VERSION ""

NS_ :

BS_:

BU_: BMS HVB BMU

BO_ 2282618902 BMU22_Vol_57: 8 BMU
 SG_ BMU22_Vol_57 : 7|16@0+ (0.001,0) [1|1] "V"  BMS
 SG_ BMU22_Vol_58 : 23|16@0+ (0.001,0) [1|1] "V"  BMS
 SG_ BMU22_Vol_59 : 39|16@0+ (0.001,0) [1|1] "V"  BMS
 SG_ BMU22_Vol_60 : 55|16@0+ (0.001,0) [1|1] "V"  BMS

BO_ 2282684438 BMU22_Vol_61: 8 BMU
 SG_ BMU22_Vol_61 : 7|16@0+ (0.001,0) [1|1] "V"  BMS
 SG_ BMU22_Vol_62 : 23|16@0+ (0.001,0) [1|1] "V"  BMS
 SG_ BMU22_Vol_63 : 39|16@0+ (0.001,0) [1|1] "V"  BMS
 SG_ BMU22_Vol_64 : 55|16@0+ (0.001,0) [1|1] "V"  BMS

BO_ 2282749974 BMU22_Vol_65: 8 BMU
 SG_ BMU22_Vol_65 : 7|16@0+ (0.001,0) [1|1] "V"  BMS
 SG_ BMU22_Vol_66 : 23|16@0+ (0.001,0) [1|1] "V"  BMS
 SG_ BMU22_Vol_67 : 39|16@0+ (0.001,0) [1|1] "V"  BMS
 SG_ BMU22_Vol_68 : 55|16@0+ (0.001,0) [1|1] "V"  BMS

BO_ 2282815510 BMU22_Vol_69: 8 BMU
 SG_ BMU22_Vol_69 : 7|16@0+ (0.001,0) [1|1] "V"  BMS
 SG_ BMU22_Vol_70 : 23|16@0+ (0.001,0) [1|1] "V"  BMS
 SG_ BMU22_Vol_71 : 39|16@0+ (0.001,0) [1|1] "V"  BMS
 SG_ BMU22_Vol_72 : 55|16@0+ (0.001,0) [1|1] "V"  BMS

BO_ 2282881046 BMU22_Vol_73: 8 BMU
 SG_ BMU22_Vol_73 : 7|16@0+ (0.001,0) [1|1] "V"  BMS
 SG_ BMU22_Vol_74 : 23|16@0+ (0.001,0) [1|1] "V"  BMS
 SG_ BMU22_Vol_75 : 39|16@0+ (0.001,0) [1|1] "V"  BMS
 SG_ BMU22_Vol_76 : 55|16@0+ (0.001,0) [1|1] "V"  BMS

BO_ 2282946582 BMU22_Vol_77: 8 BMU
 SG_ BMU22_Vol_77 : 7|16@0+ (0.001,0) [1|1] "V"  BMS
 SG_ BMU22_Vol_78 : 23|16@0+ (0.001,0) [1|1] "V"  BMS
 SG_ BMU22_Vol_79 : 39|16@0+ (0.001,0) [1|1] "V"  BMS
 SG_ BMU22_Vol_80 : 55|16@0+ (0.001,0) [1|1] "V"  BMS

BO_ 2283012118 BMU22_Vol_81: 8 BMU
 SG_ BMU22_Vol_81 : 7|16@0+ (0.001,0) [1|1] "V"  BMS
 SG_ BMU22_Vol_82 : 23|16@0+ (0.001,0) [1|1] "V"  BMS
 SG_ BMU22_Vol_83 : 39|16@0+ (0.001,0) [1|1] "V"  BMS
 SG_ BMU22_Vol_84 : 55|16@0+ (0.001,0) [1|1] "V"  BMS

BO_ 2283077654 BMU22_Vol_85: 8 BMU
 SG_ BMU22_Vol_85 : 7|16@0+ (0.001,0) [1|1] "V"  BMS
 SG_ BMU22_Vol_86 : 23|16@0+ (0.001,0) [1|1] "V"  BMS
 SG_ BMU22_Vol_87 : 39|16@0+ (0.001,0) [1|1] "V"  BMS
 SG_ BMU22_Vol_88 : 55|16@0+ (0.001,0) [1|1] "V"  BMS

BO_ 2283143190 BMU22_Vol_89: 8 BMU
 SG_ BMU22_Vol_89 : 7|16@0+ (0.001,0) [1|1] "V"  BMS
 SG_ BMU22_Vol_90 : 23|16@0+ (0.001,0) [1|1] "V"  BMS
 SG_ BMU22_Vol_91 : 39|16@0+ (0.001,0) [1|1] "V"  BMS
 SG_ BMU22_Vol_92 : 55|16@0+ (0.001,0) [1|1] "V"  BMS

BO_ 2283208726 BMU22_Vol_93: 8 BMU
 SG_ BMU22_Vol_93 : 7|16@0+ (0.001,0) [1|1] "V"  BMS
 SG_ BMU22_Vol_94 : 23|16@0+ (0.001,0) [1|1] "V"  BMS
 SG_ BMU22_Vol_95 : 39|16@0+ (0.001,0) [1|1] "V"  BMS
 SG_ BMU22_Vol_96 : 55|16@0+ (0.001,0) [1|1] "V"  BMS

BO_ 2281701399 BMU23_Vol_1: 8 BMU
 SG_ BMU23_Vol_1 : 7|16@0+ (0.001,0) [1|1] "V"  BMS
 SG_ BMU23_Vol_2 : 23|16@0+ (0.001,0) [1|1] "V"  BMS
 SG_ BMU23_Vol_3 : 39|16@0+ (0.001,0) [1|1] "V"  BMS
 SG_ BMU23_Vol_4 : 55|16@0+ (0.001,0) [1|1] "V"  BMS

BO_ 2281766935 BMU23_Vol_5: 8 BMU
 SG_ BMU23_Vol_5 : 7|16@0+ (0.001,0) [1|1] "V"  BMS
 SG_ BMU23_Vol_6 : 23|16@0+ (0.001,0) [1|1] "V"  BMS
 SG_ BMU23_Vol_7 : 39|16@0+ (0.001,0) [1|1] "V"  BMS
 SG_ BMU23_Vol_8 : 55|16@0+ (0.001,0) [1|1] "V"  BMS

BO_ 2281832471 BMU23_Vol_9: 8 BMU
 SG_ BMU23_Vol_9 : 7|16@0+ (0.001,0) [1|1] "V"  BMS
 SG_ BMU23_Vol_10 : 23|16@0+ (0.001,0) [1|1] "V"  BMS
 SG_ BMU23_Vol_11 : 39|16@0+ (0.001,0) [1|1] "V"  BMS
 SG_ BMU23_Vol_12 : 55|16@0+ (0.001,0) [1|1] "V"  BMS

BO_ 2281898007 BMU23_Vol_13: 8 BMU
 SG_ BMU23_Vol_13 : 7|16@0+ (0.001,0) [1|1] "V"  BMS
 SG_ BMU23_Vol_14 : 23|16@0+ (0.001,0) [1|1] "V"  BMS
 SG_ BMU23_Vol_15 : 39|16@0+ (0.001,0) [1|1] "V"  BMS
 SG_ BMU23_Vol_16 : 55|16@0+ (0.001,0) [1|1] "V"  BMS

BO_ 2281963543 BMU23_Vol_17: 8 BMU
 SG_ BMU23_Vol_17 : 7|16@0+ (0.001,0) [1|1] "V"  BMS
 SG_ BMU23_Vol_18 : 23|16@0+ (0.001,0) [1|1] "V"  BMS
 SG_ BMU23_Vol_19 : 39|16@0+ (0.001,0) [1|1] "V"  BMS
 SG_ BMU23_Vol_20 : 55|16@0+ (0.001,0) [1|1] "V"  BMS

BO_ 2282029079 BMU23_Vol_21: 8 BMU
 SG_ BMU23_Vol_21 : 7|16@0+ (0.001,0) [1|1] "V"  BMS
 SG_ BMU23_Vol_22 : 23|16@0+ (0.001,0) [1|1] "V"  BMS
 SG_ BMU23_Vol_23 : 39|16@0+ (0.001,0) [1|1] "V"  BMS
 SG_ BMU23_Vol_24 : 55|16@0+ (0.001,0) [1|1] "V"  BMS

BO_ 2282094615 BMU23_Vol_25: 8 BMU
 SG_ BMU23_Vol_25 : 7|16@0+ (0.001,0) [1|1] "V"  BMS
 SG_ BMU23_Vol_26 : 23|16@0+ (0.001,0) [1|1] "V"  BMS
 SG_ BMU23_Vol_27 : 39|16@0+ (0.001,0) [1|1] "V"  BMS
 SG_ BMU23_Vol_28 : 55|16@0+ (0.001,0) [1|1] "V"  BMS

BO_ 2282160151 BMU23_Vol_29: 8 BMU
 SG_ BMU23_Vol_29 : 7|16@0+ (0.001,0) [1|1] "V"  BMS
 SG_ BMU23_Vol_30 : 23|16@0+ (0.001,0) [1|1] "V"  BMS
 SG_ BMU23_Vol_31 : 39|16@0+ (0.001,0) [1|1] "V"  BMS
 SG_ BMU23_Vol_32 : 55|16@0+ (0.001,0) [1|1] "V"  BMS

BO_ 2282225687 BMU23_Vol_33: 8 BMU
 SG_ BMU23_Vol_33 : 7|16@0+ (0.001,0) [1|1] "V"  BMS
 SG_ BMU23_Vol_34 : 23|16@0+ (0.001,0) [1|1] "V"  BMS
 SG_ BMU23_Vol_35 : 39|16@0+ (0.001,0) [1|1] "V"  BMS
 SG_ BMU23_Vol_36 : 55|16@0+ (0.001,0) [1|1] "V"  BMS

BO_ 2282291223 BMU23_Vol_37: 8 BMU
 SG_ BMU23_Vol_37 : 7|16@0+ (0.001,0) [1|1] "V"  BMS
 SG_ BMU23_Vol_38 : 23|16@0+ (0.001,0) [1|1] "V"  BMS
 SG_ BMU23_Vol_39 : 39|16@0+ (0.001,0) [1|1] "V"  BMS
 SG_ BMU23_Vol_40 : 55|16@0+ (0.001,0) [1|1] "V"  BMS

BO_ 2282356759 BMU23_Vol_41: 8 BMU
 SG_ BMU23_Vol_41 : 7|16@0+ (0.001,0) [1|1] "V"  BMS
 SG_ BMU23_Vol_42 : 23|16@0+ (0.001,0) [1|1] "V"  BMS
 SG_ BMU23_Vol_43 : 39|16@0+ (0.001,0) [1|1] "V"  BMS
 SG_ BMU23_Vol_44 : 55|16@0+ (0.001,0) [1|1] "V"  BMS

BO_ 2282422295 BMU23_Vol_45: 8 BMU
 SG_ BMU23_Vol_45 : 7|16@0+ (0.001,0) [1|1] "V"  BMS
 SG_ BMU23_Vol_46 : 23|16@0+ (0.001,0) [1|1] "V"  BMS
 SG_ BMU23_Vol_47 : 39|16@0+ (0.001,0) [1|1] "V"  BMS
 SG_ BMU23_Vol_48 : 55|16@0+ (0.001,0) [1|1] "V"  BMS

BO_ 2282487831 BMU23_Vol_49: 8 BMU
 SG_ BMU23_Vol_49 : 7|16@0+ (0.001,0) [1|1] "V"  BMS
 SG_ BMU23_Vol_50 : 23|16@0+ (0.001,0) [1|1] "V"  BMS
 SG_ BMU23_Vol_51 : 39|16@0+ (0.001,0) [1|1] "V"  BMS
 SG_ BMU23_Vol_52 : 55|16@0+ (0.001,0) [1|1] "V"  BMS

BO_ 2282553367 BMU23_Vol_53: 8 BMU
 SG_ BMU23_Vol_53 : 7|16@0+ (0.001,0) [1|1] "V"  BMS
 SG_ BMU23_Vol_54 : 23|16@0+ (0.001,0) [1|1] "V"  BMS
 SG_ BMU23_Vol_55 : 39|16@0+ (0.001,0) [1|1] "V"  BMS
 SG_ BMU23_Vol_56 : 55|16@0+ (0.001,0) [1|1] "V"  BMS

BO_ 2282618903 BMU23_Vol_57: 8 BMU
 SG_ BMU23_Vol_57 : 7|16@0+ (0.001,0) [1|1] "V"  BMS
 SG_ BMU23_Vol_58 : 23|16@0+ (0.001,0) [1|1] "V"  BMS
 SG_ BMU23_Vol_59 : 39|16@0+ (0.001,0) [1|1] "V"  BMS
 SG_ BMU23_Vol_60 : 55|16@0+ (0.001,0) [1|1] "V"  BMS

BO_ 2282684439 BMU23_Vol_61: 8 BMU
 SG_ BMU23_Vol_61 : 7|16@0+ (0.001,0) [1|1] "V"  BMS
 SG_ BMU23_Vol_62 : 23|16@0+ (0.001,0) [1|1] "V"  BMS
 SG_ BMU23_Vol_63 : 39|16@0+ (0.001,0) [1|1] "V"  BMS
 SG_ BMU23_Vol_64 : 55|16@0+ (0.001,0) [1|1] "V"  BMS

BO_ 2282749975 BMU23_Vol_65: 8 BMU
 SG_ BMU23_Vol_65 : 7|16@0+ (0.001,0) [1|1] "V"  BMS
 SG_ BMU23_Vol_66 : 23|16@0+ (0.001,0) [1|1] "V"  BMS
 SG_ BMU23_Vol_67 : 39|16@0+ (0.001,0) [1|1] "V"  BMS
 SG_ BMU23_Vol_68 : 55|16@0+ (0.001,0) [1|1] "V"  BMS

BO_ 2282815511 BMU23_Vol_69: 8 BMU
 SG_ BMU23_Vol_69 : 7|16@0+ (0.001,0) [1|1] "V"  BMS
 SG_ BMU23_Vol_70 : 23|16@0+ (0.001,0) [1|1] "V"  BMS
 SG_ BMU23_Vol_71 : 39|16@0+ (0.001,0) [1|1] "V"  BMS
 SG_ BMU23_Vol_72 : 55|16@0+ (0.001,0) [1|1] "V"  BMS

BO_ 2282881047 BMU23_Vol_73: 8 BMU
 SG_ BMU23_Vol_73 : 7|16@0+ (0.001,0) [1|1] "V"  BMS
 SG_ BMU23_Vol_74 : 23|16@0+ (0.001,0) [1|1] "V"  BMS
 SG_ BMU23_Vol_75 : 39|16@0+ (0.001,0) [1|1] "V"  BMS
 SG_ BMU23_Vol_76 : 55|16@0+ (0.001,0) [1|1] "V"  BMS

BO_ 2282946583 BMU23_Vol_77: 8 BMU
 SG_ BMU23_Vol_77 : 7|16@0+ (0.001,0) [1|1] "V"  BMS
 SG_ BMU23_Vol_78 : 23|16@0+ (0.001,0) [1|1] "V"  BMS
 SG_ BMU23_Vol_79 : 39|16@0+ (0.001,0) [1|1] "V"  BMS
 SG_ BMU23_Vol_80 : 55|16@0+ (0.001,0) [1|1] "V"  BMS

BO_ 2283012119 BMU23_Vol_81: 8 BMU
 SG_ BMU23_Vol_81 : 7|16@0+ (0.001,0) [1|1] "V"  BMS
 SG_ BMU23_Vol_82 : 23|16@0+ (0.001,0) [1|1] "V"  BMS
 SG_ BMU23_Vol_83 : 39|16@0+ (0.001,0) [1|1] "V"  BMS
 SG_ BMU23_Vol_84 : 55|16@0+ (0.001,0) [1|1] "V"  BMS

BO_ 2283077655 BMU23_Vol_85: 8 BMU
 SG_ BMU23_Vol_85 : 7|16@0+ (0.001,0) [1|1] "V"  BMS
 SG_ BMU23_Vol_86 : 23|16@0+ (0.001,0) [1|1] "V"  BMS
 SG_ BMU23_Vol_87 : 39|16@0+ (0.001,0) [1|1] "V"  BMS
 SG_ BMU23_Vol_88 : 55|16@0+ (0.001,0) [1|1] "V"  BMS

BO_ 2283143191 BMU23_Vol_89: 8 BMU
 SG_ BMU23_Vol_89 : 7|16@0+ (0.001,0) [1|1] "V"  BMS
 SG_ BMU23_Vol_90 : 23|16@0+ (0.001,0) [1|1] "V"  BMS
 SG_ BMU23_Vol_91 : 39|16@0+ (0.001,0) [1|1] "V"  BMS
 SG_ BMU23_Vol_92 : 55|16@0+ (0.001,0) [1|1] "V"  BMS

BO_ 2283208727 BMU23_Vol_93: 8 BMU
 SG_ BMU23_Vol_93 : 7|16@0+ (0.001,0) [1|1] "V"  BMS
 SG_ BMU23_Vol_94 : 23|16@0+ (0.001,0) [1|1] "V"  BMS
 SG_ BMU23_Vol_95 : 39|16@0+ (0.001,0) [1|1] "V"  BMS
 SG_ BMU23_Vol_96 : 55|16@0+ (0.001,0) [1|1] "V"  BMS

BO_ 2281701400 BMU24_Vol_1: 8 BMU
 SG_ BMU24_Vol_1 : 7|16@0+ (0.001,0) [1|1] "V"  BMS
 SG_ BMU24_Vol_2 : 23|16@0+ (0.001,0) [1|1] "V"  BMS
 SG_ BMU24_Vol_3 : 39|16@0+ (0.001,0) [1|1] "V"  BMS
 SG_ BMU24_Vol_4 : 55|16@0+ (0.001,0) [1|1] "V"  BMS

BO_ 2281766936 BMU24_Vol_5: 8 BMU
 SG_ BMU24_Vol_5 : 7|16@0+ (0.001,0) [1|1] "V"  BMS
 SG_ BMU24_Vol_6 : 23|16@0+ (0.001,0) [1|1] "V"  BMS
 SG_ BMU24_Vol_7 : 39|16@0+ (0.001,0) [1|1] "V"  BMS
 SG_ BMU24_Vol_8 : 55|16@0+ (0.001,0) [1|1] "V"  BMS

BO_ 2281832472 BMU24_Vol_9: 8 BMU
 SG_ BMU24_Vol_9 : 7|16@0+ (0.001,0) [1|1] "V"  BMS
 SG_ BMU24_Vol_10 : 23|16@0+ (0.001,0) [1|1] "V"  BMS
 SG_ BMU24_Vol_11 : 39|16@0+ (0.001,0) [1|1] "V"  BMS
 SG_ BMU24_Vol_12 : 55|16@0+ (0.001,0) [1|1] "V"  BMS

BO_ 2281898008 BMU24_Vol_13: 8 BMU
 SG_ BMU24_Vol_13 : 7|16@0+ (0.001,0) [1|1] "V"  BMS
 SG_ BMU24_Vol_14 : 23|16@0+ (0.001,0) [1|1] "V"  BMS
 SG_ BMU24_Vol_15 : 39|16@0+ (0.001,0) [1|1] "V"  BMS
 SG_ BMU24_Vol_16 : 55|16@0+ (0.001,0) [1|1] "V"  BMS

BO_ 2281963544 BMU24_Vol_17: 8 BMU
 SG_ BMU24_Vol_17 : 7|16@0+ (0.001,0) [1|1] "V"  BMS
 SG_ BMU24_Vol_18 : 23|16@0+ (0.001,0) [1|1] "V"  BMS
 SG_ BMU24_Vol_19 : 39|16@0+ (0.001,0) [1|1] "V"  BMS
 SG_ BMU24_Vol_20 : 55|16@0+ (0.001,0) [1|1] "V"  BMS

BO_ 2282029080 BMU24_Vol_21: 8 BMU
 SG_ BMU24_Vol_21 : 7|16@0+ (0.001,0) [1|1] "V"  BMS
 SG_ BMU24_Vol_22 : 23|16@0+ (0.001,0) [1|1] "V"  BMS
 SG_ BMU24_Vol_23 : 39|16@0+ (0.001,0) [1|1] "V"  BMS
 SG_ BMU24_Vol_24 : 55|16@0+ (0.001,0) [1|1] "V"  BMS

BO_ 2282094616 BMU24_Vol_25: 8 BMU
 SG_ BMU24_Vol_25 : 7|16@0+ (0.001,0) [1|1] "V"  BMS
 SG_ BMU24_Vol_26 : 23|16@0+ (0.001,0) [1|1] "V"  BMS
 SG_ BMU24_Vol_27 : 39|16@0+ (0.001,0) [1|1] "V"  BMS
 SG_ BMU24_Vol_28 : 55|16@0+ (0.001,0) [1|1] "V"  BMS

BO_ 2282160152 BMU24_Vol_29: 8 BMU
 SG_ BMU24_Vol_29 : 7|16@0+ (0.001,0) [1|1] "V"  BMS
 SG_ BMU24_Vol_30 : 23|16@0+ (0.001,0) [1|1] "V"  BMS
 SG_ BMU24_Vol_31 : 39|16@0+ (0.001,0) [1|1] "V"  BMS
 SG_ BMU24_Vol_32 : 55|16@0+ (0.001,0) [1|1] "V"  BMS

BO_ 2282225688 BMU24_Vol_33: 8 BMU
 SG_ BMU24_Vol_33 : 7|16@0+ (0.001,0) [1|1] "V"  BMS
 SG_ BMU24_Vol_34 : 23|16@0+ (0.001,0) [1|1] "V"  BMS
 SG_ BMU24_Vol_35 : 39|16@0+ (0.001,0) [1|1] "V"  BMS
 SG_ BMU24_Vol_36 : 55|16@0+ (0.001,0) [1|1] "V"  BMS

BO_ 2282291224 BMU24_Vol_37: 8 BMU
 SG_ BMU24_Vol_37 : 7|16@0+ (0.001,0) [1|1] "V"  BMS
 SG_ BMU24_Vol_38 : 23|16@0+ (0.001,0) [1|1] "V"  BMS
 SG_ BMU24_Vol_39 : 39|16@0+ (0.001,0) [1|1] "V"  BMS
 SG_ BMU24_Vol_40 : 55|16@0+ (0.001,0) [1|1] "V"  BMS

BO_ 2282356760 BMU24_Vol_41: 8 BMU
 SG_ BMU24_Vol_41 : 7|16@0+ (0.001,0) [1|1] "V"  BMS
 SG_ BMU24_Vol_42 : 23|16@0+ (0.001,0) [1|1] "V"  BMS
 SG_ BMU24_Vol_43 : 39|16@0+ (0.001,0) [1|1] "V"  BMS
 SG_ BMU24_Vol_44 : 55|16@0+ (0.001,0) [1|1] "V"  BMS

BO_ 2282422296 BMU24_Vol_45: 8 BMU
 SG_ BMU24_Vol_45 : 7|16@0+ (0.001,0) [1|1] "V"  BMS
 SG_ BMU24_Vol_46 : 23|16@0+ (0.001,0) [1|1] "V"  BMS
 SG_ BMU24_Vol_47 : 39|16@0+ (0.001,0) [1|1] "V"  BMS
 SG_ BMU24_Vol_48 : 55|16@0+ (0.001,0) [1|1] "V"  BMS

BO_ 2282487832 BMU24_Vol_49: 8 BMU
 SG_ BMU24_Vol_49 : 7|16@0+ (0.001,0) [1|1] "V"  BMS
 SG_ BMU24_Vol_50 : 23|16@0+ (0.001,0) [1|1] "V"  BMS
 SG_ BMU24_Vol_51 : 39|16@0+ (0.001,0) [1|1] "V"  BMS
 SG_ BMU24_Vol_52 : 55|16@0+ (0.001,0) [1|1] "V"  BMS

BO_ 2282553368 BMU24_Vol_53: 8 BMU
 SG_ BMU24_Vol_53 : 7|16@0+ (0.001,0) [1|1] "V"  BMS
 SG_ BMU24_Vol_54 : 23|16@0+ (0.001,0) [1|1] "V"  BMS
 SG_ BMU24_Vol_55 : 39|16@0+ (0.001,0) [1|1] "V"  BMS
 SG_ BMU24_Vol_56 : 55|16@0+ (0.001,0) [1|1] "V"  BMS

BO_ 2282618904 BMU24_Vol_57: 8 BMU
 SG_ BMU24_Vol_57 : 7|16@0+ (0.001,0) [1|1] "V"  BMS
 SG_ BMU24_Vol_58 : 23|16@0+ (0.001,0) [1|1] "V"  BMS
 SG_ BMU24_Vol_59 : 39|16@0+ (0.001,0) [1|1] "V"  BMS
 SG_ BMU24_Vol_60 : 55|16@0+ (0.001,0) [1|1] "V"  BMS

BO_ 2282684440 BMU24_Vol_61: 8 BMU
 SG_ BMU24_Vol_61 : 7|16@0+ (0.001,0) [1|1] "V"  BMS
 SG_ BMU24_Vol_62 : 23|16@0+ (0.001,0) [1|1] "V"  BMS
 SG_ BMU24_Vol_63 : 39|16@0+ (0.001,0) [1|1] "V"  BMS
 SG_ BMU24_Vol_64 : 55|16@0+ (0.001,0) [1|1] "V"  BMS

BO_ 2282749976 BMU24_Vol_65: 8 BMU
 SG_ BMU24_Vol_65 : 7|16@0+ (0.001,0) [1|1] "V"  BMS
 SG_ BMU24_Vol_66 : 23|16@0+ (0.001,0) [1|1] "V"  BMS
 SG_ BMU24_Vol_67 : 39|16@0+ (0.001,0) [1|1] "V"  BMS
 SG_ BMU24_Vol_68 : 55|16@0+ (0.001,0) [1|1] "V"  BMS

BO_ 2282815512 BMU24_Vol_69: 8 BMU
 SG_ BMU24_Vol_69 : 7|16@0+ (0.001,0) [1|1] "V"  BMS
 SG_ BMU24_Vol_70 : 23|16@0+ (0.001,0) [1|1] "V"  BMS
 SG_ BMU24_Vol_71 : 39|16@0+ (0.001,0) [1|1] "V"  BMS
 SG_ BMU24_Vol_72 : 55|16@0+ (0.001,0) [1|1] "V"  BMS

BO_ 2282881048 BMU24_Vol_73: 8 BMU
 SG_ BMU24_Vol_73 : 7|16@0+ (0.001,0) [1|1] "V"  BMS
 SG_ BMU24_Vol_74 : 23|16@0+ (0.001,0) [1|1] "V"  BMS
 SG_ BMU24_Vol_75 : 39|16@0+ (0.001,0) [1|1] "V"  BMS
 SG_ BMU24_Vol_76 : 55|16@0+ (0.001,0) [1|1] "V"  BMS

BO_ 2282946584 BMU24_Vol_77: 8 BMU
 SG_ BMU24_Vol_77 : 7|16@0+ (0.001,0) [1|1] "V"  BMS
 SG_ BMU24_Vol_78 : 23|16@0+ (0.001,0) [1|1] "V"  BMS
 SG_ BMU24_Vol_79 : 39|16@0+ (0.001,0) [1|1] "V"  BMS
 SG_ BMU24_Vol_80 : 55|16@0+ (0.001,0) [1|1] "V"  BMS

BO_ 2283012120 BMU24_Vol_81: 8 BMU
 SG_ BMU24_Vol_81 : 7|16@0+ (0.001,0) [1|1] "V"  BMS
 SG_ BMU24_Vol_82 : 23|16@0+ (0.001,0) [1|1] "V"  BMS
 SG_ BMU24_Vol_83 : 39|16@0+ (0.001,0) [1|1] "V"  BMS
 SG_ BMU24_Vol_84 : 55|16@0+ (0.001,0) [1|1] "V"  BMS

BO_ 2283077656 BMU24_Vol_85: 8 BMU
 SG_ BMU24_Vol_85 : 7|16@0+ (0.001,0) [1|1] "V"  BMS
 SG_ BMU24_Vol_86 : 23|16@0+ (0.001,0) [1|1] "V"  BMS
 SG_ BMU24_Vol_87 : 39|16@0+ (0.001,0) [1|1] "V"  BMS
 SG_ BMU24_Vol_88 : 55|16@0+ (0.001,0) [1|1] "V"  BMS

BO_ 2283143192 BMU24_Vol_89: 8 BMU
 SG_ BMU24_Vol_89 : 7|16@0+ (0.001,0) [1|1] "V"  BMS
 SG_ BMU24_Vol_90 : 23|16@0+ (0.001,0) [1|1] "V"  BMS
 SG_ BMU24_Vol_91 : 39|16@0+ (0.001,0) [1|1] "V"  BMS
 SG_ BMU24_Vol_92 : 55|16@0+ (0.001,0) [1|1] "V"  BMS

BO_ 2283208728 BMU24_Vol_93: 8 BMU
 SG_ BMU24_Vol_93 : 7|16@0+ (0.001,0) [1|1] "V"  BMS
 SG_ BMU24_Vol_94 : 23|16@0+ (0.001,0) [1|1] "V"  BMS
 SG_ BMU24_Vol_95 : 39|16@0+ (0.001,0) [1|1] "V"  BMS
 SG_ BMU24_Vol_96 : 55|16@0+ (0.001,0) [1|1] "V"  BMS

BO_ 2281701401 BMU25_Vol_1: 8 BMU
 SG_ BMU25_Vol_1 : 7|16@0+ (0.001,0) [1|1] "V"  BMS
 SG_ BMU25_Vol_2 : 23|16@0+ (0.001,0) [1|1] "V"  BMS
 SG_ BMU25_Vol_3 : 39|16@0+ (0.001,0) [1|1] "V"  BMS
 SG_ BMU25_Vol_4 : 55|16@0+ (0.001,0) [1|1] "V"  BMS

BO_ 2281766937 BMU25_Vol_5: 8 BMU
 SG_ BMU25_Vol_5 : 7|16@0+ (0.001,0) [1|1] "V"  BMS
 SG_ BMU25_Vol_6 : 23|16@0+ (0.001,0) [1|1] "V"  BMS
 SG_ BMU25_Vol_7 : 39|16@0+ (0.001,0) [1|1] "V"  BMS
 SG_ BMU25_Vol_8 : 55|16@0+ (0.001,0) [1|1] "V"  BMS

BO_ 2281832473 BMU25_Vol_9: 8 BMU
 SG_ BMU25_Vol_9 : 7|16@0+ (0.001,0) [1|1] "V"  BMS
 SG_ BMU25_Vol_10 : 23|16@0+ (0.001,0) [1|1] "V"  BMS
 SG_ BMU25_Vol_11 : 39|16@0+ (0.001,0) [1|1] "V"  BMS
 SG_ BMU25_Vol_12 : 55|16@0+ (0.001,0) [1|1] "V"  BMS

BO_ 2281898009 BMU25_Vol_13: 8 BMU
 SG_ BMU25_Vol_13 : 7|16@0+ (0.001,0) [1|1] "V"  BMS
 SG_ BMU25_Vol_14 : 23|16@0+ (0.001,0) [1|1] "V"  BMS
 SG_ BMU25_Vol_15 : 39|16@0+ (0.001,0) [1|1] "V"  BMS
 SG_ BMU25_Vol_16 : 55|16@0+ (0.001,0) [1|1] "V"  BMS

BO_ 2281963545 BMU25_Vol_17: 8 BMU
 SG_ BMU25_Vol_17 : 7|16@0+ (0.001,0) [1|1] "V"  BMS
 SG_ BMU25_Vol_18 : 23|16@0+ (0.001,0) [1|1] "V"  BMS
 SG_ BMU25_Vol_19 : 39|16@0+ (0.001,0) [1|1] "V"  BMS
 SG_ BMU25_Vol_20 : 55|16@0+ (0.001,0) [1|1] "V"  BMS

BO_ 2282029081 BMU25_Vol_21: 8 BMU
 SG_ BMU25_Vol_21 : 7|16@0+ (0.001,0) [1|1] "V"  BMS
 SG_ BMU25_Vol_22 : 23|16@0+ (0.001,0) [1|1] "V"  BMS
 SG_ BMU25_Vol_23 : 39|16@0+ (0.001,0) [1|1] "V"  BMS
 SG_ BMU25_Vol_24 : 55|16@0+ (0.001,0) [1|1] "V"  BMS

BO_ 2282094617 BMU25_Vol_25: 8 BMU
 SG_ BMU25_Vol_25 : 7|16@0+ (0.001,0) [1|1] "V"  BMS
 SG_ BMU25_Vol_26 : 23|16@0+ (0.001,0) [1|1] "V"  BMS
 SG_ BMU25_Vol_27 : 39|16@0+ (0.001,0) [1|1] "V"  BMS
 SG_ BMU25_Vol_28 : 55|16@0+ (0.001,0) [1|1] "V"  BMS

BO_ 2282160153 BMU25_Vol_29: 8 BMU
 SG_ BMU25_Vol_29 : 7|16@0+ (0.001,0) [1|1] "V"  BMS
 SG_ BMU25_Vol_30 : 23|16@0+ (0.001,0) [1|1] "V"  BMS
 SG_ BMU25_Vol_31 : 39|16@0+ (0.001,0) [1|1] "V"  BMS
 SG_ BMU25_Vol_32 : 55|16@0+ (0.001,0) [1|1] "V"  BMS

BO_ 2282225689 BMU25_Vol_33: 8 BMU
 SG_ BMU25_Vol_33 : 7|16@0+ (0.001,0) [1|1] "V"  BMS
 SG_ BMU25_Vol_34 : 23|16@0+ (0.001,0) [1|1] "V"  BMS
 SG_ BMU25_Vol_35 : 39|16@0+ (0.001,0) [1|1] "V"  BMS
 SG_ BMU25_Vol_36 : 55|16@0+ (0.001,0) [1|1] "V"  BMS

BO_ 2282291225 BMU25_Vol_37: 8 BMU
 SG_ BMU25_Vol_37 : 7|16@0+ (0.001,0) [1|1] "V"  BMS
 SG_ BMU25_Vol_38 : 23|16@0+ (0.001,0) [1|1] "V"  BMS
 SG_ BMU25_Vol_39 : 39|16@0+ (0.001,0) [1|1] "V"  BMS
 SG_ BMU25_Vol_40 : 55|16@0+ (0.001,0) [1|1] "V"  BMS

BO_ 2282356761 BMU25_Vol_41: 8 BMU
 SG_ BMU25_Vol_41 : 7|16@0+ (0.001,0) [1|1] "V"  BMS
 SG_ BMU25_Vol_42 : 23|16@0+ (0.001,0) [1|1] "V"  BMS
 SG_ BMU25_Vol_43 : 39|16@0+ (0.001,0) [1|1] "V"  BMS
 SG_ BMU25_Vol_44 : 55|16@0+ (0.001,0) [1|1] "V"  BMS

BO_ 2282422297 BMU25_Vol_45: 8 BMU
 SG_ BMU25_Vol_45 : 7|16@0+ (0.001,0) [1|1] "V"  BMS
 SG_ BMU25_Vol_46 : 23|16@0+ (0.001,0) [1|1] "V"  BMS
 SG_ BMU25_Vol_47 : 39|16@0+ (0.001,0) [1|1] "V"  BMS
 SG_ BMU25_Vol_48 : 55|16@0+ (0.001,0) [1|1] "V"  BMS

BO_ 2282487833 BMU25_Vol_49: 8 BMU
 SG_ BMU25_Vol_49 : 7|16@0+ (0.001,0) [1|1] "V"  BMS
 SG_ BMU25_Vol_50 : 23|16@0+ (0.001,0) [1|1] "V"  BMS
 SG_ BMU25_Vol_51 : 39|16@0+ (0.001,0) [1|1] "V"  BMS
 SG_ BMU25_Vol_52 : 55|16@0+ (0.001,0) [1|1] "V"  BMS

BO_ 2282553369 BMU25_Vol_53: 8 BMU
 SG_ BMU25_Vol_53 : 7|16@0+ (0.001,0) [1|1] "V"  BMS
 SG_ BMU25_Vol_54 : 23|16@0+ (0.001,0) [1|1] "V"  BMS
 SG_ BMU25_Vol_55 : 39|16@0+ (0.001,0) [1|1] "V"  BMS
 SG_ BMU25_Vol_56 : 55|16@0+ (0.001,0) [1|1] "V"  BMS

BO_ 2282618905 BMU25_Vol_57: 8 BMU
 SG_ BMU25_Vol_57 : 7|16@0+ (0.001,0) [1|1] "V"  BMS
 SG_ BMU25_Vol_58 : 23|16@0+ (0.001,0) [1|1] "V"  BMS
 SG_ BMU25_Vol_59 : 39|16@0+ (0.001,0) [1|1] "V"  BMS
 SG_ BMU25_Vol_60 : 55|16@0+ (0.001,0) [1|1] "V"  BMS

BO_ 2282684441 BMU25_Vol_61: 8 BMU
 SG_ BMU25_Vol_61 : 7|16@0+ (0.001,0) [1|1] "V"  BMS
 SG_ BMU25_Vol_62 : 23|16@0+ (0.001,0) [1|1] "V"  BMS
 SG_ BMU25_Vol_63 : 39|16@0+ (0.001,0) [1|1] "V"  BMS
 SG_ BMU25_Vol_64 : 55|16@0+ (0.001,0) [1|1] "V"  BMS

BO_ 2282749977 BMU25_Vol_65: 8 BMU
 SG_ BMU25_Vol_65 : 7|16@0+ (0.001,0) [1|1] "V"  BMS
 SG_ BMU25_Vol_66 : 23|16@0+ (0.001,0) [1|1] "V"  BMS
 SG_ BMU25_Vol_67 : 39|16@0+ (0.001,0) [1|1] "V"  BMS
 SG_ BMU25_Vol_68 : 55|16@0+ (0.001,0) [1|1] "V"  BMS

BO_ 2282815513 BMU25_Vol_69: 8 BMU
 SG_ BMU25_Vol_69 : 7|16@0+ (0.001,0) [1|1] "V"  BMS
 SG_ BMU25_Vol_70 : 23|16@0+ (0.001,0) [1|1] "V"  BMS
 SG_ BMU25_Vol_71 : 39|16@0+ (0.001,0) [1|1] "V"  BMS
 SG_ BMU25_Vol_72 : 55|16@0+ (0.001,0) [1|1] "V"  BMS

BO_ 2282881049 BMU25_Vol_73: 8 BMU
 SG_ BMU25_Vol_73 : 7|16@0+ (0.001,0) [1|1] "V"  BMS
 SG_ BMU25_Vol_74 : 23|16@0+ (0.001,0) [1|1] "V"  BMS
 SG_ BMU25_Vol_75 : 39|16@0+ (0.001,0) [1|1] "V"  BMS
 SG_ BMU25_Vol_76 : 55|16@0+ (0.001,0) [1|1] "V"  BMS

BO_ 2282946585 BMU25_Vol_77: 8 BMU
 SG_ BMU25_Vol_77 : 7|16@0+ (0.001,0) [1|1] "V"  BMS
 SG_ BMU25_Vol_78 : 23|16@0+ (0.001,0) [1|1] "V"  BMS
 SG_ BMU25_Vol_79 : 39|16@0+ (0.001,0) [1|1] "V"  BMS
 SG_ BMU25_Vol_80 : 55|16@0+ (0.001,0) [1|1] "V"  BMS

BO_ 2283012121 BMU25_Vol_81: 8 BMU
 SG_ BMU25_Vol_81 : 7|16@0+ (0.001,0) [1|1] "V"  BMS
 SG_ BMU25_Vol_82 : 23|16@0+ (0.001,0) [1|1] "V"  BMS
 SG_ BMU25_Vol_83 : 39|16@0+ (0.001,0) [1|1] "V"  BMS
 SG_ BMU25_Vol_84 : 55|16@0+ (0.001,0) [1|1] "V"  BMS

BO_ 2283077657 BMU25_Vol_85: 8 BMU
 SG_ BMU25_Vol_85 : 7|16@0+ (0.001,0) [1|1] "V"  BMS
 SG_ BMU25_Vol_86 : 23|16@0+ (0.001,0) [1|1] "V"  BMS
 SG_ BMU25_Vol_87 : 39|16@0+ (0.001,0) [1|1] "V"  BMS
 SG_ BMU25_Vol_88 : 55|16@0+ (0.001,0) [1|1] "V"  BMS

BO_ 2283143193 BMU25_Vol_89: 8 BMU
 SG_ BMU25_Vol_89 : 7|16@0+ (0.001,0) [1|1] "V"  BMS
 SG_ BMU25_Vol_90 : 23|16@0+ (0.001,0) [1|1] "V"  BMS
 SG_ BMU25_Vol_91 : 39|16@0+ (0.001,0) [1|1] "V"  BMS
 SG_ BMU25_Vol_92 : 55|16@0+ (0.001,0) [1|1] "V"  BMS

BO_ 2283208729 BMU25_Vol_93: 8 BMU
 SG_ BMU25_Vol_93 : 7|16@0+ (0.001,0) [1|1] "V"  BMS
 SG_ BMU25_Vol_94 : 23|16@0+ (0.001,0) [1|1] "V"  BMS
 SG_ BMU25_Vol_95 : 39|16@0+ (0.001,0) [1|1] "V"  BMS
 SG_ BMU25_Vol_96 : 55|16@0+ (0.001,0) [1|1] "V"  BMS

BO_ 2281701402 BMU26_Vol_1: 8 BMU
 SG_ BMU26_Vol_1 : 7|16@0+ (0.001,0) [1|1] "V"  BMS
 SG_ BMU26_Vol_2 : 23|16@0+ (0.001,0) [1|1] "V"  BMS
 SG_ BMU26_Vol_3 : 39|16@0+ (0.001,0) [1|1] "V"  BMS
 SG_ BMU26_Vol_4 : 55|16@0+ (0.001,0) [1|1] "V"  BMS

BO_ 2281766938 BMU26_Vol_5: 8 BMU
 SG_ BMU26_Vol_5 : 7|16@0+ (0.001,0) [1|1] "V"  BMS
 SG_ BMU26_Vol_6 : 23|16@0+ (0.001,0) [1|1] "V"  BMS
 SG_ BMU26_Vol_7 : 39|16@0+ (0.001,0) [1|1] "V"  BMS
 SG_ BMU26_Vol_8 : 55|16@0+ (0.001,0) [1|1] "V"  BMS

BO_ 2281832474 BMU26_Vol_9: 8 BMU
 SG_ BMU26_Vol_9 : 7|16@0+ (0.001,0) [1|1] "V"  BMS
 SG_ BMU26_Vol_10 : 23|16@0+ (0.001,0) [1|1] "V"  BMS
 SG_ BMU26_Vol_11 : 39|16@0+ (0.001,0) [1|1] "V"  BMS
 SG_ BMU26_Vol_12 : 55|16@0+ (0.001,0) [1|1] "V"  BMS

BO_ 2281898010 BMU26_Vol_13: 8 BMU
 SG_ BMU26_Vol_13 : 7|16@0+ (0.001,0) [1|1] "V"  BMS
 SG_ BMU26_Vol_14 : 23|16@0+ (0.001,0) [1|1] "V"  BMS
 SG_ BMU26_Vol_15 : 39|16@0+ (0.001,0) [1|1] "V"  BMS
 SG_ BMU26_Vol_16 : 55|16@0+ (0.001,0) [1|1] "V"  BMS

BO_ 2281963546 BMU26_Vol_17: 8 BMU
 SG_ BMU26_Vol_17 : 7|16@0+ (0.001,0) [1|1] "V"  BMS
 SG_ BMU26_Vol_18 : 23|16@0+ (0.001,0) [1|1] "V"  BMS
 SG_ BMU26_Vol_19 : 39|16@0+ (0.001,0) [1|1] "V"  BMS
 SG_ BMU26_Vol_20 : 55|16@0+ (0.001,0) [1|1] "V"  BMS

BO_ 2282029082 BMU26_Vol_21: 8 BMU
 SG_ BMU26_Vol_21 : 7|16@0+ (0.001,0) [1|1] "V"  BMS
 SG_ BMU26_Vol_22 : 23|16@0+ (0.001,0) [1|1] "V"  BMS
 SG_ BMU26_Vol_23 : 39|16@0+ (0.001,0) [1|1] "V"  BMS
 SG_ BMU26_Vol_24 : 55|16@0+ (0.001,0) [1|1] "V"  BMS

BO_ 2282094618 BMU26_Vol_25: 8 BMU
 SG_ BMU26_Vol_25 : 7|16@0+ (0.001,0) [1|1] "V"  BMS
 SG_ BMU26_Vol_26 : 23|16@0+ (0.001,0) [1|1] "V"  BMS
 SG_ BMU26_Vol_27 : 39|16@0+ (0.001,0) [1|1] "V"  BMS
 SG_ BMU26_Vol_28 : 55|16@0+ (0.001,0) [1|1] "V"  BMS

BO_ 2282160154 BMU26_Vol_29: 8 BMU
 SG_ BMU26_Vol_29 : 7|16@0+ (0.001,0) [1|1] "V"  BMS
 SG_ BMU26_Vol_30 : 23|16@0+ (0.001,0) [1|1] "V"  BMS
 SG_ BMU26_Vol_31 : 39|16@0+ (0.001,0) [1|1] "V"  BMS
 SG_ BMU26_Vol_32 : 55|16@0+ (0.001,0) [1|1] "V"  BMS

BO_ 2282225690 BMU26_Vol_33: 8 BMU
 SG_ BMU26_Vol_33 : 7|16@0+ (0.001,0) [1|1] "V"  BMS
 SG_ BMU26_Vol_34 : 23|16@0+ (0.001,0) [1|1] "V"  BMS
 SG_ BMU26_Vol_35 : 39|16@0+ (0.001,0) [1|1] "V"  BMS
 SG_ BMU26_Vol_36 : 55|16@0+ (0.001,0) [1|1] "V"  BMS

BO_ 2282291226 BMU26_Vol_37: 8 BMU
 SG_ BMU26_Vol_37 : 7|16@0+ (0.001,0) [1|1] "V"  BMS
 SG_ BMU26_Vol_38 : 23|16@0+ (0.001,0) [1|1] "V"  BMS
 SG_ BMU26_Vol_39 : 39|16@0+ (0.001,0) [1|1] "V"  BMS
 SG_ BMU26_Vol_40 : 55|16@0+ (0.001,0) [1|1] "V"  BMS

BO_ 2282356762 BMU26_Vol_41: 8 BMU
 SG_ BMU26_Vol_41 : 7|16@0+ (0.001,0) [1|1] "V"  BMS
 SG_ BMU26_Vol_42 : 23|16@0+ (0.001,0) [1|1] "V"  BMS
 SG_ BMU26_Vol_43 : 39|16@0+ (0.001,0) [1|1] "V"  BMS
 SG_ BMU26_Vol_44 : 55|16@0+ (0.001,0) [1|1] "V"  BMS

BO_ 2282422298 BMU26_Vol_45: 8 BMU
 SG_ BMU26_Vol_45 : 7|16@0+ (0.001,0) [1|1] "V"  BMS
 SG_ BMU26_Vol_46 : 23|16@0+ (0.001,0) [1|1] "V"  BMS
 SG_ BMU26_Vol_47 : 39|16@0+ (0.001,0) [1|1] "V"  BMS
 SG_ BMU26_Vol_48 : 55|16@0+ (0.001,0) [1|1] "V"  BMS

BO_ 2282487834 BMU26_Vol_49: 8 BMU
 SG_ BMU26_Vol_49 : 7|16@0+ (0.001,0) [1|1] "V"  BMS
 SG_ BMU26_Vol_50 : 23|16@0+ (0.001,0) [1|1] "V"  BMS
 SG_ BMU26_Vol_51 : 39|16@0+ (0.001,0) [1|1] "V"  BMS
 SG_ BMU26_Vol_52 : 55|16@0+ (0.001,0) [1|1] "V"  BMS

BO_ 2282553370 BMU26_Vol_53: 8 BMU
 SG_ BMU26_Vol_53 : 7|16@0+ (0.001,0) [1|1] "V"  BMS
 SG_ BMU26_Vol_54 : 23|16@0+ (0.001,0) [1|1] "V"  BMS
 SG_ BMU26_Vol_55 : 39|16@0+ (0.001,0) [1|1] "V"  BMS
 SG_ BMU26_Vol_56 : 55|16@0+ (0.001,0) [1|1] "V"  BMS

BO_ 2282618906 BMU26_Vol_57: 8 BMU
 SG_ BMU26_Vol_57 : 7|16@0+ (0.001,0) [1|1] "V"  BMS
 SG_ BMU26_Vol_58 : 23|16@0+ (0.001,0) [1|1] "V"  BMS
 SG_ BMU26_Vol_59 : 39|16@0+ (0.001,0) [1|1] "V"  BMS
 SG_ BMU26_Vol_60 : 55|16@0+ (0.001,0) [1|1] "V"  BMS

BO_ 2282684442 BMU26_Vol_61: 8 BMU
 SG_ BMU26_Vol_61 : 7|16@0+ (0.001,0) [1|1] "V"  BMS
 SG_ BMU26_Vol_62 : 23|16@0+ (0.001,0) [1|1] "V"  BMS
 SG_ BMU26_Vol_63 : 39|16@0+ (0.001,0) [1|1] "V"  BMS
 SG_ BMU26_Vol_64 : 55|16@0+ (0.001,0) [1|1] "V"  BMS

BO_ 2282749978 BMU26_Vol_65: 8 BMU
 SG_ BMU26_Vol_65 : 7|16@0+ (0.001,0) [1|1] "V"  BMS
 SG_ BMU26_Vol_66 : 23|16@0+ (0.001,0) [1|1] "V"  BMS
 SG_ BMU26_Vol_67 : 39|16@0+ (0.001,0) [1|1] "V"  BMS
 SG_ BMU26_Vol_68 : 55|16@0+ (0.001,0) [1|1] "V"  BMS

BO_ 2282815514 BMU26_Vol_69: 8 BMU
 SG_ BMU26_Vol_69 : 7|16@0+ (0.001,0) [1|1] "V"  BMS
 SG_ BMU26_Vol_70 : 23|16@0+ (0.001,0) [1|1] "V"  BMS
 SG_ BMU26_Vol_71 : 39|16@0+ (0.001,0) [1|1] "V"  BMS
 SG_ BMU26_Vol_72 : 55|16@0+ (0.001,0) [1|1] "V"  BMS

BO_ 2282881050 BMU26_Vol_73: 8 BMU
 SG_ BMU26_Vol_73 : 7|16@0+ (0.001,0) [1|1] "V"  BMS
 SG_ BMU26_Vol_74 : 23|16@0+ (0.001,0) [1|1] "V"  BMS
 SG_ BMU26_Vol_75 : 39|16@0+ (0.001,0) [1|1] "V"  BMS
 SG_ BMU26_Vol_76 : 55|16@0+ (0.001,0) [1|1] "V"  BMS

BO_ 2282946586 BMU26_Vol_77: 8 BMU
 SG_ BMU26_Vol_77 : 7|16@0+ (0.001,0) [1|1] "V"  BMS
 SG_ BMU26_Vol_78 : 23|16@0+ (0.001,0) [1|1] "V"  BMS
 SG_ BMU26_Vol_79 : 39|16@0+ (0.001,0) [1|1] "V"  BMS
 SG_ BMU26_Vol_80 : 55|16@0+ (0.001,0) [1|1] "V"  BMS

BO_ 2283012122 BMU26_Vol_81: 8 BMU
 SG_ BMU26_Vol_81 : 7|16@0+ (0.001,0) [1|1] "V"  BMS
 SG_ BMU26_Vol_82 : 23|16@0+ (0.001,0) [1|1] "V"  BMS
 SG_ BMU26_Vol_83 : 39|16@0+ (0.001,0) [1|1] "V"  BMS
 SG_ BMU26_Vol_84 : 55|16@0+ (0.001,0) [1|1] "V"  BMS

BO_ 2283077658 BMU26_Vol_85: 8 BMU
 SG_ BMU26_Vol_85 : 7|16@0+ (0.001,0) [1|1] "V"  BMS
 SG_ BMU26_Vol_86 : 23|16@0+ (0.001,0) [1|1] "V"  BMS
 SG_ BMU26_Vol_87 : 39|16@0+ (0.001,0) [1|1] "V"  BMS
 SG_ BMU26_Vol_88 : 55|16@0+ (0.001,0) [1|1] "V"  BMS

BO_ 2283143194 BMU26_Vol_89: 8 BMU
 SG_ BMU26_Vol_89 : 7|16@0+ (0.001,0) [1|1] "V"  BMS
 SG_ BMU26_Vol_90 : 23|16@0+ (0.001,0) [1|1] "V"  BMS
 SG_ BMU26_Vol_91 : 39|16@0+ (0.001,0) [1|1] "V"  BMS
 SG_ BMU26_Vol_92 : 55|16@0+ (0.001,0) [1|1] "V"  BMS

BO_ 2283208730 BMU26_Vol_93: 8 BMU
 SG_ BMU26_Vol_93 : 7|16@0+ (0.001,0) [1|1] "V"  BMS
 SG_ BMU26_Vol_94 : 23|16@0+ (0.001,0) [1|1] "V"  BMS
 SG_ BMU26_Vol_95 : 39|16@0+ (0.001,0) [1|1] "V"  BMS
 SG_ BMU26_Vol_96 : 55|16@0+ (0.001,0) [1|1] "V"  BMS

BO_ 2281701403 BMU27_Vol_1: 8 BMU
 SG_ BMU27_Vol_1 : 7|16@0+ (0.001,0) [1|1] "V"  BMS
 SG_ BMU27_Vol_2 : 23|16@0+ (0.001,0) [1|1] "V"  BMS
 SG_ BMU27_Vol_3 : 39|16@0+ (0.001,0) [1|1] "V"  BMS
 SG_ BMU27_Vol_4 : 55|16@0+ (0.001,0) [1|1] "V"  BMS

BO_ 2281766939 BMU27_Vol_5: 8 BMU
 SG_ BMU27_Vol_5 : 7|16@0+ (0.001,0) [1|1] "V"  BMS
 SG_ BMU27_Vol_6 : 23|16@0+ (0.001,0) [1|1] "V"  BMS
 SG_ BMU27_Vol_7 : 39|16@0+ (0.001,0) [1|1] "V"  BMS
 SG_ BMU27_Vol_8 : 55|16@0+ (0.001,0) [1|1] "V"  BMS

BO_ 2281832475 BMU27_Vol_9: 8 BMU
 SG_ BMU27_Vol_9 : 7|16@0+ (0.001,0) [1|1] "V"  BMS
 SG_ BMU27_Vol_10 : 23|16@0+ (0.001,0) [1|1] "V"  BMS
 SG_ BMU27_Vol_11 : 39|16@0+ (0.001,0) [1|1] "V"  BMS
 SG_ BMU27_Vol_12 : 55|16@0+ (0.001,0) [1|1] "V"  BMS

BO_ 2281898011 BMU27_Vol_13: 8 BMU
 SG_ BMU27_Vol_13 : 7|16@0+ (0.001,0) [1|1] "V"  BMS
 SG_ BMU27_Vol_14 : 23|16@0+ (0.001,0) [1|1] "V"  BMS
 SG_ BMU27_Vol_15 : 39|16@0+ (0.001,0) [1|1] "V"  BMS
 SG_ BMU27_Vol_16 : 55|16@0+ (0.001,0) [1|1] "V"  BMS

BO_ 2281963547 BMU27_Vol_17: 8 BMU
 SG_ BMU27_Vol_17 : 7|16@0+ (0.001,0) [1|1] "V"  BMS
 SG_ BMU27_Vol_18 : 23|16@0+ (0.001,0) [1|1] "V"  BMS
 SG_ BMU27_Vol_19 : 39|16@0+ (0.001,0) [1|1] "V"  BMS
 SG_ BMU27_Vol_20 : 55|16@0+ (0.001,0) [1|1] "V"  BMS

BO_ 2282029083 BMU27_Vol_21: 8 BMU
 SG_ BMU27_Vol_21 : 7|16@0+ (0.001,0) [1|1] "V"  BMS
 SG_ BMU27_Vol_22 : 23|16@0+ (0.001,0) [1|1] "V"  BMS
 SG_ BMU27_Vol_23 : 39|16@0+ (0.001,0) [1|1] "V"  BMS
 SG_ BMU27_Vol_24 : 55|16@0+ (0.001,0) [1|1] "V"  BMS

BO_ 2282094619 BMU27_Vol_25: 8 BMU
 SG_ BMU27_Vol_25 : 7|16@0+ (0.001,0) [1|1] "V"  BMS
 SG_ BMU27_Vol_26 : 23|16@0+ (0.001,0) [1|1] "V"  BMS
 SG_ BMU27_Vol_27 : 39|16@0+ (0.001,0) [1|1] "V"  BMS
 SG_ BMU27_Vol_28 : 55|16@0+ (0.001,0) [1|1] "V"  BMS

BO_ 2282160155 BMU27_Vol_29: 8 BMU
 SG_ BMU27_Vol_29 : 7|16@0+ (0.001,0) [1|1] "V"  BMS
 SG_ BMU27_Vol_30 : 23|16@0+ (0.001,0) [1|1] "V"  BMS
 SG_ BMU27_Vol_31 : 39|16@0+ (0.001,0) [1|1] "V"  BMS
 SG_ BMU27_Vol_32 : 55|16@0+ (0.001,0) [1|1] "V"  BMS

BO_ 2282225691 BMU27_Vol_33: 8 BMU
 SG_ BMU27_Vol_33 : 7|16@0+ (0.001,0) [1|1] "V"  BMS
 SG_ BMU27_Vol_34 : 23|16@0+ (0.001,0) [1|1] "V"  BMS
 SG_ BMU27_Vol_35 : 39|16@0+ (0.001,0) [1|1] "V"  BMS
 SG_ BMU27_Vol_36 : 55|16@0+ (0.001,0) [1|1] "V"  BMS

BO_ 2282291227 BMU27_Vol_37: 8 BMU
 SG_ BMU27_Vol_37 : 7|16@0+ (0.001,0) [1|1] "V"  BMS
 SG_ BMU27_Vol_38 : 23|16@0+ (0.001,0) [1|1] "V"  BMS
 SG_ BMU27_Vol_39 : 39|16@0+ (0.001,0) [1|1] "V"  BMS
 SG_ BMU27_Vol_40 : 55|16@0+ (0.001,0) [1|1] "V"  BMS

BO_ 2282356763 BMU27_Vol_41: 8 BMU
 SG_ BMU27_Vol_41 : 7|16@0+ (0.001,0) [1|1] "V"  BMS
 SG_ BMU27_Vol_42 : 23|16@0+ (0.001,0) [1|1] "V"  BMS
 SG_ BMU27_Vol_43 : 39|16@0+ (0.001,0) [1|1] "V"  BMS
 SG_ BMU27_Vol_44 : 55|16@0+ (0.001,0) [1|1] "V"  BMS

BO_ 2282422299 BMU27_Vol_45: 8 BMU
 SG_ BMU27_Vol_45 : 7|16@0+ (0.001,0) [1|1] "V"  BMS
 SG_ BMU27_Vol_46 : 23|16@0+ (0.001,0) [1|1] "V"  BMS
 SG_ BMU27_Vol_47 : 39|16@0+ (0.001,0) [1|1] "V"  BMS
 SG_ BMU27_Vol_48 : 55|16@0+ (0.001,0) [1|1] "V"  BMS

BO_ 2282487835 BMU27_Vol_49: 8 BMU
 SG_ BMU27_Vol_49 : 7|16@0+ (0.001,0) [1|1] "V"  BMS
 SG_ BMU27_Vol_50 : 23|16@0+ (0.001,0) [1|1] "V"  BMS
 SG_ BMU27_Vol_51 : 39|16@0+ (0.001,0) [1|1] "V"  BMS
 SG_ BMU27_Vol_52 : 55|16@0+ (0.001,0) [1|1] "V"  BMS

BO_ 2282553371 BMU27_Vol_53: 8 BMU
 SG_ BMU27_Vol_53 : 7|16@0+ (0.001,0) [1|1] "V"  BMS
 SG_ BMU27_Vol_54 : 23|16@0+ (0.001,0) [1|1] "V"  BMS
 SG_ BMU27_Vol_55 : 39|16@0+ (0.001,0) [1|1] "V"  BMS
 SG_ BMU27_Vol_56 : 55|16@0+ (0.001,0) [1|1] "V"  BMS

BO_ 2282618907 BMU27_Vol_57: 8 BMU
 SG_ BMU27_Vol_57 : 7|16@0+ (0.001,0) [1|1] "V"  BMS
 SG_ BMU27_Vol_58 : 23|16@0+ (0.001,0) [1|1] "V"  BMS
 SG_ BMU27_Vol_59 : 39|16@0+ (0.001,0) [1|1] "V"  BMS
 SG_ BMU27_Vol_60 : 55|16@0+ (0.001,0) [1|1] "V"  BMS

BO_ 2282684443 BMU27_Vol_61: 8 BMU
 SG_ BMU27_Vol_61 : 7|16@0+ (0.001,0) [1|1] "V"  BMS
 SG_ BMU27_Vol_62 : 23|16@0+ (0.001,0) [1|1] "V"  BMS
 SG_ BMU27_Vol_63 : 39|16@0+ (0.001,0) [1|1] "V"  BMS
 SG_ BMU27_Vol_64 : 55|16@0+ (0.001,0) [1|1] "V"  BMS

BO_ 2282749979 BMU27_Vol_65: 8 BMU
 SG_ BMU27_Vol_65 : 7|16@0+ (0.001,0) [1|1] "V"  BMS
 SG_ BMU27_Vol_66 : 23|16@0+ (0.001,0) [1|1] "V"  BMS
 SG_ BMU27_Vol_67 : 39|16@0+ (0.001,0) [1|1] "V"  BMS
 SG_ BMU27_Vol_68 : 55|16@0+ (0.001,0) [1|1] "V"  BMS

BO_ 2282815515 BMU27_Vol_69: 8 BMU
 SG_ BMU27_Vol_69 : 7|16@0+ (0.001,0) [1|1] "V"  BMS
 SG_ BMU27_Vol_70 : 23|16@0+ (0.001,0) [1|1] "V"  BMS
 SG_ BMU27_Vol_71 : 39|16@0+ (0.001,0) [1|1] "V"  BMS
 SG_ BMU27_Vol_72 : 55|16@0+ (0.001,0) [1|1] "V"  BMS

BO_ 2282881051 BMU27_Vol_73: 8 BMU
 SG_ BMU27_Vol_73 : 7|16@0+ (0.001,0) [1|1] "V"  BMS
 SG_ BMU27_Vol_74 : 23|16@0+ (0.001,0) [1|1] "V"  BMS
 SG_ BMU27_Vol_75 : 39|16@0+ (0.001,0) [1|1] "V"  BMS
 SG_ BMU27_Vol_76 : 55|16@0+ (0.001,0) [1|1] "V"  BMS

BO_ 2282946587 BMU27_Vol_77: 8 BMU
 SG_ BMU27_Vol_77 : 7|16@0+ (0.001,0) [1|1] "V"  BMS
 SG_ BMU27_Vol_78 : 23|16@0+ (0.001,0) [1|1] "V"  BMS
 SG_ BMU27_Vol_79 : 39|16@0+ (0.001,0) [1|1] "V"  BMS
 SG_ BMU27_Vol_80 : 55|16@0+ (0.001,0) [1|1] "V"  BMS

BO_ 2283012123 BMU27_Vol_81: 8 BMU
 SG_ BMU27_Vol_81 : 7|16@0+ (0.001,0) [1|1] "V"  BMS
 SG_ BMU27_Vol_82 : 23|16@0+ (0.001,0) [1|1] "V"  BMS
 SG_ BMU27_Vol_83 : 39|16@0+ (0.001,0) [1|1] "V"  BMS
 SG_ BMU27_Vol_84 : 55|16@0+ (0.001,0) [1|1] "V"  BMS

BO_ 2283077659 BMU27_Vol_85: 8 BMU
 SG_ BMU27_Vol_85 : 7|16@0+ (0.001,0) [1|1] "V"  BMS
 SG_ BMU27_Vol_86 : 23|16@0+ (0.001,0) [1|1] "V"  BMS
 SG_ BMU27_Vol_87 : 39|16@0+ (0.001,0) [1|1] "V"  BMS
 SG_ BMU27_Vol_88 : 55|16@0+ (0.001,0) [1|1] "V"  BMS

BO_ 2283143195 BMU27_Vol_89: 8 BMU
 SG_ BMU27_Vol_89 : 7|16@0+ (0.001,0) [1|1] "V"  BMS
 SG_ BMU27_Vol_90 : 23|16@0+ (0.001,0) [1|1] "V"  BMS
 SG_ BMU27_Vol_91 : 39|16@0+ (0.001,0) [1|1] "V"  BMS
 SG_ BMU27_Vol_92 : 55|16@0+ (0.001,0) [1|1] "V"  BMS

BO_ 2283208731 BMU27_Vol_93: 8 BMU
 SG_ BMU27_Vol_93 : 7|16@0+ (0.001,0) [1|1] "V"  BMS
 SG_ BMU27_Vol_94 : 23|16@0+ (0.001,0) [1|1] "V"  BMS
 SG_ BMU27_Vol_95 : 39|16@0+ (0.001,0) [1|1] "V"  BMS
 SG_ BMU27_Vol_96 : 55|16@0+ (0.001,0) [1|1] "V"  BMS

BO_ 2281701404 BMU28_Vol_1: 8 BMU
 SG_ BMU28_Vol_1 : 7|16@0+ (0.001,0) [1|1] "V"  BMS
 SG_ BMU28_Vol_2 : 23|16@0+ (0.001,0) [1|1] "V"  BMS
 SG_ BMU28_Vol_3 : 39|16@0+ (0.001,0) [1|1] "V"  BMS
 SG_ BMU28_Vol_4 : 55|16@0+ (0.001,0) [1|1] "V"  BMS

BO_ 2281766940 BMU28_Vol_5: 8 BMU
 SG_ BMU28_Vol_5 : 7|16@0+ (0.001,0) [1|1] "V"  BMS
 SG_ BMU28_Vol_6 : 23|16@0+ (0.001,0) [1|1] "V"  BMS
 SG_ BMU28_Vol_7 : 39|16@0+ (0.001,0) [1|1] "V"  BMS
 SG_ BMU28_Vol_8 : 55|16@0+ (0.001,0) [1|1] "V"  BMS

BO_ 2281832476 BMU28_Vol_9: 8 BMU
 SG_ BMU28_Vol_9 : 7|16@0+ (0.001,0) [1|1] "V"  BMS
 SG_ BMU28_Vol_10 : 23|16@0+ (0.001,0) [1|1] "V"  BMS
 SG_ BMU28_Vol_11 : 39|16@0+ (0.001,0) [1|1] "V"  BMS
 SG_ BMU28_Vol_12 : 55|16@0+ (0.001,0) [1|1] "V"  BMS

BO_ 2281898012 BMU28_Vol_13: 8 BMU
 SG_ BMU28_Vol_13 : 7|16@0+ (0.001,0) [1|1] "V"  BMS
 SG_ BMU28_Vol_14 : 23|16@0+ (0.001,0) [1|1] "V"  BMS
 SG_ BMU28_Vol_15 : 39|16@0+ (0.001,0) [1|1] "V"  BMS
 SG_ BMU28_Vol_16 : 55|16@0+ (0.001,0) [1|1] "V"  BMS

BO_ 2281963548 BMU28_Vol_17: 8 BMU
 SG_ BMU28_Vol_17 : 7|16@0+ (0.001,0) [1|1] "V"  BMS
 SG_ BMU28_Vol_18 : 23|16@0+ (0.001,0) [1|1] "V"  BMS
 SG_ BMU28_Vol_19 : 39|16@0+ (0.001,0) [1|1] "V"  BMS
 SG_ BMU28_Vol_20 : 55|16@0+ (0.001,0) [1|1] "V"  BMS

BO_ 2282029084 BMU28_Vol_21: 8 BMU
 SG_ BMU28_Vol_21 : 7|16@0+ (0.001,0) [1|1] "V"  BMS
 SG_ BMU28_Vol_22 : 23|16@0+ (0.001,0) [1|1] "V"  BMS
 SG_ BMU28_Vol_23 : 39|16@0+ (0.001,0) [1|1] "V"  BMS
 SG_ BMU28_Vol_24 : 55|16@0+ (0.001,0) [1|1] "V"  BMS

BO_ 2282094620 BMU28_Vol_25: 8 BMU
 SG_ BMU28_Vol_25 : 7|16@0+ (0.001,0) [1|1] "V"  BMS
 SG_ BMU28_Vol_26 : 23|16@0+ (0.001,0) [1|1] "V"  BMS
 SG_ BMU28_Vol_27 : 39|16@0+ (0.001,0) [1|1] "V"  BMS
 SG_ BMU28_Vol_28 : 55|16@0+ (0.001,0) [1|1] "V"  BMS

BO_ 2282160156 BMU28_Vol_29: 8 BMU
 SG_ BMU28_Vol_29 : 7|16@0+ (0.001,0) [1|1] "V"  BMS
 SG_ BMU28_Vol_30 : 23|16@0+ (0.001,0) [1|1] "V"  BMS
 SG_ BMU28_Vol_31 : 39|16@0+ (0.001,0) [1|1] "V"  BMS
 SG_ BMU28_Vol_32 : 55|16@0+ (0.001,0) [1|1] "V"  BMS

BO_ 2282225692 BMU28_Vol_33: 8 BMU
 SG_ BMU28_Vol_33 : 7|16@0+ (0.001,0) [1|1] "V"  BMS
 SG_ BMU28_Vol_34 : 23|16@0+ (0.001,0) [1|1] "V"  BMS
 SG_ BMU28_Vol_35 : 39|16@0+ (0.001,0) [1|1] "V"  BMS
 SG_ BMU28_Vol_36 : 55|16@0+ (0.001,0) [1|1] "V"  BMS

BO_ 2282291228 BMU28_Vol_37: 8 BMU
 SG_ BMU28_Vol_37 : 7|16@0+ (0.001,0) [1|1] "V"  BMS
 SG_ BMU28_Vol_38 : 23|16@0+ (0.001,0) [1|1] "V"  BMS
 SG_ BMU28_Vol_39 : 39|16@0+ (0.001,0) [1|1] "V"  BMS
 SG_ BMU28_Vol_40 : 55|16@0+ (0.001,0) [1|1] "V"  BMS

BO_ 2282356764 BMU28_Vol_41: 8 BMU
 SG_ BMU28_Vol_41 : 7|16@0+ (0.001,0) [1|1] "V"  BMS
 SG_ BMU28_Vol_42 : 23|16@0+ (0.001,0) [1|1] "V"  BMS
 SG_ BMU28_Vol_43 : 39|16@0+ (0.001,0) [1|1] "V"  BMS
 SG_ BMU28_Vol_44 : 55|16@0+ (0.001,0) [1|1] "V"  BMS

BO_ 2282422300 BMU28_Vol_45: 8 BMU
 SG_ BMU28_Vol_45 : 7|16@0+ (0.001,0) [1|1] "V"  BMS
 SG_ BMU28_Vol_46 : 23|16@0+ (0.001,0) [1|1] "V"  BMS
 SG_ BMU28_Vol_47 : 39|16@0+ (0.001,0) [1|1] "V"  BMS
 SG_ BMU28_Vol_48 : 55|16@0+ (0.001,0) [1|1] "V"  BMS

BO_ 2282487836 BMU28_Vol_49: 8 BMU
 SG_ BMU28_Vol_49 : 7|16@0+ (0.001,0) [1|1] "V"  BMS
 SG_ BMU28_Vol_50 : 23|16@0+ (0.001,0) [1|1] "V"  BMS
 SG_ BMU28_Vol_51 : 39|16@0+ (0.001,0) [1|1] "V"  BMS
 SG_ BMU28_Vol_52 : 55|16@0+ (0.001,0) [1|1] "V"  BMS

BO_ 2282553372 BMU28_Vol_53: 8 BMU
 SG_ BMU28_Vol_53 : 7|16@0+ (0.001,0) [1|1] "V"  BMS
 SG_ BMU28_Vol_54 : 23|16@0+ (0.001,0) [1|1] "V"  BMS
 SG_ BMU28_Vol_55 : 39|16@0+ (0.001,0) [1|1] "V"  BMS
 SG_ BMU28_Vol_56 : 55|16@0+ (0.001,0) [1|1] "V"  BMS

BO_ 2282618908 BMU28_Vol_57: 8 BMU
 SG_ BMU28_Vol_57 : 7|16@0+ (0.001,0) [1|1] "V"  BMS
 SG_ BMU28_Vol_58 : 23|16@0+ (0.001,0) [1|1] "V"  BMS
 SG_ BMU28_Vol_59 : 39|16@0+ (0.001,0) [1|1] "V"  BMS
 SG_ BMU28_Vol_60 : 55|16@0+ (0.001,0) [1|1] "V"  BMS

BO_ 2282684444 BMU28_Vol_61: 8 BMU
 SG_ BMU28_Vol_61 : 7|16@0+ (0.001,0) [1|1] "V"  BMS
 SG_ BMU28_Vol_62 : 23|16@0+ (0.001,0) [1|1] "V"  BMS
 SG_ BMU28_Vol_63 : 39|16@0+ (0.001,0) [1|1] "V"  BMS
 SG_ BMU28_Vol_64 : 55|16@0+ (0.001,0) [1|1] "V"  BMS

BO_ 2282749980 BMU28_Vol_65: 8 BMU
 SG_ BMU28_Vol_65 : 7|16@0+ (0.001,0) [1|1] "V"  BMS
 SG_ BMU28_Vol_66 : 23|16@0+ (0.001,0) [1|1] "V"  BMS
 SG_ BMU28_Vol_67 : 39|16@0+ (0.001,0) [1|1] "V"  BMS
 SG_ BMU28_Vol_68 : 55|16@0+ (0.001,0) [1|1] "V"  BMS

BO_ 2282815516 BMU28_Vol_69: 8 BMU
 SG_ BMU28_Vol_69 : 7|16@0+ (0.001,0) [1|1] "V"  BMS
 SG_ BMU28_Vol_70 : 23|16@0+ (0.001,0) [1|1] "V"  BMS
 SG_ BMU28_Vol_71 : 39|16@0+ (0.001,0) [1|1] "V"  BMS
 SG_ BMU28_Vol_72 : 55|16@0+ (0.001,0) [1|1] "V"  BMS

BO_ 2282881052 BMU28_Vol_73: 8 BMU
 SG_ BMU28_Vol_73 : 7|16@0+ (0.001,0) [1|1] "V"  BMS
 SG_ BMU28_Vol_74 : 23|16@0+ (0.001,0) [1|1] "V"  BMS
 SG_ BMU28_Vol_75 : 39|16@0+ (0.001,0) [1|1] "V"  BMS
 SG_ BMU28_Vol_76 : 55|16@0+ (0.001,0) [1|1] "V"  BMS

BO_ 2282946588 BMU28_Vol_77: 8 BMU
 SG_ BMU28_Vol_77 : 7|16@0+ (0.001,0) [1|1] "V"  BMS
 SG_ BMU28_Vol_78 : 23|16@0+ (0.001,0) [1|1] "V"  BMS
 SG_ BMU28_Vol_79 : 39|16@0+ (0.001,0) [1|1] "V"  BMS
 SG_ BMU28_Vol_80 : 55|16@0+ (0.001,0) [1|1] "V"  BMS

BO_ 2283012124 BMU28_Vol_81: 8 BMU
 SG_ BMU28_Vol_81 : 7|16@0+ (0.001,0) [1|1] "V"  BMS
 SG_ BMU28_Vol_82 : 23|16@0+ (0.001,0) [1|1] "V"  BMS
 SG_ BMU28_Vol_83 : 39|16@0+ (0.001,0) [1|1] "V"  BMS
 SG_ BMU28_Vol_84 : 55|16@0+ (0.001,0) [1|1] "V"  BMS

BO_ 2283077660 BMU28_Vol_85: 8 BMU
 SG_ BMU28_Vol_85 : 7|16@0+ (0.001,0) [1|1] "V"  BMS
 SG_ BMU28_Vol_86 : 23|16@0+ (0.001,0) [1|1] "V"  BMS
 SG_ BMU28_Vol_87 : 39|16@0+ (0.001,0) [1|1] "V"  BMS
 SG_ BMU28_Vol_88 : 55|16@0+ (0.001,0) [1|1] "V"  BMS

BO_ 2283143196 BMU28_Vol_89: 8 BMU
 SG_ BMU28_Vol_89 : 7|16@0+ (0.001,0) [1|1] "V"  BMS
 SG_ BMU28_Vol_90 : 23|16@0+ (0.001,0) [1|1] "V"  BMS
 SG_ BMU28_Vol_91 : 39|16@0+ (0.001,0) [1|1] "V"  BMS
 SG_ BMU28_Vol_92 : 55|16@0+ (0.001,0) [1|1] "V"  BMS

BO_ 2283208732 BMU28_Vol_93: 8 BMU
 SG_ BMU28_Vol_93 : 7|16@0+ (0.001,0) [1|1] "V"  BMS
 SG_ BMU28_Vol_94 : 23|16@0+ (0.001,0) [1|1] "V"  BMS
 SG_ BMU28_Vol_95 : 39|16@0+ (0.001,0) [1|1] "V"  BMS
 SG_ BMU28_Vol_96 : 55|16@0+ (0.001,0) [1|1] "V"  BMS

BO_ 2281701405 BMU29_Vol_1: 8 BMU
 SG_ BMU29_Vol_1 : 7|16@0+ (0.001,0) [1|1] "V"  BMS
 SG_ BMU29_Vol_2 : 23|16@0+ (0.001,0) [1|1] "V"  BMS
 SG_ BMU29_Vol_3 : 39|16@0+ (0.001,0) [1|1] "V"  BMS
 SG_ BMU29_Vol_4 : 55|16@0+ (0.001,0) [1|1] "V"  BMS

BO_ 2281766941 BMU29_Vol_5: 8 BMU
 SG_ BMU29_Vol_5 : 7|16@0+ (0.001,0) [1|1] "V"  BMS
 SG_ BMU29_Vol_6 : 23|16@0+ (0.001,0) [1|1] "V"  BMS
 SG_ BMU29_Vol_7 : 39|16@0+ (0.001,0) [1|1] "V"  BMS
 SG_ BMU29_Vol_8 : 55|16@0+ (0.001,0) [1|1] "V"  BMS

BO_ 2281832477 BMU29_Vol_9: 8 BMU
 SG_ BMU29_Vol_9 : 7|16@0+ (0.001,0) [1|1] "V"  BMS
 SG_ BMU29_Vol_10 : 23|16@0+ (0.001,0) [1|1] "V"  BMS
 SG_ BMU29_Vol_11 : 39|16@0+ (0.001,0) [1|1] "V"  BMS
 SG_ BMU29_Vol_12 : 55|16@0+ (0.001,0) [1|1] "V"  BMS

BO_ 2281898013 BMU29_Vol_13: 8 BMU
 SG_ BMU29_Vol_13 : 7|16@0+ (0.001,0) [1|1] "V"  BMS
 SG_ BMU29_Vol_14 : 23|16@0+ (0.001,0) [1|1] "V"  BMS
 SG_ BMU29_Vol_15 : 39|16@0+ (0.001,0) [1|1] "V"  BMS
 SG_ BMU29_Vol_16 : 55|16@0+ (0.001,0) [1|1] "V"  BMS

BO_ 2281963549 BMU29_Vol_17: 8 BMU
 SG_ BMU29_Vol_17 : 7|16@0+ (0.001,0) [1|1] "V"  BMS
 SG_ BMU29_Vol_18 : 23|16@0+ (0.001,0) [1|1] "V"  BMS
 SG_ BMU29_Vol_19 : 39|16@0+ (0.001,0) [1|1] "V"  BMS
 SG_ BMU29_Vol_20 : 55|16@0+ (0.001,0) [1|1] "V"  BMS

BO_ 2282029085 BMU29_Vol_21: 8 BMU
 SG_ BMU29_Vol_21 : 7|16@0+ (0.001,0) [1|1] "V"  BMS
 SG_ BMU29_Vol_22 : 23|16@0+ (0.001,0) [1|1] "V"  BMS
 SG_ BMU29_Vol_23 : 39|16@0+ (0.001,0) [1|1] "V"  BMS
 SG_ BMU29_Vol_24 : 55|16@0+ (0.001,0) [1|1] "V"  BMS

BO_ 2282094621 BMU29_Vol_25: 8 BMU
 SG_ BMU29_Vol_25 : 7|16@0+ (0.001,0) [1|1] "V"  BMS
 SG_ BMU29_Vol_26 : 23|16@0+ (0.001,0) [1|1] "V"  BMS
 SG_ BMU29_Vol_27 : 39|16@0+ (0.001,0) [1|1] "V"  BMS
 SG_ BMU29_Vol_28 : 55|16@0+ (0.001,0) [1|1] "V"  BMS

BO_ 2282160157 BMU29_Vol_29: 8 BMU
 SG_ BMU29_Vol_29 : 7|16@0+ (0.001,0) [1|1] "V"  BMS
 SG_ BMU29_Vol_30 : 23|16@0+ (0.001,0) [1|1] "V"  BMS
 SG_ BMU29_Vol_31 : 39|16@0+ (0.001,0) [1|1] "V"  BMS
 SG_ BMU29_Vol_32 : 55|16@0+ (0.001,0) [1|1] "V"  BMS

BO_ 2282225693 BMU29_Vol_33: 8 BMU
 SG_ BMU29_Vol_33 : 7|16@0+ (0.001,0) [1|1] "V"  BMS
 SG_ BMU29_Vol_34 : 23|16@0+ (0.001,0) [1|1] "V"  BMS
 SG_ BMU29_Vol_35 : 39|16@0+ (0.001,0) [1|1] "V"  BMS
 SG_ BMU29_Vol_36 : 55|16@0+ (0.001,0) [1|1] "V"  BMS

BO_ 2282291229 BMU29_Vol_37: 8 BMU
 SG_ BMU29_Vol_37 : 7|16@0+ (0.001,0) [1|1] "V"  BMS
 SG_ BMU29_Vol_38 : 23|16@0+ (0.001,0) [1|1] "V"  BMS
 SG_ BMU29_Vol_39 : 39|16@0+ (0.001,0) [1|1] "V"  BMS
 SG_ BMU29_Vol_40 : 55|16@0+ (0.001,0) [1|1] "V"  BMS

BO_ 2282356765 BMU29_Vol_41: 8 BMU
 SG_ BMU29_Vol_41 : 7|16@0+ (0.001,0) [1|1] "V"  BMS
 SG_ BMU29_Vol_42 : 23|16@0+ (0.001,0) [1|1] "V"  BMS
 SG_ BMU29_Vol_43 : 39|16@0+ (0.001,0) [1|1] "V"  BMS
 SG_ BMU29_Vol_44 : 55|16@0+ (0.001,0) [1|1] "V"  BMS

BO_ 2282422301 BMU29_Vol_45: 8 BMU
 SG_ BMU29_Vol_45 : 7|16@0+ (0.001,0) [1|1] "V"  BMS
 SG_ BMU29_Vol_46 : 23|16@0+ (0.001,0) [1|1] "V"  BMS
 SG_ BMU29_Vol_47 : 39|16@0+ (0.001,0) [1|1] "V"  BMS
 SG_ BMU29_Vol_48 : 55|16@0+ (0.001,0) [1|1] "V"  BMS

BO_ 2282487837 BMU29_Vol_49: 8 BMU
 SG_ BMU29_Vol_49 : 7|16@0+ (0.001,0) [1|1] "V"  BMS
 SG_ BMU29_Vol_50 : 23|16@0+ (0.001,0) [1|1] "V"  BMS
 SG_ BMU29_Vol_51 : 39|16@0+ (0.001,0) [1|1] "V"  BMS
 SG_ BMU29_Vol_52 : 55|16@0+ (0.001,0) [1|1] "V"  BMS

BO_ 2282553373 BMU29_Vol_53: 8 BMU
 SG_ BMU29_Vol_53 : 7|16@0+ (0.001,0) [1|1] "V"  BMS
 SG_ BMU29_Vol_54 : 23|16@0+ (0.001,0) [1|1] "V"  BMS
 SG_ BMU29_Vol_55 : 39|16@0+ (0.001,0) [1|1] "V"  BMS
 SG_ BMU29_Vol_56 : 55|16@0+ (0.001,0) [1|1] "V"  BMS

BO_ 2282618909 BMU29_Vol_57: 8 BMU
 SG_ BMU29_Vol_57 : 7|16@0+ (0.001,0) [1|1] "V"  BMS
 SG_ BMU29_Vol_58 : 23|16@0+ (0.001,0) [1|1] "V"  BMS
 SG_ BMU29_Vol_59 : 39|16@0+ (0.001,0) [1|1] "V"  BMS
 SG_ BMU29_Vol_60 : 55|16@0+ (0.001,0) [1|1] "V"  BMS

BO_ 2282684445 BMU29_Vol_61: 8 BMU
 SG_ BMU29_Vol_61 : 7|16@0+ (0.001,0) [1|1] "V"  BMS
 SG_ BMU29_Vol_62 : 23|16@0+ (0.001,0) [1|1] "V"  BMS
 SG_ BMU29_Vol_63 : 39|16@0+ (0.001,0) [1|1] "V"  BMS
 SG_ BMU29_Vol_64 : 55|16@0+ (0.001,0) [1|1] "V"  BMS

BO_ 2282749981 BMU29_Vol_65: 8 BMU
 SG_ BMU29_Vol_65 : 7|16@0+ (0.001,0) [1|1] "V"  BMS
 SG_ BMU29_Vol_66 : 23|16@0+ (0.001,0) [1|1] "V"  BMS
 SG_ BMU29_Vol_67 : 39|16@0+ (0.001,0) [1|1] "V"  BMS
 SG_ BMU29_Vol_68 : 55|16@0+ (0.001,0) [1|1] "V"  BMS

BO_ 2282815517 BMU29_Vol_69: 8 BMU
 SG_ BMU29_Vol_69 : 7|16@0+ (0.001,0) [1|1] "V"  BMS
 SG_ BMU29_Vol_70 : 23|16@0+ (0.001,0) [1|1] "V"  BMS
 SG_ BMU29_Vol_71 : 39|16@0+ (0.001,0) [1|1] "V"  BMS
 SG_ BMU29_Vol_72 : 55|16@0+ (0.001,0) [1|1] "V"  BMS

BO_ 2282881053 BMU29_Vol_73: 8 BMU
 SG_ BMU29_Vol_73 : 7|16@0+ (0.001,0) [1|1] "V"  BMS
 SG_ BMU29_Vol_74 : 23|16@0+ (0.001,0) [1|1] "V"  BMS
 SG_ BMU29_Vol_75 : 39|16@0+ (0.001,0) [1|1] "V"  BMS
 SG_ BMU29_Vol_76 : 55|16@0+ (0.001,0) [1|1] "V"  BMS

BO_ 2282946589 BMU29_Vol_77: 8 BMU
 SG_ BMU29_Vol_77 : 7|16@0+ (0.001,0) [1|1] "V"  BMS
 SG_ BMU29_Vol_78 : 23|16@0+ (0.001,0) [1|1] "V"  BMS
 SG_ BMU29_Vol_79 : 39|16@0+ (0.001,0) [1|1] "V"  BMS
 SG_ BMU29_Vol_80 : 55|16@0+ (0.001,0) [1|1] "V"  BMS

BO_ 2283012125 BMU29_Vol_81: 8 BMU
 SG_ BMU29_Vol_81 : 7|16@0+ (0.001,0) [1|1] "V"  BMS
 SG_ BMU29_Vol_82 : 23|16@0+ (0.001,0) [1|1] "V"  BMS
 SG_ BMU29_Vol_83 : 39|16@0+ (0.001,0) [1|1] "V"  BMS
 SG_ BMU29_Vol_84 : 55|16@0+ (0.001,0) [1|1] "V"  BMS

BO_ 2283077661 BMU29_Vol_85: 8 BMU
 SG_ BMU29_Vol_85 : 7|16@0+ (0.001,0) [1|1] "V"  BMS
 SG_ BMU29_Vol_86 : 23|16@0+ (0.001,0) [1|1] "V"  BMS
 SG_ BMU29_Vol_87 : 39|16@0+ (0.001,0) [1|1] "V"  BMS
 SG_ BMU29_Vol_88 : 55|16@0+ (0.001,0) [1|1] "V"  BMS

BO_ 2283143197 BMU29_Vol_89: 8 BMU
 SG_ BMU29_Vol_89 : 7|16@0+ (0.001,0) [1|1] "V"  BMS
 SG_ BMU29_Vol_90 : 23|16@0+ (0.001,0) [1|1] "V"  BMS
 SG_ BMU29_Vol_91 : 39|16@0+ (0.001,0) [1|1] "V"  BMS
 SG_ BMU29_Vol_92 : 55|16@0+ (0.001,0) [1|1] "V"  BMS

BO_ 2283208733 BMU29_Vol_93: 8 BMU
 SG_ BMU29_Vol_93 : 7|16@0+ (0.001,0) [1|1] "V"  BMS
 SG_ BMU29_Vol_94 : 23|16@0+ (0.001,0) [1|1] "V"  BMS
 SG_ BMU29_Vol_95 : 39|16@0+ (0.001,0) [1|1] "V"  BMS
 SG_ BMU29_Vol_96 : 55|16@0+ (0.001,0) [1|1] "V"  BMS

BO_ 2281701406 BMU30_Vol_1: 8 BMU
 SG_ BMU30_Vol_1 : 7|16@0+ (0.001,0) [1|1] "V"  BMS
 SG_ BMU30_Vol_2 : 23|16@0+ (0.001,0) [1|1] "V"  BMS
 SG_ BMU30_Vol_3 : 39|16@0+ (0.001,0) [1|1] "V"  BMS
 SG_ BMU30_Vol_4 : 55|16@0+ (0.001,0) [1|1] "V"  BMS

BO_ 2281766942 BMU30_Vol_5: 8 BMU
 SG_ BMU30_Vol_5 : 7|16@0+ (0.001,0) [1|1] "V"  BMS
 SG_ BMU30_Vol_6 : 23|16@0+ (0.001,0) [1|1] "V"  BMS
 SG_ BMU30_Vol_7 : 39|16@0+ (0.001,0) [1|1] "V"  BMS
 SG_ BMU30_Vol_8 : 55|16@0+ (0.001,0) [1|1] "V"  BMS

BO_ 2281832478 BMU30_Vol_9: 8 BMU
 SG_ BMU30_Vol_9 : 7|16@0+ (0.001,0) [1|1] "V"  BMS
 SG_ BMU30_Vol_10 : 23|16@0+ (0.001,0) [1|1] "V"  BMS
 SG_ BMU30_Vol_11 : 39|16@0+ (0.001,0) [1|1] "V"  BMS
 SG_ BMU30_Vol_12 : 55|16@0+ (0.001,0) [1|1] "V"  BMS

BO_ 2281898014 BMU30_Vol_13: 8 BMU
 SG_ BMU30_Vol_13 : 7|16@0+ (0.001,0) [1|1] "V"  BMS
 SG_ BMU30_Vol_14 : 23|16@0+ (0.001,0) [1|1] "V"  BMS
 SG_ BMU30_Vol_15 : 39|16@0+ (0.001,0) [1|1] "V"  BMS
 SG_ BMU30_Vol_16 : 55|16@0+ (0.001,0) [1|1] "V"  BMS

BO_ 2281963550 BMU30_Vol_17: 8 BMU
 SG_ BMU30_Vol_17 : 7|16@0+ (0.001,0) [1|1] "V"  BMS
 SG_ BMU30_Vol_18 : 23|16@0+ (0.001,0) [1|1] "V"  BMS
 SG_ BMU30_Vol_19 : 39|16@0+ (0.001,0) [1|1] "V"  BMS
 SG_ BMU30_Vol_20 : 55|16@0+ (0.001,0) [1|1] "V"  BMS

BO_ 2282029086 BMU30_Vol_21: 8 BMU
 SG_ BMU30_Vol_21 : 7|16@0+ (0.001,0) [1|1] "V"  BMS
 SG_ BMU30_Vol_22 : 23|16@0+ (0.001,0) [1|1] "V"  BMS
 SG_ BMU30_Vol_23 : 39|16@0+ (0.001,0) [1|1] "V"  BMS
 SG_ BMU30_Vol_24 : 55|16@0+ (0.001,0) [1|1] "V"  BMS

BO_ 2282094622 BMU30_Vol_25: 8 BMU
 SG_ BMU30_Vol_25 : 7|16@0+ (0.001,0) [1|1] "V"  BMS
 SG_ BMU30_Vol_26 : 23|16@0+ (0.001,0) [1|1] "V"  BMS
 SG_ BMU30_Vol_27 : 39|16@0+ (0.001,0) [1|1] "V"  BMS
 SG_ BMU30_Vol_28 : 55|16@0+ (0.001,0) [1|1] "V"  BMS

BO_ 2282160158 BMU30_Vol_29: 8 BMU
 SG_ BMU30_Vol_29 : 7|16@0+ (0.001,0) [1|1] "V"  BMS
 SG_ BMU30_Vol_30 : 23|16@0+ (0.001,0) [1|1] "V"  BMS
 SG_ BMU30_Vol_31 : 39|16@0+ (0.001,0) [1|1] "V"  BMS
 SG_ BMU30_Vol_32 : 55|16@0+ (0.001,0) [1|1] "V"  BMS

BO_ 2282225694 BMU30_Vol_33: 8 BMU
 SG_ BMU30_Vol_33 : 7|16@0+ (0.001,0) [1|1] "V"  BMS
 SG_ BMU30_Vol_34 : 23|16@0+ (0.001,0) [1|1] "V"  BMS
 SG_ BMU30_Vol_35 : 39|16@0+ (0.001,0) [1|1] "V"  BMS
 SG_ BMU30_Vol_36 : 55|16@0+ (0.001,0) [1|1] "V"  BMS

BO_ 2282291230 BMU30_Vol_37: 8 BMU
 SG_ BMU30_Vol_37 : 7|16@0+ (0.001,0) [1|1] "V"  BMS
 SG_ BMU30_Vol_38 : 23|16@0+ (0.001,0) [1|1] "V"  BMS
 SG_ BMU30_Vol_39 : 39|16@0+ (0.001,0) [1|1] "V"  BMS
 SG_ BMU30_Vol_40 : 55|16@0+ (0.001,0) [1|1] "V"  BMS

BO_ 2282356766 BMU30_Vol_41: 8 BMU
 SG_ BMU30_Vol_41 : 7|16@0+ (0.001,0) [1|1] "V"  BMS
 SG_ BMU30_Vol_42 : 23|16@0+ (0.001,0) [1|1] "V"  BMS
 SG_ BMU30_Vol_43 : 39|16@0+ (0.001,0) [1|1] "V"  BMS
 SG_ BMU30_Vol_44 : 55|16@0+ (0.001,0) [1|1] "V"  BMS

BO_ 2282422302 BMU30_Vol_45: 8 BMU
 SG_ BMU30_Vol_45 : 7|16@0+ (0.001,0) [1|1] "V"  BMS
 SG_ BMU30_Vol_46 : 23|16@0+ (0.001,0) [1|1] "V"  BMS
 SG_ BMU30_Vol_47 : 39|16@0+ (0.001,0) [1|1] "V"  BMS
 SG_ BMU30_Vol_48 : 55|16@0+ (0.001,0) [1|1] "V"  BMS

BO_ 2282487838 BMU30_Vol_49: 8 BMU
 SG_ BMU30_Vol_49 : 7|16@0+ (0.001,0) [1|1] "V"  BMS
 SG_ BMU30_Vol_50 : 23|16@0+ (0.001,0) [1|1] "V"  BMS
 SG_ BMU30_Vol_51 : 39|16@0+ (0.001,0) [1|1] "V"  BMS
 SG_ BMU30_Vol_52 : 55|16@0+ (0.001,0) [1|1] "V"  BMS

BO_ 2282553374 BMU30_Vol_53: 8 BMU
 SG_ BMU30_Vol_53 : 7|16@0+ (0.001,0) [1|1] "V"  BMS
 SG_ BMU30_Vol_54 : 23|16@0+ (0.001,0) [1|1] "V"  BMS
 SG_ BMU30_Vol_55 : 39|16@0+ (0.001,0) [1|1] "V"  BMS
 SG_ BMU30_Vol_56 : 55|16@0+ (0.001,0) [1|1] "V"  BMS

BO_ 2282618910 BMU30_Vol_57: 8 BMU
 SG_ BMU30_Vol_57 : 7|16@0+ (0.001,0) [1|1] "V"  BMS
 SG_ BMU30_Vol_58 : 23|16@0+ (0.001,0) [1|1] "V"  BMS
 SG_ BMU30_Vol_59 : 39|16@0+ (0.001,0) [1|1] "V"  BMS
 SG_ BMU30_Vol_60 : 55|16@0+ (0.001,0) [1|1] "V"  BMS

BO_ 2282684446 BMU30_Vol_61: 8 BMU
 SG_ BMU30_Vol_61 : 7|16@0+ (0.001,0) [1|1] "V"  BMS
 SG_ BMU30_Vol_62 : 23|16@0+ (0.001,0) [1|1] "V"  BMS
 SG_ BMU30_Vol_63 : 39|16@0+ (0.001,0) [1|1] "V"  BMS
 SG_ BMU30_Vol_64 : 55|16@0+ (0.001,0) [1|1] "V"  BMS

BO_ 2282749982 BMU30_Vol_65: 8 BMU
 SG_ BMU30_Vol_65 : 7|16@0+ (0.001,0) [1|1] "V"  BMS
 SG_ BMU30_Vol_66 : 23|16@0+ (0.001,0) [1|1] "V"  BMS
 SG_ BMU30_Vol_67 : 39|16@0+ (0.001,0) [1|1] "V"  BMS
 SG_ BMU30_Vol_68 : 55|16@0+ (0.001,0) [1|1] "V"  BMS

BO_ 2282815518 BMU30_Vol_69: 8 BMU
 SG_ BMU30_Vol_69 : 7|16@0+ (0.001,0) [1|1] "V"  BMS
 SG_ BMU30_Vol_70 : 23|16@0+ (0.001,0) [1|1] "V"  BMS
 SG_ BMU30_Vol_71 : 39|16@0+ (0.001,0) [1|1] "V"  BMS
 SG_ BMU30_Vol_72 : 55|16@0+ (0.001,0) [1|1] "V"  BMS

BO_ 2282881054 BMU30_Vol_73: 8 BMU
 SG_ BMU30_Vol_73 : 7|16@0+ (0.001,0) [1|1] "V"  BMS
 SG_ BMU30_Vol_74 : 23|16@0+ (0.001,0) [1|1] "V"  BMS
 SG_ BMU30_Vol_75 : 39|16@0+ (0.001,0) [1|1] "V"  BMS
 SG_ BMU30_Vol_76 : 55|16@0+ (0.001,0) [1|1] "V"  BMS

BO_ 2282946590 BMU30_Vol_77: 8 BMU
 SG_ BMU30_Vol_77 : 7|16@0+ (0.001,0) [1|1] "V"  BMS
 SG_ BMU30_Vol_78 : 23|16@0+ (0.001,0) [1|1] "V"  BMS
 SG_ BMU30_Vol_79 : 39|16@0+ (0.001,0) [1|1] "V"  BMS
 SG_ BMU30_Vol_80 : 55|16@0+ (0.001,0) [1|1] "V"  BMS

BO_ 2283012126 BMU30_Vol_81: 8 BMU
 SG_ BMU30_Vol_81 : 7|16@0+ (0.001,0) [1|1] "V"  BMS
 SG_ BMU30_Vol_82 : 23|16@0+ (0.001,0) [1|1] "V"  BMS
 SG_ BMU30_Vol_83 : 39|16@0+ (0.001,0) [1|1] "V"  BMS
 SG_ BMU30_Vol_84 : 55|16@0+ (0.001,0) [1|1] "V"  BMS

BO_ 2283077662 BMU30_Vol_85: 8 BMU
 SG_ BMU30_Vol_85 : 7|16@0+ (0.001,0) [1|1] "V"  BMS
 SG_ BMU30_Vol_86 : 23|16@0+ (0.001,0) [1|1] "V"  BMS
 SG_ BMU30_Vol_87 : 39|16@0+ (0.001,0) [1|1] "V"  BMS
 SG_ BMU30_Vol_88 : 55|16@0+ (0.001,0) [1|1] "V"  BMS

BO_ 2283143198 BMU30_Vol_89: 8 BMU
 SG_ BMU30_Vol_89 : 7|16@0+ (0.001,0) [1|1] "V"  BMS
 SG_ BMU30_Vol_90 : 23|16@0+ (0.001,0) [1|1] "V"  BMS
 SG_ BMU30_Vol_91 : 39|16@0+ (0.001,0) [1|1] "V"  BMS
 SG_ BMU30_Vol_92 : 55|16@0+ (0.001,0) [1|1] "V"  BMS

BO_ 2283208734 BMU30_Vol_93: 8 BMU
 SG_ BMU30_Vol_93 : 7|16@0+ (0.001,0) [1|1] "V"  BMS
 SG_ BMU30_Vol_94 : 23|16@0+ (0.001,0) [1|1] "V"  BMS
 SG_ BMU30_Vol_95 : 39|16@0+ (0.001,0) [1|1] "V"  BMS
 SG_ BMU30_Vol_96 : 55|16@0+ (0.001,0) [1|1] "V"  BMS

BO_ 2298544129 BMU1_IR_1: 8 BMU
 SG_ BMU1_IR_1 : 7|16@0+ (0.1,0) [1|1] "次"  BMS
 SG_ BMU1_IR_2 : 23|16@0+ (0.1,0) [1|1] "次"  BMS
 SG_ BMU1_IR_3 : 39|16@0+ (0.1,0) [1|1] "次"  BMS
 SG_ BMU1_IR_4 : 55|16@0+ (0.1,0) [1|1] "次"  BMS

BO_ 2298609665 BMU1_IR_5: 8 BMU
 SG_ BMU1_IR_5 : 7|16@0+ (0.1,0) [1|1] "次"  BMS
 SG_ BMU1_IR_6 : 23|16@0+ (0.1,0) [1|1] "次"  BMS
 SG_ BMU1_IR_7 : 39|16@0+ (0.1,0) [1|1] "次"  BMS
 SG_ BMU1_IR_8 : 55|16@0+ (0.1,0) [1|1] "次"  BMS

BO_ 2298675201 BMU1_IR_9: 8 BMU
 SG_ BMU1_IR_9 : 7|16@0+ (0.1,0) [1|1] "次"  BMS
 SG_ BMU1_IR_10 : 23|16@0+ (0.1,0) [1|1] "次"  BMS
 SG_ BMU1_IR_11 : 39|16@0+ (0.1,0) [1|1] "次"  BMS
 SG_ BMU1_IR_12 : 55|16@0+ (0.1,0) [1|1] "次"  BMS

BO_ 2298740737 BMU1_IR_13: 8 BMU
 SG_ BMU1_IR_13 : 7|16@0+ (0.1,0) [1|1] "次"  BMS
 SG_ BMU1_IR_14 : 23|16@0+ (0.1,0) [1|1] "次"  BMS
 SG_ BMU1_IR_15 : 39|16@0+ (0.1,0) [1|1] "次"  BMS
 SG_ BMU1_IR_16 : 55|16@0+ (0.1,0) [1|1] "次"  BMS

BO_ 2298806273 BMU1_IR_17: 8 BMU
 SG_ BMU1_IR_17 : 7|16@0+ (0.1,0) [1|1] "次"  BMS
 SG_ BMU1_IR_18 : 23|16@0+ (0.1,0) [1|1] "次"  BMS
 SG_ BMU1_IR_19 : 39|16@0+ (0.1,0) [1|1] "次"  BMS
 SG_ BMU1_IR_20 : 55|16@0+ (0.1,0) [1|1] "次"  BMS

BO_ 2298871809 BMU1_IR_21: 8 BMU
 SG_ BMU1_IR_21 : 7|16@0+ (0.1,0) [1|1] "次"  BMS
 SG_ BMU1_IR_22 : 23|16@0+ (0.1,0) [1|1] "次"  BMS
 SG_ BMU1_IR_23 : 39|16@0+ (0.1,0) [1|1] "次"  BMS
 SG_ BMU1_IR_24 : 55|16@0+ (0.1,0) [1|1] "次"  BMS

BO_ 2298544130 BMU2_IR_1: 8 BMU
 SG_ BMU2_IR_1 : 7|16@0+ (0.1,0) [1|1] "次"  BMS
 SG_ BMU2_IR_2 : 23|16@0+ (0.1,0) [1|1] "次"  BMS
 SG_ BMU2_IR_3 : 39|16@0+ (0.1,0) [1|1] "次"  BMS
 SG_ BMU2_IR_4 : 55|16@0+ (0.1,0) [1|1] "次"  BMS

BO_ 2298609666 BMU2_IR_5: 8 BMU
 SG_ BMU2_IR_5 : 7|16@0+ (0.1,0) [1|1] "次"  BMS
 SG_ BMU2_IR_6 : 23|16@0+ (0.1,0) [1|1] "次"  BMS
 SG_ BMU2_IR_7 : 39|16@0+ (0.1,0) [1|1] "次"  BMS
 SG_ BMU2_IR_8 : 55|16@0+ (0.1,0) [1|1] "次"  BMS

BO_ 2298675202 BMU2_IR_9: 8 BMU
 SG_ BMU2_IR_9 : 7|16@0+ (0.1,0) [1|1] "次"  BMS
 SG_ BMU2_IR_10 : 23|16@0+ (0.1,0) [1|1] "次"  BMS
 SG_ BMU2_IR_11 : 39|16@0+ (0.1,0) [1|1] "次"  BMS
 SG_ BMU2_IR_12 : 55|16@0+ (0.1,0) [1|1] "次"  BMS

BO_ 2298740738 BMU2_IR_13: 8 BMU
 SG_ BMU2_IR_13 : 7|16@0+ (0.1,0) [1|1] "次"  BMS
 SG_ BMU2_IR_14 : 23|16@0+ (0.1,0) [1|1] "次"  BMS
 SG_ BMU2_IR_15 : 39|16@0+ (0.1,0) [1|1] "次"  BMS
 SG_ BMU2_IR_16 : 55|16@0+ (0.1,0) [1|1] "次"  BMS

BO_ 2298806274 BMU2_IR_17: 8 BMU
 SG_ BMU2_IR_17 : 7|16@0+ (0.1,0) [1|1] "次"  BMS
 SG_ BMU2_IR_18 : 23|16@0+ (0.1,0) [1|1] "次"  BMS
 SG_ BMU2_IR_19 : 39|16@0+ (0.1,0) [1|1] "次"  BMS
 SG_ BMU2_IR_20 : 55|16@0+ (0.1,0) [1|1] "次"  BMS

BO_ 2298871810 BMU2_IR_21: 8 BMU
 SG_ BMU2_IR_21 : 7|16@0+ (0.1,0) [1|1] "次"  BMS
 SG_ BMU2_IR_22 : 23|16@0+ (0.1,0) [1|1] "次"  BMS
 SG_ BMU2_IR_23 : 39|16@0+ (0.1,0) [1|1] "次"  BMS
 SG_ BMU2_IR_24 : 55|16@0+ (0.1,0) [1|1] "次"  BMS

BO_ 2298544131 BMU3_IR_1: 8 BMU
 SG_ BMU3_IR_1 : 7|16@0+ (0.1,0) [1|1] "次"  BMS
 SG_ BMU3_IR_2 : 23|16@0+ (0.1,0) [1|1] "次"  BMS
 SG_ BMU3_IR_3 : 39|16@0+ (0.1,0) [1|1] "次"  BMS
 SG_ BMU3_IR_4 : 55|16@0+ (0.1,0) [1|1] "次"  BMS

BO_ 2298609667 BMU3_IR_5: 8 BMU
 SG_ BMU3_IR_5 : 7|16@0+ (0.1,0) [1|1] "次"  BMS
 SG_ BMU3_IR_6 : 23|16@0+ (0.1,0) [1|1] "次"  BMS
 SG_ BMU3_IR_7 : 39|16@0+ (0.1,0) [1|1] "次"  BMS
 SG_ BMU3_IR_8 : 55|16@0+ (0.1,0) [1|1] "次"  BMS

BO_ 2298675203 BMU3_IR_9: 8 BMU
 SG_ BMU3_IR_9 : 7|16@0+ (0.1,0) [1|1] "次"  BMS
 SG_ BMU3_IR_10 : 23|16@0+ (0.1,0) [1|1] "次"  BMS
 SG_ BMU3_IR_11 : 39|16@0+ (0.1,0) [1|1] "次"  BMS
 SG_ BMU3_IR_12 : 55|16@0+ (0.1,0) [1|1] "次"  BMS

BO_ 2298740739 BMU3_IR_13: 8 BMU
 SG_ BMU3_IR_13 : 7|16@0+ (0.1,0) [1|1] "次"  BMS
 SG_ BMU3_IR_14 : 23|16@0+ (0.1,0) [1|1] "次"  BMS
 SG_ BMU3_IR_15 : 39|16@0+ (0.1,0) [1|1] "次"  BMS
 SG_ BMU3_IR_16 : 55|16@0+ (0.1,0) [1|1] "次"  BMS

BO_ 2298806275 BMU3_IR_17: 8 BMU
 SG_ BMU3_IR_17 : 7|16@0+ (0.1,0) [1|1] "次"  BMS
 SG_ BMU3_IR_18 : 23|16@0+ (0.1,0) [1|1] "次"  BMS
 SG_ BMU3_IR_19 : 39|16@0+ (0.1,0) [1|1] "次"  BMS
 SG_ BMU3_IR_20 : 55|16@0+ (0.1,0) [1|1] "次"  BMS

BO_ 2298871811 BMU3_IR_21: 8 BMU
 SG_ BMU3_IR_21 : 7|16@0+ (0.1,0) [1|1] "次"  BMS
 SG_ BMU3_IR_22 : 23|16@0+ (0.1,0) [1|1] "次"  BMS
 SG_ BMU3_IR_23 : 39|16@0+ (0.1,0) [1|1] "次"  BMS
 SG_ BMU3_IR_24 : 55|16@0+ (0.1,0) [1|1] "次"  BMS

BO_ 2298544132 BMU4_IR_1: 8 BMU
 SG_ BMU4_IR_1 : 7|16@0+ (0.1,0) [1|1] "次"  BMS
 SG_ BMU4_IR_2 : 23|16@0+ (0.1,0) [1|1] "次"  BMS
 SG_ BMU4_IR_3 : 39|16@0+ (0.1,0) [1|1] "次"  BMS
 SG_ BMU4_IR_4 : 55|16@0+ (0.1,0) [1|1] "次"  BMS

BO_ 2298609668 BMU4_IR_5: 8 BMU
 SG_ BMU4_IR_5 : 7|16@0+ (0.1,0) [1|1] "次"  BMS
 SG_ BMU4_IR_6 : 23|16@0+ (0.1,0) [1|1] "次"  BMS
 SG_ BMU4_IR_7 : 39|16@0+ (0.1,0) [1|1] "次"  BMS
 SG_ BMU4_IR_8 : 55|16@0+ (0.1,0) [1|1] "次"  BMS

BO_ 2298675204 BMU4_IR_9: 8 BMU
 SG_ BMU4_IR_9 : 7|16@0+ (0.1,0) [1|1] "次"  BMS
 SG_ BMU4_IR_10 : 23|16@0+ (0.1,0) [1|1] "次"  BMS
 SG_ BMU4_IR_11 : 39|16@0+ (0.1,0) [1|1] "次"  BMS
 SG_ BMU4_IR_12 : 55|16@0+ (0.1,0) [1|1] "次"  BMS

BO_ 2298740740 BMU4_IR_13: 8 BMU
 SG_ BMU4_IR_13 : 7|16@0+ (0.1,0) [1|1] "次"  BMS
 SG_ BMU4_IR_14 : 23|16@0+ (0.1,0) [1|1] "次"  BMS
 SG_ BMU4_IR_15 : 39|16@0+ (0.1,0) [1|1] "次"  BMS
 SG_ BMU4_IR_16 : 55|16@0+ (0.1,0) [1|1] "次"  BMS

BO_ 2298806276 BMU4_IR_17: 8 BMU
 SG_ BMU4_IR_17 : 7|16@0+ (0.1,0) [1|1] "次"  BMS
 SG_ BMU4_IR_18 : 23|16@0+ (0.1,0) [1|1] "次"  BMS
 SG_ BMU4_IR_19 : 39|16@0+ (0.1,0) [1|1] "次"  BMS
 SG_ BMU4_IR_20 : 55|16@0+ (0.1,0) [1|1] "次"  BMS

BO_ 2298871812 BMU4_IR_21: 8 BMU
 SG_ BMU4_IR_21 : 7|16@0+ (0.1,0) [1|1] "次"  BMS
 SG_ BMU4_IR_22 : 23|16@0+ (0.1,0) [1|1] "次"  BMS
 SG_ BMU4_IR_23 : 39|16@0+ (0.1,0) [1|1] "次"  BMS
 SG_ BMU4_IR_24 : 55|16@0+ (0.1,0) [1|1] "次"  BMS

BO_ 2298544133 BMU5_IR_1: 8 BMU
 SG_ BMU5_IR_1 : 7|16@0+ (0.1,0) [1|1] "次"  BMS
 SG_ BMU5_IR_2 : 23|16@0+ (0.1,0) [1|1] "次"  BMS
 SG_ BMU5_IR_3 : 39|16@0+ (0.1,0) [1|1] "次"  BMS
 SG_ BMU5_IR_4 : 55|16@0+ (0.1,0) [1|1] "次"  BMS

BO_ 2298609669 BMU5_IR_5: 8 BMU
 SG_ BMU5_IR_5 : 7|16@0+ (0.1,0) [1|1] "次"  BMS
 SG_ BMU5_IR_6 : 23|16@0+ (0.1,0) [1|1] "次"  BMS
 SG_ BMU5_IR_7 : 39|16@0+ (0.1,0) [1|1] "次"  BMS
 SG_ BMU5_IR_8 : 55|16@0+ (0.1,0) [1|1] "次"  BMS

BO_ 2298675205 BMU5_IR_9: 8 BMU
 SG_ BMU5_IR_9 : 7|16@0+ (0.1,0) [1|1] "次"  BMS
 SG_ BMU5_IR_10 : 23|16@0+ (0.1,0) [1|1] "次"  BMS
 SG_ BMU5_IR_11 : 39|16@0+ (0.1,0) [1|1] "次"  BMS
 SG_ BMU5_IR_12 : 55|16@0+ (0.1,0) [1|1] "次"  BMS

BO_ 2298740741 BMU5_IR_13: 8 BMU
 SG_ BMU5_IR_13 : 7|16@0+ (0.1,0) [1|1] "次"  BMS
 SG_ BMU5_IR_14 : 23|16@0+ (0.1,0) [1|1] "次"  BMS
 SG_ BMU5_IR_15 : 39|16@0+ (0.1,0) [1|1] "次"  BMS
 SG_ BMU5_IR_16 : 55|16@0+ (0.1,0) [1|1] "次"  BMS

BO_ 2298806277 BMU5_IR_17: 8 BMU
 SG_ BMU5_IR_17 : 7|16@0+ (0.1,0) [1|1] "次"  BMS
 SG_ BMU5_IR_18 : 23|16@0+ (0.1,0) [1|1] "次"  BMS
 SG_ BMU5_IR_19 : 39|16@0+ (0.1,0) [1|1] "次"  BMS
 SG_ BMU5_IR_20 : 55|16@0+ (0.1,0) [1|1] "次"  BMS

BO_ 2298871813 BMU5_IR_21: 8 BMU
 SG_ BMU5_IR_21 : 7|16@0+ (0.1,0) [1|1] "次"  BMS
 SG_ BMU5_IR_22 : 23|16@0+ (0.1,0) [1|1] "次"  BMS
 SG_ BMU5_IR_23 : 39|16@0+ (0.1,0) [1|1] "次"  BMS
 SG_ BMU5_IR_24 : 55|16@0+ (0.1,0) [1|1] "次"  BMS

BO_ 2298544134 BMU6_IR_1: 8 BMU
 SG_ BMU6_IR_1 : 7|16@0+ (0.1,0) [1|1] "次"  BMS
 SG_ BMU6_IR_2 : 23|16@0+ (0.1,0) [1|1] "次"  BMS
 SG_ BMU6_IR_3 : 39|16@0+ (0.1,0) [1|1] "次"  BMS
 SG_ BMU6_IR_4 : 55|16@0+ (0.1,0) [1|1] "次"  BMS

BO_ 2298609670 BMU6_IR_5: 8 BMU
 SG_ BMU6_IR_5 : 7|16@0+ (0.1,0) [1|1] "次"  BMS
 SG_ BMU6_IR_6 : 23|16@0+ (0.1,0) [1|1] "次"  BMS
 SG_ BMU6_IR_7 : 39|16@0+ (0.1,0) [1|1] "次"  BMS
 SG_ BMU6_IR_8 : 55|16@0+ (0.1,0) [1|1] "次"  BMS

BO_ 2298675206 BMU6_IR_9: 8 BMU
 SG_ BMU6_IR_9 : 7|16@0+ (0.1,0) [1|1] "次"  BMS
 SG_ BMU6_IR_10 : 23|16@0+ (0.1,0) [1|1] "次"  BMS
 SG_ BMU6_IR_11 : 39|16@0+ (0.1,0) [1|1] "次"  BMS
 SG_ BMU6_IR_12 : 55|16@0+ (0.1,0) [1|1] "次"  BMS

BO_ 2298740742 BMU6_IR_13: 8 BMU
 SG_ BMU6_IR_13 : 7|16@0+ (0.1,0) [1|1] "次"  BMS
 SG_ BMU6_IR_14 : 23|16@0+ (0.1,0) [1|1] "次"  BMS
 SG_ BMU6_IR_15 : 39|16@0+ (0.1,0) [1|1] "次"  BMS
 SG_ BMU6_IR_16 : 55|16@0+ (0.1,0) [1|1] "次"  BMS

BO_ 2298806278 BMU6_IR_17: 8 BMU
 SG_ BMU6_IR_17 : 7|16@0+ (0.1,0) [1|1] "次"  BMS
 SG_ BMU6_IR_18 : 23|16@0+ (0.1,0) [1|1] "次"  BMS
 SG_ BMU6_IR_19 : 39|16@0+ (0.1,0) [1|1] "次"  BMS
 SG_ BMU6_IR_20 : 55|16@0+ (0.1,0) [1|1] "次"  BMS

BO_ 2298871814 BMU6_IR_21: 8 BMU
 SG_ BMU6_IR_21 : 7|16@0+ (0.1,0) [1|1] "次"  BMS
 SG_ BMU6_IR_22 : 23|16@0+ (0.1,0) [1|1] "次"  BMS
 SG_ BMU6_IR_23 : 39|16@0+ (0.1,0) [1|1] "次"  BMS
 SG_ BMU6_IR_24 : 55|16@0+ (0.1,0) [1|1] "次"  BMS

BO_ 2298544135 BMU7_IR_1: 8 BMU
 SG_ BMU7_IR_1 : 7|16@0+ (0.1,0) [1|1] "次"  BMS
 SG_ BMU7_IR_2 : 23|16@0+ (0.1,0) [1|1] "次"  BMS
 SG_ BMU7_IR_3 : 39|16@0+ (0.1,0) [1|1] "次"  BMS
 SG_ BMU7_IR_4 : 55|16@0+ (0.1,0) [1|1] "次"  BMS

BO_ 2298609671 BMU7_IR_5: 8 BMU
 SG_ BMU7_IR_5 : 7|16@0+ (0.1,0) [1|1] "次"  BMS
 SG_ BMU7_IR_6 : 23|16@0+ (0.1,0) [1|1] "次"  BMS
 SG_ BMU7_IR_7 : 39|16@0+ (0.1,0) [1|1] "次"  BMS
 SG_ BMU7_IR_8 : 55|16@0+ (0.1,0) [1|1] "次"  BMS

BO_ 2298675207 BMU7_IR_9: 8 BMU
 SG_ BMU7_IR_9 : 7|16@0+ (0.1,0) [1|1] "次"  BMS
 SG_ BMU7_IR_10 : 23|16@0+ (0.1,0) [1|1] "次"  BMS
 SG_ BMU7_IR_11 : 39|16@0+ (0.1,0) [1|1] "次"  BMS
 SG_ BMU7_IR_12 : 55|16@0+ (0.1,0) [1|1] "次"  BMS

BO_ 2298740743 BMU7_IR_13: 8 BMU
 SG_ BMU7_IR_13 : 7|16@0+ (0.1,0) [1|1] "次"  BMS
 SG_ BMU7_IR_14 : 23|16@0+ (0.1,0) [1|1] "次"  BMS
 SG_ BMU7_IR_15 : 39|16@0+ (0.1,0) [1|1] "次"  BMS
 SG_ BMU7_IR_16 : 55|16@0+ (0.1,0) [1|1] "次"  BMS

BO_ 2298806279 BMU7_IR_17: 8 BMU
 SG_ BMU7_IR_17 : 7|16@0+ (0.1,0) [1|1] "次"  BMS
 SG_ BMU7_IR_18 : 23|16@0+ (0.1,0) [1|1] "次"  BMS
 SG_ BMU7_IR_19 : 39|16@0+ (0.1,0) [1|1] "次"  BMS
 SG_ BMU7_IR_20 : 55|16@0+ (0.1,0) [1|1] "次"  BMS

BO_ 2298871815 BMU7_IR_21: 8 BMU
 SG_ BMU7_IR_21 : 7|16@0+ (0.1,0) [1|1] "次"  BMS
 SG_ BMU7_IR_22 : 23|16@0+ (0.1,0) [1|1] "次"  BMS
 SG_ BMU7_IR_23 : 39|16@0+ (0.1,0) [1|1] "次"  BMS
 SG_ BMU7_IR_24 : 55|16@0+ (0.1,0) [1|1] "次"  BMS

BO_ 2298544136 BMU8_IR_1: 8 BMU
 SG_ BMU8_IR_1 : 7|16@0+ (0.1,0) [1|1] "次"  BMS
 SG_ BMU8_IR_2 : 23|16@0+ (0.1,0) [1|1] "次"  BMS
 SG_ BMU8_IR_3 : 39|16@0+ (0.1,0) [1|1] "次"  BMS
 SG_ BMU8_IR_4 : 55|16@0+ (0.1,0) [1|1] "次"  BMS

BO_ 2298609672 BMU8_IR_5: 8 BMU
 SG_ BMU8_IR_5 : 7|16@0+ (0.1,0) [1|1] "次"  BMS
 SG_ BMU8_IR_6 : 23|16@0+ (0.1,0) [1|1] "次"  BMS
 SG_ BMU8_IR_7 : 39|16@0+ (0.1,0) [1|1] "次"  BMS
 SG_ BMU8_IR_8 : 55|16@0+ (0.1,0) [1|1] "次"  BMS

BO_ 2298675208 BMU8_IR_9: 8 BMU
 SG_ BMU8_IR_9 : 7|16@0+ (0.1,0) [1|1] "次"  BMS
 SG_ BMU8_IR_10 : 23|16@0+ (0.1,0) [1|1] "次"  BMS
 SG_ BMU8_IR_11 : 39|16@0+ (0.1,0) [1|1] "次"  BMS
 SG_ BMU8_IR_12 : 55|16@0+ (0.1,0) [1|1] "次"  BMS

BO_ 2298740744 BMU8_IR_13: 8 BMU
 SG_ BMU8_IR_13 : 7|16@0+ (0.1,0) [1|1] "次"  BMS
 SG_ BMU8_IR_14 : 23|16@0+ (0.1,0) [1|1] "次"  BMS
 SG_ BMU8_IR_15 : 39|16@0+ (0.1,0) [1|1] "次"  BMS
 SG_ BMU8_IR_16 : 55|16@0+ (0.1,0) [1|1] "次"  BMS

BO_ 2298806280 BMU8_IR_17: 8 BMU
 SG_ BMU8_IR_17 : 7|16@0+ (0.1,0) [1|1] "次"  BMS
 SG_ BMU8_IR_18 : 23|16@0+ (0.1,0) [1|1] "次"  BMS
 SG_ BMU8_IR_19 : 39|16@0+ (0.1,0) [1|1] "次"  BMS
 SG_ BMU8_IR_20 : 55|16@0+ (0.1,0) [1|1] "次"  BMS

BO_ 2298871816 BMU8_IR_21: 8 BMU
 SG_ BMU8_IR_21 : 7|16@0+ (0.1,0) [1|1] "次"  BMS
 SG_ BMU8_IR_22 : 23|16@0+ (0.1,0) [1|1] "次"  BMS
 SG_ BMU8_IR_23 : 39|16@0+ (0.1,0) [1|1] "次"  BMS
 SG_ BMU8_IR_24 : 55|16@0+ (0.1,0) [1|1] "次"  BMS

BO_ 2298544137 BMU9_IR_1: 8 BMU
 SG_ BMU9_IR_1 : 7|16@0+ (0.1,0) [1|1] "次"  BMS
 SG_ BMU9_IR_2 : 23|16@0+ (0.1,0) [1|1] "次"  BMS
 SG_ BMU9_IR_3 : 39|16@0+ (0.1,0) [1|1] "次"  BMS
 SG_ BMU9_IR_4 : 55|16@0+ (0.1,0) [1|1] "次"  BMS

BO_ 2298609673 BMU9_IR_5: 8 BMU
 SG_ BMU9_IR_5 : 7|16@0+ (0.1,0) [1|1] "次"  BMS
 SG_ BMU9_IR_6 : 23|16@0+ (0.1,0) [1|1] "次"  BMS
 SG_ BMU9_IR_7 : 39|16@0+ (0.1,0) [1|1] "次"  BMS
 SG_ BMU9_IR_8 : 55|16@0+ (0.1,0) [1|1] "次"  BMS

BO_ 2298675209 BMU9_IR_9: 8 BMU
 SG_ BMU9_IR_9 : 7|16@0+ (0.1,0) [1|1] "次"  BMS
 SG_ BMU9_IR_10 : 23|16@0+ (0.1,0) [1|1] "次"  BMS
 SG_ BMU9_IR_11 : 39|16@0+ (0.1,0) [1|1] "次"  BMS
 SG_ BMU9_IR_12 : 55|16@0+ (0.1,0) [1|1] "次"  BMS

BO_ 2298740745 BMU9_IR_13: 8 BMU
 SG_ BMU9_IR_13 : 7|16@0+ (0.1,0) [1|1] "次"  BMS
 SG_ BMU9_IR_14 : 23|16@0+ (0.1,0) [1|1] "次"  BMS
 SG_ BMU9_IR_15 : 39|16@0+ (0.1,0) [1|1] "次"  BMS
 SG_ BMU9_IR_16 : 55|16@0+ (0.1,0) [1|1] "次"  BMS

BO_ 2298806281 BMU9_IR_17: 8 BMU
 SG_ BMU9_IR_17 : 7|16@0+ (0.1,0) [1|1] "次"  BMS
 SG_ BMU9_IR_18 : 23|16@0+ (0.1,0) [1|1] "次"  BMS
 SG_ BMU9_IR_19 : 39|16@0+ (0.1,0) [1|1] "次"  BMS
 SG_ BMU9_IR_20 : 55|16@0+ (0.1,0) [1|1] "次"  BMS

BO_ 2298871817 BMU9_IR_21: 8 BMU
 SG_ BMU9_IR_21 : 7|16@0+ (0.1,0) [1|1] "次"  BMS
 SG_ BMU9_IR_22 : 23|16@0+ (0.1,0) [1|1] "次"  BMS
 SG_ BMU9_IR_23 : 39|16@0+ (0.1,0) [1|1] "次"  BMS
 SG_ BMU9_IR_24 : 55|16@0+ (0.1,0) [1|1] "次"  BMS

BO_ 2298544138 BMU10_IR_1: 8 BMU
 SG_ BMU10_IR_1 : 7|16@0+ (0.1,0) [1|1] "次"  BMS
 SG_ BMU10_IR_2 : 23|16@0+ (0.1,0) [1|1] "次"  BMS
 SG_ BMU10_IR_3 : 39|16@0+ (0.1,0) [1|1] "次"  BMS
 SG_ BMU10_IR_4 : 55|16@0+ (0.1,0) [1|1] "次"  BMS

BO_ 2298609674 BMU10_IR_5: 8 BMU
 SG_ BMU10_IR_5 : 7|16@0+ (0.1,0) [1|1] "次"  BMS
 SG_ BMU10_IR_6 : 23|16@0+ (0.1,0) [1|1] "次"  BMS
 SG_ BMU10_IR_7 : 39|16@0+ (0.1,0) [1|1] "次"  BMS
 SG_ BMU10_IR_8 : 55|16@0+ (0.1,0) [1|1] "次"  BMS

BO_ 2298675210 BMU10_IR_9: 8 BMU
 SG_ BMU10_IR_9 : 7|16@0+ (0.1,0) [1|1] "次"  BMS
 SG_ BMU10_IR_10 : 23|16@0+ (0.1,0) [1|1] "次"  BMS
 SG_ BMU10_IR_11 : 39|16@0+ (0.1,0) [1|1] "次"  BMS
 SG_ BMU10_IR_12 : 55|16@0+ (0.1,0) [1|1] "次"  BMS

BO_ 2298740746 BMU10_IR_13: 8 BMU
 SG_ BMU10_IR_13 : 7|16@0+ (0.1,0) [1|1] "次"  BMS
 SG_ BMU10_IR_14 : 23|16@0+ (0.1,0) [1|1] "次"  BMS
 SG_ BMU10_IR_15 : 39|16@0+ (0.1,0) [1|1] "次"  BMS
 SG_ BMU10_IR_16 : 55|16@0+ (0.1,0) [1|1] "次"  BMS

BO_ 2298806282 BMU10_IR_17: 8 BMU
 SG_ BMU10_IR_17 : 7|16@0+ (0.1,0) [1|1] "次"  BMS
 SG_ BMU10_IR_18 : 23|16@0+ (0.1,0) [1|1] "次"  BMS
 SG_ BMU10_IR_19 : 39|16@0+ (0.1,0) [1|1] "次"  BMS
 SG_ BMU10_IR_20 : 55|16@0+ (0.1,0) [1|1] "次"  BMS

BO_ 2298871818 BMU10_IR_21: 8 BMU
 SG_ BMU10_IR_21 : 7|16@0+ (0.1,0) [1|1] "次"  BMS
 SG_ BMU10_IR_22 : 23|16@0+ (0.1,0) [1|1] "次"  BMS
 SG_ BMU10_IR_23 : 39|16@0+ (0.1,0) [1|1] "次"  BMS
 SG_ BMU10_IR_24 : 55|16@0+ (0.1,0) [1|1] "次"  BMS

BO_ 2298544139 BMU11_IR_1: 8 BMU
 SG_ BMU11_IR_1 : 7|16@0+ (0.1,0) [1|1] "次"  BMS
 SG_ BMU11_IR_2 : 23|16@0+ (0.1,0) [1|1] "次"  BMS
 SG_ BMU11_IR_3 : 39|16@0+ (0.1,0) [1|1] "次"  BMS
 SG_ BMU11_IR_4 : 55|16@0+ (0.1,0) [1|1] "次"  BMS

BO_ 2298609675 BMU11_IR_5: 8 BMU
 SG_ BMU11_IR_5 : 7|16@0+ (0.1,0) [1|1] "次"  BMS
 SG_ BMU11_IR_6 : 23|16@0+ (0.1,0) [1|1] "次"  BMS
 SG_ BMU11_IR_7 : 39|16@0+ (0.1,0) [1|1] "次"  BMS
 SG_ BMU11_IR_8 : 55|16@0+ (0.1,0) [1|1] "次"  BMS

BO_ 2298675211 BMU11_IR_9: 8 BMU
 SG_ BMU11_IR_9 : 7|16@0+ (0.1,0) [1|1] "次"  BMS
 SG_ BMU11_IR_10 : 23|16@0+ (0.1,0) [1|1] "次"  BMS
 SG_ BMU11_IR_11 : 39|16@0+ (0.1,0) [1|1] "次"  BMS
 SG_ BMU11_IR_12 : 55|16@0+ (0.1,0) [1|1] "次"  BMS

BO_ 2298740747 BMU11_IR_13: 8 BMU
 SG_ BMU11_IR_13 : 7|16@0+ (0.1,0) [1|1] "次"  BMS
 SG_ BMU11_IR_14 : 23|16@0+ (0.1,0) [1|1] "次"  BMS
 SG_ BMU11_IR_15 : 39|16@0+ (0.1,0) [1|1] "次"  BMS
 SG_ BMU11_IR_16 : 55|16@0+ (0.1,0) [1|1] "次"  BMS

BO_ 2298806283 BMU11_IR_17: 8 BMU
 SG_ BMU11_IR_17 : 7|16@0+ (0.1,0) [1|1] "次"  BMS
 SG_ BMU11_IR_18 : 23|16@0+ (0.1,0) [1|1] "次"  BMS
 SG_ BMU11_IR_19 : 39|16@0+ (0.1,0) [1|1] "次"  BMS
 SG_ BMU11_IR_20 : 55|16@0+ (0.1,0) [1|1] "次"  BMS

BO_ 2298871819 BMU11_IR_21: 8 BMU
 SG_ BMU11_IR_21 : 7|16@0+ (0.1,0) [1|1] "次"  BMS
 SG_ BMU11_IR_22 : 23|16@0+ (0.1,0) [1|1] "次"  BMS
 SG_ BMU11_IR_23 : 39|16@0+ (0.1,0) [1|1] "次"  BMS
 SG_ BMU11_IR_24 : 55|16@0+ (0.1,0) [1|1] "次"  BMS

BO_ 2298544140 BMU12_IR_1: 8 BMU
 SG_ BMU12_IR_1 : 7|16@0+ (0.1,0) [1|1] "次"  BMS
 SG_ BMU12_IR_2 : 23|16@0+ (0.1,0) [1|1] "次"  BMS
 SG_ BMU12_IR_3 : 39|16@0+ (0.1,0) [1|1] "次"  BMS
 SG_ BMU12_IR_4 : 55|16@0+ (0.1,0) [1|1] "次"  BMS

BO_ 2298609676 BMU12_IR_5: 8 BMU
 SG_ BMU12_IR_5 : 7|16@0+ (0.1,0) [1|1] "次"  BMS
 SG_ BMU12_IR_6 : 23|16@0+ (0.1,0) [1|1] "次"  BMS
 SG_ BMU12_IR_7 : 39|16@0+ (0.1,0) [1|1] "次"  BMS
 SG_ BMU12_IR_8 : 55|16@0+ (0.1,0) [1|1] "次"  BMS

BO_ 2298675212 BMU12_IR_9: 8 BMU
 SG_ BMU12_IR_9 : 7|16@0+ (0.1,0) [1|1] "次"  BMS
 SG_ BMU12_IR_10 : 23|16@0+ (0.1,0) [1|1] "次"  BMS
 SG_ BMU12_IR_11 : 39|16@0+ (0.1,0) [1|1] "次"  BMS
 SG_ BMU12_IR_12 : 55|16@0+ (0.1,0) [1|1] "次"  BMS

BO_ 2298740748 BMU12_IR_13: 8 BMU
 SG_ BMU12_IR_13 : 7|16@0+ (0.1,0) [1|1] "次"  BMS
 SG_ BMU12_IR_14 : 23|16@0+ (0.1,0) [1|1] "次"  BMS
 SG_ BMU12_IR_15 : 39|16@0+ (0.1,0) [1|1] "次"  BMS
 SG_ BMU12_IR_16 : 55|16@0+ (0.1,0) [1|1] "次"  BMS

BO_ 2298806284 BMU12_IR_17: 8 BMU
 SG_ BMU12_IR_17 : 7|16@0+ (0.1,0) [1|1] "次"  BMS
 SG_ BMU12_IR_18 : 23|16@0+ (0.1,0) [1|1] "次"  BMS
 SG_ BMU12_IR_19 : 39|16@0+ (0.1,0) [1|1] "次"  BMS
 SG_ BMU12_IR_20 : 55|16@0+ (0.1,0) [1|1] "次"  BMS

BO_ 2298871820 BMU12_IR_21: 8 BMU
 SG_ BMU12_IR_21 : 7|16@0+ (0.1,0) [1|1] "次"  BMS
 SG_ BMU12_IR_22 : 23|16@0+ (0.1,0) [1|1] "次"  BMS
 SG_ BMU12_IR_23 : 39|16@0+ (0.1,0) [1|1] "次"  BMS
 SG_ BMU12_IR_24 : 55|16@0+ (0.1,0) [1|1] "次"  BMS

BO_ 2298544141 BMU13_IR_1: 8 BMU
 SG_ BMU13_IR_1 : 7|16@0+ (0.1,0) [1|1] "次"  BMS
 SG_ BMU13_IR_2 : 23|16@0+ (0.1,0) [1|1] "次"  BMS
 SG_ BMU13_IR_3 : 39|16@0+ (0.1,0) [1|1] "次"  BMS
 SG_ BMU13_IR_4 : 55|16@0+ (0.1,0) [1|1] "次"  BMS

BO_ 2298609677 BMU13_IR_5: 8 BMU
 SG_ BMU13_IR_5 : 7|16@0+ (0.1,0) [1|1] "次"  BMS
 SG_ BMU13_IR_6 : 23|16@0+ (0.1,0) [1|1] "次"  BMS
 SG_ BMU13_IR_7 : 39|16@0+ (0.1,0) [1|1] "次"  BMS
 SG_ BMU13_IR_8 : 55|16@0+ (0.1,0) [1|1] "次"  BMS

BO_ 2298675213 BMU13_IR_9: 8 BMU
 SG_ BMU13_IR_9 : 7|16@0+ (0.1,0) [1|1] "次"  BMS
 SG_ BMU13_IR_10 : 23|16@0+ (0.1,0) [1|1] "次"  BMS
 SG_ BMU13_IR_11 : 39|16@0+ (0.1,0) [1|1] "次"  BMS
 SG_ BMU13_IR_12 : 55|16@0+ (0.1,0) [1|1] "次"  BMS

BO_ 2298740749 BMU13_IR_13: 8 BMU
 SG_ BMU13_IR_13 : 7|16@0+ (0.1,0) [1|1] "次"  BMS
 SG_ BMU13_IR_14 : 23|16@0+ (0.1,0) [1|1] "次"  BMS
 SG_ BMU13_IR_15 : 39|16@0+ (0.1,0) [1|1] "次"  BMS
 SG_ BMU13_IR_16 : 55|16@0+ (0.1,0) [1|1] "次"  BMS

BO_ 2298806285 BMU13_IR_17: 8 BMU
 SG_ BMU13_IR_17 : 7|16@0+ (0.1,0) [1|1] "次"  BMS
 SG_ BMU13_IR_18 : 23|16@0+ (0.1,0) [1|1] "次"  BMS
 SG_ BMU13_IR_19 : 39|16@0+ (0.1,0) [1|1] "次"  BMS
 SG_ BMU13_IR_20 : 55|16@0+ (0.1,0) [1|1] "次"  BMS

BO_ 2298871821 BMU13_IR_21: 8 BMU
 SG_ BMU13_IR_21 : 7|16@0+ (0.1,0) [1|1] "次"  BMS
 SG_ BMU13_IR_22 : 23|16@0+ (0.1,0) [1|1] "次"  BMS
 SG_ BMU13_IR_23 : 39|16@0+ (0.1,0) [1|1] "次"  BMS
 SG_ BMU13_IR_24 : 55|16@0+ (0.1,0) [1|1] "次"  BMS

BO_ 2298544142 BMU14_IR_1: 8 BMU
 SG_ BMU14_IR_1 : 7|16@0+ (0.1,0) [1|1] "次"  BMS
 SG_ BMU14_IR_2 : 23|16@0+ (0.1,0) [1|1] "次"  BMS
 SG_ BMU14_IR_3 : 39|16@0+ (0.1,0) [1|1] "次"  BMS
 SG_ BMU14_IR_4 : 55|16@0+ (0.1,0) [1|1] "次"  BMS

BO_ 2298609678 BMU14_IR_5: 8 BMU
 SG_ BMU14_IR_5 : 7|16@0+ (0.1,0) [1|1] "次"  BMS
 SG_ BMU14_IR_6 : 23|16@0+ (0.1,0) [1|1] "次"  BMS
 SG_ BMU14_IR_7 : 39|16@0+ (0.1,0) [1|1] "次"  BMS
 SG_ BMU14_IR_8 : 55|16@0+ (0.1,0) [1|1] "次"  BMS

BO_ 2298675214 BMU14_IR_9: 8 BMU
 SG_ BMU14_IR_9 : 7|16@0+ (0.1,0) [1|1] "次"  BMS
 SG_ BMU14_IR_10 : 23|16@0+ (0.1,0) [1|1] "次"  BMS
 SG_ BMU14_IR_11 : 39|16@0+ (0.1,0) [1|1] "次"  BMS
 SG_ BMU14_IR_12 : 55|16@0+ (0.1,0) [1|1] "次"  BMS

BO_ 2298740750 BMU14_IR_13: 8 BMU
 SG_ BMU14_IR_13 : 7|16@0+ (0.1,0) [1|1] "次"  BMS
 SG_ BMU14_IR_14 : 23|16@0+ (0.1,0) [1|1] "次"  BMS
 SG_ BMU14_IR_15 : 39|16@0+ (0.1,0) [1|1] "次"  BMS
 SG_ BMU14_IR_16 : 55|16@0+ (0.1,0) [1|1] "次"  BMS

BO_ 2298806286 BMU14_IR_17: 8 BMU
 SG_ BMU14_IR_17 : 7|16@0+ (0.1,0) [1|1] "次"  BMS
 SG_ BMU14_IR_18 : 23|16@0+ (0.1,0) [1|1] "次"  BMS
 SG_ BMU14_IR_19 : 39|16@0+ (0.1,0) [1|1] "次"  BMS
 SG_ BMU14_IR_20 : 55|16@0+ (0.1,0) [1|1] "次"  BMS

BO_ 2298871822 BMU14_IR_21: 8 BMU
 SG_ BMU14_IR_21 : 7|16@0+ (0.1,0) [1|1] "次"  BMS
 SG_ BMU14_IR_22 : 23|16@0+ (0.1,0) [1|1] "次"  BMS
 SG_ BMU14_IR_23 : 39|16@0+ (0.1,0) [1|1] "次"  BMS
 SG_ BMU14_IR_24 : 55|16@0+ (0.1,0) [1|1] "次"  BMS

BO_ 2298544143 BMU15_IR_1: 8 BMU
 SG_ BMU15_IR_1 : 7|16@0+ (0.1,0) [1|1] "次"  BMS
 SG_ BMU15_IR_2 : 23|16@0+ (0.1,0) [1|1] "次"  BMS
 SG_ BMU15_IR_3 : 39|16@0+ (0.1,0) [1|1] "次"  BMS
 SG_ BMU15_IR_4 : 55|16@0+ (0.1,0) [1|1] "次"  BMS

BO_ 2298609679 BMU15_IR_5: 8 BMU
 SG_ BMU15_IR_5 : 7|16@0+ (0.1,0) [1|1] "次"  BMS
 SG_ BMU15_IR_6 : 23|16@0+ (0.1,0) [1|1] "次"  BMS
 SG_ BMU15_IR_7 : 39|16@0+ (0.1,0) [1|1] "次"  BMS
 SG_ BMU15_IR_8 : 55|16@0+ (0.1,0) [1|1] "次"  BMS

BO_ 2298675215 BMU15_IR_9: 8 BMU
 SG_ BMU15_IR_9 : 7|16@0+ (0.1,0) [1|1] "次"  BMS
 SG_ BMU15_IR_10 : 23|16@0+ (0.1,0) [1|1] "次"  BMS
 SG_ BMU15_IR_11 : 39|16@0+ (0.1,0) [1|1] "次"  BMS
 SG_ BMU15_IR_12 : 55|16@0+ (0.1,0) [1|1] "次"  BMS

BO_ 2298740751 BMU15_IR_13: 8 BMU
 SG_ BMU15_IR_13 : 7|16@0+ (0.1,0) [1|1] "次"  BMS
 SG_ BMU15_IR_14 : 23|16@0+ (0.1,0) [1|1] "次"  BMS
 SG_ BMU15_IR_15 : 39|16@0+ (0.1,0) [1|1] "次"  BMS
 SG_ BMU15_IR_16 : 55|16@0+ (0.1,0) [1|1] "次"  BMS

BO_ 2298806287 BMU15_IR_17: 8 BMU
 SG_ BMU15_IR_17 : 7|16@0+ (0.1,0) [1|1] "次"  BMS
 SG_ BMU15_IR_18 : 23|16@0+ (0.1,0) [1|1] "次"  BMS
 SG_ BMU15_IR_19 : 39|16@0+ (0.1,0) [1|1] "次"  BMS
 SG_ BMU15_IR_20 : 55|16@0+ (0.1,0) [1|1] "次"  BMS

BO_ 2298871823 BMU15_IR_21: 8 BMU
 SG_ BMU15_IR_21 : 7|16@0+ (0.1,0) [1|1] "次"  BMS
 SG_ BMU15_IR_22 : 23|16@0+ (0.1,0) [1|1] "次"  BMS
 SG_ BMU15_IR_23 : 39|16@0+ (0.1,0) [1|1] "次"  BMS
 SG_ BMU15_IR_24 : 55|16@0+ (0.1,0) [1|1] "次"  BMS

BO_ 2298544144 BMU16_IR_1: 8 BMU
 SG_ BMU16_IR_1 : 7|16@0+ (0.1,0) [1|1] "次"  BMS
 SG_ BMU16_IR_2 : 23|16@0+ (0.1,0) [1|1] "次"  BMS
 SG_ BMU16_IR_3 : 39|16@0+ (0.1,0) [1|1] "次"  BMS
 SG_ BMU16_IR_4 : 55|16@0+ (0.1,0) [1|1] "次"  BMS

BO_ 2298609680 BMU16_IR_5: 8 BMU
 SG_ BMU16_IR_5 : 7|16@0+ (0.1,0) [1|1] "次"  BMS
 SG_ BMU16_IR_6 : 23|16@0+ (0.1,0) [1|1] "次"  BMS
 SG_ BMU16_IR_7 : 39|16@0+ (0.1,0) [1|1] "次"  BMS
 SG_ BMU16_IR_8 : 55|16@0+ (0.1,0) [1|1] "次"  BMS

BO_ 2298675216 BMU16_IR_9: 8 BMU
 SG_ BMU16_IR_9 : 7|16@0+ (0.1,0) [1|1] "次"  BMS
 SG_ BMU16_IR_10 : 23|16@0+ (0.1,0) [1|1] "次"  BMS
 SG_ BMU16_IR_11 : 39|16@0+ (0.1,0) [1|1] "次"  BMS
 SG_ BMU16_IR_12 : 55|16@0+ (0.1,0) [1|1] "次"  BMS

BO_ 2298740752 BMU16_IR_13: 8 BMU
 SG_ BMU16_IR_13 : 7|16@0+ (0.1,0) [1|1] "次"  BMS
 SG_ BMU16_IR_14 : 23|16@0+ (0.1,0) [1|1] "次"  BMS
 SG_ BMU16_IR_15 : 39|16@0+ (0.1,0) [1|1] "次"  BMS
 SG_ BMU16_IR_16 : 55|16@0+ (0.1,0) [1|1] "次"  BMS

BO_ 2298806288 BMU16_IR_17: 8 BMU
 SG_ BMU16_IR_17 : 7|16@0+ (0.1,0) [1|1] "次"  BMS
 SG_ BMU16_IR_18 : 23|16@0+ (0.1,0) [1|1] "次"  BMS
 SG_ BMU16_IR_19 : 39|16@0+ (0.1,0) [1|1] "次"  BMS
 SG_ BMU16_IR_20 : 55|16@0+ (0.1,0) [1|1] "次"  BMS

BO_ 2298871824 BMU16_IR_21: 8 BMU
 SG_ BMU16_IR_21 : 7|16@0+ (0.1,0) [1|1] "次"  BMS
 SG_ BMU16_IR_22 : 23|16@0+ (0.1,0) [1|1] "次"  BMS
 SG_ BMU16_IR_23 : 39|16@0+ (0.1,0) [1|1] "次"  BMS
 SG_ BMU16_IR_24 : 55|16@0+ (0.1,0) [1|1] "次"  BMS

BO_ 2298544145 BMU17_IR_1: 8 BMU
 SG_ BMU17_IR_1 : 7|16@0+ (0.1,0) [1|1] "次"  BMS
 SG_ BMU17_IR_2 : 23|16@0+ (0.1,0) [1|1] "次"  BMS
 SG_ BMU17_IR_3 : 39|16@0+ (0.1,0) [1|1] "次"  BMS
 SG_ BMU17_IR_4 : 55|16@0+ (0.1,0) [1|1] "次"  BMS

BO_ 2298609681 BMU17_IR_5: 8 BMU
 SG_ BMU17_IR_5 : 7|16@0+ (0.1,0) [1|1] "次"  BMS
 SG_ BMU17_IR_6 : 23|16@0+ (0.1,0) [1|1] "次"  BMS
 SG_ BMU17_IR_7 : 39|16@0+ (0.1,0) [1|1] "次"  BMS
 SG_ BMU17_IR_8 : 55|16@0+ (0.1,0) [1|1] "次"  BMS

BO_ 2298675217 BMU17_IR_9: 8 BMU
 SG_ BMU17_IR_9 : 7|16@0+ (0.1,0) [1|1] "次"  BMS
 SG_ BMU17_IR_10 : 23|16@0+ (0.1,0) [1|1] "次"  BMS
 SG_ BMU17_IR_11 : 39|16@0+ (0.1,0) [1|1] "次"  BMS
 SG_ BMU17_IR_12 : 55|16@0+ (0.1,0) [1|1] "次"  BMS

BO_ 2298740753 BMU17_IR_13: 8 BMU
 SG_ BMU17_IR_13 : 7|16@0+ (0.1,0) [1|1] "次"  BMS
 SG_ BMU17_IR_14 : 23|16@0+ (0.1,0) [1|1] "次"  BMS
 SG_ BMU17_IR_15 : 39|16@0+ (0.1,0) [1|1] "次"  BMS
 SG_ BMU17_IR_16 : 55|16@0+ (0.1,0) [1|1] "次"  BMS

BO_ 2298806289 BMU17_IR_17: 8 BMU
 SG_ BMU17_IR_17 : 7|16@0+ (0.1,0) [1|1] "次"  BMS
 SG_ BMU17_IR_18 : 23|16@0+ (0.1,0) [1|1] "次"  BMS
 SG_ BMU17_IR_19 : 39|16@0+ (0.1,0) [1|1] "次"  BMS
 SG_ BMU17_IR_20 : 55|16@0+ (0.1,0) [1|1] "次"  BMS

BO_ 2298871825 BMU17_IR_21: 8 BMU
 SG_ BMU17_IR_21 : 7|16@0+ (0.1,0) [1|1] "次"  BMS
 SG_ BMU17_IR_22 : 23|16@0+ (0.1,0) [1|1] "次"  BMS
 SG_ BMU17_IR_23 : 39|16@0+ (0.1,0) [1|1] "次"  BMS
 SG_ BMU17_IR_24 : 55|16@0+ (0.1,0) [1|1] "次"  BMS

BO_ 2298544146 BMU18_IR_1: 8 BMU
 SG_ BMU18_IR_1 : 7|16@0+ (0.1,0) [1|1] "次"  BMS
 SG_ BMU18_IR_2 : 23|16@0+ (0.1,0) [1|1] "次"  BMS
 SG_ BMU18_IR_3 : 39|16@0+ (0.1,0) [1|1] "次"  BMS
 SG_ BMU18_IR_4 : 55|16@0+ (0.1,0) [1|1] "次"  BMS

BO_ 2298609682 BMU18_IR_5: 8 BMU
 SG_ BMU18_IR_5 : 7|16@0+ (0.1,0) [1|1] "次"  BMS
 SG_ BMU18_IR_6 : 23|16@0+ (0.1,0) [1|1] "次"  BMS
 SG_ BMU18_IR_7 : 39|16@0+ (0.1,0) [1|1] "次"  BMS
 SG_ BMU18_IR_8 : 55|16@0+ (0.1,0) [1|1] "次"  BMS

BO_ 2298675218 BMU18_IR_9: 8 BMU
 SG_ BMU18_IR_9 : 7|16@0+ (0.1,0) [1|1] "次"  BMS
 SG_ BMU18_IR_10 : 23|16@0+ (0.1,0) [1|1] "次"  BMS
 SG_ BMU18_IR_11 : 39|16@0+ (0.1,0) [1|1] "次"  BMS
 SG_ BMU18_IR_12 : 55|16@0+ (0.1,0) [1|1] "次"  BMS

BO_ 2298740754 BMU18_IR_13: 8 BMU
 SG_ BMU18_IR_13 : 7|16@0+ (0.1,0) [1|1] "次"  BMS
 SG_ BMU18_IR_14 : 23|16@0+ (0.1,0) [1|1] "次"  BMS
 SG_ BMU18_IR_15 : 39|16@0+ (0.1,0) [1|1] "次"  BMS
 SG_ BMU18_IR_16 : 55|16@0+ (0.1,0) [1|1] "次"  BMS

BO_ 2298806290 BMU18_IR_17: 8 BMU
 SG_ BMU18_IR_17 : 7|16@0+ (0.1,0) [1|1] "次"  BMS
 SG_ BMU18_IR_18 : 23|16@0+ (0.1,0) [1|1] "次"  BMS
 SG_ BMU18_IR_19 : 39|16@0+ (0.1,0) [1|1] "次"  BMS
 SG_ BMU18_IR_20 : 55|16@0+ (0.1,0) [1|1] "次"  BMS

BO_ 2298871826 BMU18_IR_21: 8 BMU
 SG_ BMU18_IR_21 : 7|16@0+ (0.1,0) [1|1] "次"  BMS
 SG_ BMU18_IR_22 : 23|16@0+ (0.1,0) [1|1] "次"  BMS
 SG_ BMU18_IR_23 : 39|16@0+ (0.1,0) [1|1] "次"  BMS
 SG_ BMU18_IR_24 : 55|16@0+ (0.1,0) [1|1] "次"  BMS

BO_ 2298544147 BMU19_IR_1: 8 BMU
 SG_ BMU19_IR_1 : 7|16@0+ (0.1,0) [1|1] "次"  BMS
 SG_ BMU19_IR_2 : 23|16@0+ (0.1,0) [1|1] "次"  BMS
 SG_ BMU19_IR_3 : 39|16@0+ (0.1,0) [1|1] "次"  BMS
 SG_ BMU19_IR_4 : 55|16@0+ (0.1,0) [1|1] "次"  BMS

BO_ 2298609683 BMU19_IR_5: 8 BMU
 SG_ BMU19_IR_5 : 7|16@0+ (0.1,0) [1|1] "次"  BMS
 SG_ BMU19_IR_6 : 23|16@0+ (0.1,0) [1|1] "次"  BMS
 SG_ BMU19_IR_7 : 39|16@0+ (0.1,0) [1|1] "次"  BMS
 SG_ BMU19_IR_8 : 55|16@0+ (0.1,0) [1|1] "次"  BMS

BO_ 2298675219 BMU19_IR_9: 8 BMU
 SG_ BMU19_IR_9 : 7|16@0+ (0.1,0) [1|1] "次"  BMS
 SG_ BMU19_IR_10 : 23|16@0+ (0.1,0) [1|1] "次"  BMS
 SG_ BMU19_IR_11 : 39|16@0+ (0.1,0) [1|1] "次"  BMS
 SG_ BMU19_IR_12 : 55|16@0+ (0.1,0) [1|1] "次"  BMS

BO_ 2298740755 BMU19_IR_13: 8 BMU
 SG_ BMU19_IR_13 : 7|16@0+ (0.1,0) [1|1] "次"  BMS
 SG_ BMU19_IR_14 : 23|16@0+ (0.1,0) [1|1] "次"  BMS
 SG_ BMU19_IR_15 : 39|16@0+ (0.1,0) [1|1] "次"  BMS
 SG_ BMU19_IR_16 : 55|16@0+ (0.1,0) [1|1] "次"  BMS

BO_ 2298806291 BMU19_IR_17: 8 BMU
 SG_ BMU19_IR_17 : 7|16@0+ (0.1,0) [1|1] "次"  BMS
 SG_ BMU19_IR_18 : 23|16@0+ (0.1,0) [1|1] "次"  BMS
 SG_ BMU19_IR_19 : 39|16@0+ (0.1,0) [1|1] "次"  BMS
 SG_ BMU19_IR_20 : 55|16@0+ (0.1,0) [1|1] "次"  BMS

BO_ 2298871827 BMU19_IR_21: 8 BMU
 SG_ BMU19_IR_21 : 7|16@0+ (0.1,0) [1|1] "次"  BMS
 SG_ BMU19_IR_22 : 23|16@0+ (0.1,0) [1|1] "次"  BMS
 SG_ BMU19_IR_23 : 39|16@0+ (0.1,0) [1|1] "次"  BMS
 SG_ BMU19_IR_24 : 55|16@0+ (0.1,0) [1|1] "次"  BMS

BO_ 2298544148 BMU20_IR_1: 8 BMU
 SG_ BMU20_IR_1 : 7|16@0+ (0.1,0) [1|1] "次"  BMS
 SG_ BMU20_IR_2 : 23|16@0+ (0.1,0) [1|1] "次"  BMS
 SG_ BMU20_IR_3 : 39|16@0+ (0.1,0) [1|1] "次"  BMS
 SG_ BMU20_IR_4 : 55|16@0+ (0.1,0) [1|1] "次"  BMS

BO_ 2298609684 BMU20_IR_5: 8 BMU
 SG_ BMU20_IR_5 : 7|16@0+ (0.1,0) [1|1] "次"  BMS
 SG_ BMU20_IR_6 : 23|16@0+ (0.1,0) [1|1] "次"  BMS
 SG_ BMU20_IR_7 : 39|16@0+ (0.1,0) [1|1] "次"  BMS
 SG_ BMU20_IR_8 : 55|16@0+ (0.1,0) [1|1] "次"  BMS

BO_ 2298675220 BMU20_IR_9: 8 BMU
 SG_ BMU20_IR_9 : 7|16@0+ (0.1,0) [1|1] "次"  BMS
 SG_ BMU20_IR_10 : 23|16@0+ (0.1,0) [1|1] "次"  BMS
 SG_ BMU20_IR_11 : 39|16@0+ (0.1,0) [1|1] "次"  BMS
 SG_ BMU20_IR_12 : 55|16@0+ (0.1,0) [1|1] "次"  BMS

BO_ 2298740756 BMU20_IR_13: 8 BMU
 SG_ BMU20_IR_13 : 7|16@0+ (0.1,0) [1|1] "次"  BMS
 SG_ BMU20_IR_14 : 23|16@0+ (0.1,0) [1|1] "次"  BMS
 SG_ BMU20_IR_15 : 39|16@0+ (0.1,0) [1|1] "次"  BMS
 SG_ BMU20_IR_16 : 55|16@0+ (0.1,0) [1|1] "次"  BMS

BO_ 2298806292 BMU20_IR_17: 8 BMU
 SG_ BMU20_IR_17 : 7|16@0+ (0.1,0) [1|1] "次"  BMS
 SG_ BMU20_IR_18 : 23|16@0+ (0.1,0) [1|1] "次"  BMS
 SG_ BMU20_IR_19 : 39|16@0+ (0.1,0) [1|1] "次"  BMS
 SG_ BMU20_IR_20 : 55|16@0+ (0.1,0) [1|1] "次"  BMS

BO_ 2298871828 BMU20_IR_21: 8 BMU
 SG_ BMU20_IR_21 : 7|16@0+ (0.1,0) [1|1] "次"  BMS
 SG_ BMU20_IR_22 : 23|16@0+ (0.1,0) [1|1] "次"  BMS
 SG_ BMU20_IR_23 : 39|16@0+ (0.1,0) [1|1] "次"  BMS
 SG_ BMU20_IR_24 : 55|16@0+ (0.1,0) [1|1] "次"  BMS

BO_ 2298544149 BMU21_IR_1: 8 BMU
 SG_ BMU21_IR_1 : 7|16@0+ (0.1,0) [1|1] "次"  BMS
 SG_ BMU21_IR_2 : 23|16@0+ (0.1,0) [1|1] "次"  BMS
 SG_ BMU21_IR_3 : 39|16@0+ (0.1,0) [1|1] "次"  BMS
 SG_ BMU21_IR_4 : 55|16@0+ (0.1,0) [1|1] "次"  BMS

BO_ 2298609685 BMU21_IR_5: 8 BMU
 SG_ BMU21_IR_5 : 7|16@0+ (0.1,0) [1|1] "次"  BMS
 SG_ BMU21_IR_6 : 23|16@0+ (0.1,0) [1|1] "次"  BMS
 SG_ BMU21_IR_7 : 39|16@0+ (0.1,0) [1|1] "次"  BMS
 SG_ BMU21_IR_8 : 55|16@0+ (0.1,0) [1|1] "次"  BMS

BO_ 2298675221 BMU21_IR_9: 8 BMU
 SG_ BMU21_IR_9 : 7|16@0+ (0.1,0) [1|1] "次"  BMS
 SG_ BMU21_IR_10 : 23|16@0+ (0.1,0) [1|1] "次"  BMS
 SG_ BMU21_IR_11 : 39|16@0+ (0.1,0) [1|1] "次"  BMS
 SG_ BMU21_IR_12 : 55|16@0+ (0.1,0) [1|1] "次"  BMS

BO_ 2298740757 BMU21_IR_13: 8 BMU
 SG_ BMU21_IR_13 : 7|16@0+ (0.1,0) [1|1] "次"  BMS
 SG_ BMU21_IR_14 : 23|16@0+ (0.1,0) [1|1] "次"  BMS
 SG_ BMU21_IR_15 : 39|16@0+ (0.1,0) [1|1] "次"  BMS
 SG_ BMU21_IR_16 : 55|16@0+ (0.1,0) [1|1] "次"  BMS

BO_ 2298806293 BMU21_IR_17: 8 BMU
 SG_ BMU21_IR_17 : 7|16@0+ (0.1,0) [1|1] "次"  BMS
 SG_ BMU21_IR_18 : 23|16@0+ (0.1,0) [1|1] "次"  BMS
 SG_ BMU21_IR_19 : 39|16@0+ (0.1,0) [1|1] "次"  BMS
 SG_ BMU21_IR_20 : 55|16@0+ (0.1,0) [1|1] "次"  BMS

BO_ 2298871829 BMU21_IR_21: 8 BMU
 SG_ BMU21_IR_21 : 7|16@0+ (0.1,0) [1|1] "次"  BMS
 SG_ BMU21_IR_22 : 23|16@0+ (0.1,0) [1|1] "次"  BMS
 SG_ BMU21_IR_23 : 39|16@0+ (0.1,0) [1|1] "次"  BMS
 SG_ BMU21_IR_24 : 55|16@0+ (0.1,0) [1|1] "次"  BMS

BO_ 2298544150 BMU22_IR_1: 8 BMU
 SG_ BMU22_IR_1 : 7|16@0+ (0.1,0) [1|1] "次"  BMS
 SG_ BMU22_IR_2 : 23|16@0+ (0.1,0) [1|1] "次"  BMS
 SG_ BMU22_IR_3 : 39|16@0+ (0.1,0) [1|1] "次"  BMS
 SG_ BMU22_IR_4 : 55|16@0+ (0.1,0) [1|1] "次"  BMS

BO_ 2298609686 BMU22_IR_5: 8 BMU
 SG_ BMU22_IR_5 : 7|16@0+ (0.1,0) [1|1] "次"  BMS
 SG_ BMU22_IR_6 : 23|16@0+ (0.1,0) [1|1] "次"  BMS
 SG_ BMU22_IR_7 : 39|16@0+ (0.1,0) [1|1] "次"  BMS
 SG_ BMU22_IR_8 : 55|16@0+ (0.1,0) [1|1] "次"  BMS

BO_ 2298675222 BMU22_IR_9: 8 BMU
 SG_ BMU22_IR_9 : 7|16@0+ (0.1,0) [1|1] "次"  BMS
 SG_ BMU22_IR_10 : 23|16@0+ (0.1,0) [1|1] "次"  BMS
 SG_ BMU22_IR_11 : 39|16@0+ (0.1,0) [1|1] "次"  BMS
 SG_ BMU22_IR_12 : 55|16@0+ (0.1,0) [1|1] "次"  BMS

BO_ 2298740758 BMU22_IR_13: 8 BMU
 SG_ BMU22_IR_13 : 7|16@0+ (0.1,0) [1|1] "次"  BMS
 SG_ BMU22_IR_14 : 23|16@0+ (0.1,0) [1|1] "次"  BMS
 SG_ BMU22_IR_15 : 39|16@0+ (0.1,0) [1|1] "次"  BMS
 SG_ BMU22_IR_16 : 55|16@0+ (0.1,0) [1|1] "次"  BMS

BO_ 2298806294 BMU22_IR_17: 8 BMU
 SG_ BMU22_IR_17 : 7|16@0+ (0.1,0) [1|1] "次"  BMS
 SG_ BMU22_IR_18 : 23|16@0+ (0.1,0) [1|1] "次"  BMS
 SG_ BMU22_IR_19 : 39|16@0+ (0.1,0) [1|1] "次"  BMS
 SG_ BMU22_IR_20 : 55|16@0+ (0.1,0) [1|1] "次"  BMS

BO_ 2298871830 BMU22_IR_21: 8 BMU
 SG_ BMU22_IR_21 : 7|16@0+ (0.1,0) [1|1] "次"  BMS
 SG_ BMU22_IR_22 : 23|16@0+ (0.1,0) [1|1] "次"  BMS
 SG_ BMU22_IR_23 : 39|16@0+ (0.1,0) [1|1] "次"  BMS
 SG_ BMU22_IR_24 : 55|16@0+ (0.1,0) [1|1] "次"  BMS

BO_ 2298544151 BMU23_IR_1: 8 BMU
 SG_ BMU23_IR_1 : 7|16@0+ (0.1,0) [1|1] "次"  BMS
 SG_ BMU23_IR_2 : 23|16@0+ (0.1,0) [1|1] "次"  BMS
 SG_ BMU23_IR_3 : 39|16@0+ (0.1,0) [1|1] "次"  BMS
 SG_ BMU23_IR_4 : 55|16@0+ (0.1,0) [1|1] "次"  BMS

BO_ 2298609687 BMU23_IR_5: 8 BMU
 SG_ BMU23_IR_5 : 7|16@0+ (0.1,0) [1|1] "次"  BMS
 SG_ BMU23_IR_6 : 23|16@0+ (0.1,0) [1|1] "次"  BMS
 SG_ BMU23_IR_7 : 39|16@0+ (0.1,0) [1|1] "次"  BMS
 SG_ BMU23_IR_8 : 55|16@0+ (0.1,0) [1|1] "次"  BMS

BO_ 2298675223 BMU23_IR_9: 8 BMU
 SG_ BMU23_IR_9 : 7|16@0+ (0.1,0) [1|1] "次"  BMS
 SG_ BMU23_IR_10 : 23|16@0+ (0.1,0) [1|1] "次"  BMS
 SG_ BMU23_IR_11 : 39|16@0+ (0.1,0) [1|1] "次"  BMS
 SG_ BMU23_IR_12 : 55|16@0+ (0.1,0) [1|1] "次"  BMS

BO_ 2298740759 BMU23_IR_13: 8 BMU
 SG_ BMU23_IR_13 : 7|16@0+ (0.1,0) [1|1] "次"  BMS
 SG_ BMU23_IR_14 : 23|16@0+ (0.1,0) [1|1] "次"  BMS
 SG_ BMU23_IR_15 : 39|16@0+ (0.1,0) [1|1] "次"  BMS
 SG_ BMU23_IR_16 : 55|16@0+ (0.1,0) [1|1] "次"  BMS

BO_ 2298806295 BMU23_IR_17: 8 BMU
 SG_ BMU23_IR_17 : 7|16@0+ (0.1,0) [1|1] "次"  BMS
 SG_ BMU23_IR_18 : 23|16@0+ (0.1,0) [1|1] "次"  BMS
 SG_ BMU23_IR_19 : 39|16@0+ (0.1,0) [1|1] "次"  BMS
 SG_ BMU23_IR_20 : 55|16@0+ (0.1,0) [1|1] "次"  BMS

BO_ 2298871831 BMU23_IR_21: 8 BMU
 SG_ BMU23_IR_21 : 7|16@0+ (0.1,0) [1|1] "次"  BMS
 SG_ BMU23_IR_22 : 23|16@0+ (0.1,0) [1|1] "次"  BMS
 SG_ BMU23_IR_23 : 39|16@0+ (0.1,0) [1|1] "次"  BMS
 SG_ BMU23_IR_24 : 55|16@0+ (0.1,0) [1|1] "次"  BMS

BO_ 2298544152 BMU24_IR_1: 8 BMU
 SG_ BMU24_IR_1 : 7|16@0+ (0.1,0) [1|1] "次"  BMS
 SG_ BMU24_IR_2 : 23|16@0+ (0.1,0) [1|1] "次"  BMS
 SG_ BMU24_IR_3 : 39|16@0+ (0.1,0) [1|1] "次"  BMS
 SG_ BMU24_IR_4 : 55|16@0+ (0.1,0) [1|1] "次"  BMS

BO_ 2298609688 BMU24_IR_5: 8 BMU
 SG_ BMU24_IR_5 : 7|16@0+ (0.1,0) [1|1] "次"  BMS
 SG_ BMU24_IR_6 : 23|16@0+ (0.1,0) [1|1] "次"  BMS
 SG_ BMU24_IR_7 : 39|16@0+ (0.1,0) [1|1] "次"  BMS
 SG_ BMU24_IR_8 : 55|16@0+ (0.1,0) [1|1] "次"  BMS

BO_ 2298675224 BMU24_IR_9: 8 BMU
 SG_ BMU24_IR_9 : 7|16@0+ (0.1,0) [1|1] "次"  BMS
 SG_ BMU24_IR_10 : 23|16@0+ (0.1,0) [1|1] "次"  BMS
 SG_ BMU24_IR_11 : 39|16@0+ (0.1,0) [1|1] "次"  BMS
 SG_ BMU24_IR_12 : 55|16@0+ (0.1,0) [1|1] "次"  BMS

BO_ 2298740760 BMU24_IR_13: 8 BMU
 SG_ BMU24_IR_13 : 7|16@0+ (0.1,0) [1|1] "次"  BMS
 SG_ BMU24_IR_14 : 23|16@0+ (0.1,0) [1|1] "次"  BMS
 SG_ BMU24_IR_15 : 39|16@0+ (0.1,0) [1|1] "次"  BMS
 SG_ BMU24_IR_16 : 55|16@0+ (0.1,0) [1|1] "次"  BMS

BO_ 2298806296 BMU24_IR_17: 8 BMU
 SG_ BMU24_IR_17 : 7|16@0+ (0.1,0) [1|1] "次"  BMS
 SG_ BMU24_IR_18 : 23|16@0+ (0.1,0) [1|1] "次"  BMS
 SG_ BMU24_IR_19 : 39|16@0+ (0.1,0) [1|1] "次"  BMS
 SG_ BMU24_IR_20 : 55|16@0+ (0.1,0) [1|1] "次"  BMS

BO_ 2298871832 BMU24_IR_21: 8 BMU
 SG_ BMU24_IR_21 : 7|16@0+ (0.1,0) [1|1] "次"  BMS
 SG_ BMU24_IR_22 : 23|16@0+ (0.1,0) [1|1] "次"  BMS
 SG_ BMU24_IR_23 : 39|16@0+ (0.1,0) [1|1] "次"  BMS
 SG_ BMU24_IR_24 : 55|16@0+ (0.1,0) [1|1] "次"  BMS

BO_ 2298544153 BMU25_IR_1: 8 BMU
 SG_ BMU25_IR_1 : 7|16@0+ (0.1,0) [1|1] "次"  BMS
 SG_ BMU25_IR_2 : 23|16@0+ (0.1,0) [1|1] "次"  BMS
 SG_ BMU25_IR_3 : 39|16@0+ (0.1,0) [1|1] "次"  BMS
 SG_ BMU25_IR_4 : 55|16@0+ (0.1,0) [1|1] "次"  BMS

BO_ 2298609689 BMU25_IR_5: 8 BMU
 SG_ BMU25_IR_5 : 7|16@0+ (0.1,0) [1|1] "次"  BMS
 SG_ BMU25_IR_6 : 23|16@0+ (0.1,0) [1|1] "次"  BMS
 SG_ BMU25_IR_7 : 39|16@0+ (0.1,0) [1|1] "次"  BMS
 SG_ BMU25_IR_8 : 55|16@0+ (0.1,0) [1|1] "次"  BMS

BO_ 2298675225 BMU25_IR_9: 8 BMU
 SG_ BMU25_IR_9 : 7|16@0+ (0.1,0) [1|1] "次"  BMS
 SG_ BMU25_IR_10 : 23|16@0+ (0.1,0) [1|1] "次"  BMS
 SG_ BMU25_IR_11 : 39|16@0+ (0.1,0) [1|1] "次"  BMS
 SG_ BMU25_IR_12 : 55|16@0+ (0.1,0) [1|1] "次"  BMS

BO_ 2298740761 BMU25_IR_13: 8 BMU
 SG_ BMU25_IR_13 : 7|16@0+ (0.1,0) [1|1] "次"  BMS
 SG_ BMU25_IR_14 : 23|16@0+ (0.1,0) [1|1] "次"  BMS
 SG_ BMU25_IR_15 : 39|16@0+ (0.1,0) [1|1] "次"  BMS
 SG_ BMU25_IR_16 : 55|16@0+ (0.1,0) [1|1] "次"  BMS

BO_ 2298806297 BMU25_IR_17: 8 BMU
 SG_ BMU25_IR_17 : 7|16@0+ (0.1,0) [1|1] "次"  BMS
 SG_ BMU25_IR_18 : 23|16@0+ (0.1,0) [1|1] "次"  BMS
 SG_ BMU25_IR_19 : 39|16@0+ (0.1,0) [1|1] "次"  BMS
 SG_ BMU25_IR_20 : 55|16@0+ (0.1,0) [1|1] "次"  BMS

BO_ 2298871833 BMU25_IR_21: 8 BMU
 SG_ BMU25_IR_21 : 7|16@0+ (0.1,0) [1|1] "次"  BMS
 SG_ BMU25_IR_22 : 23|16@0+ (0.1,0) [1|1] "次"  BMS
 SG_ BMU25_IR_23 : 39|16@0+ (0.1,0) [1|1] "次"  BMS
 SG_ BMU25_IR_24 : 55|16@0+ (0.1,0) [1|1] "次"  BMS

BO_ 2298544154 BMU26_IR_1: 8 BMU
 SG_ BMU26_IR_1 : 7|16@0+ (0.1,0) [1|1] "次"  BMS
 SG_ BMU26_IR_2 : 23|16@0+ (0.1,0) [1|1] "次"  BMS
 SG_ BMU26_IR_3 : 39|16@0+ (0.1,0) [1|1] "次"  BMS
 SG_ BMU26_IR_4 : 55|16@0+ (0.1,0) [1|1] "次"  BMS

BO_ 2298609690 BMU26_IR_5: 8 BMU
 SG_ BMU26_IR_5 : 7|16@0+ (0.1,0) [1|1] "次"  BMS
 SG_ BMU26_IR_6 : 23|16@0+ (0.1,0) [1|1] "次"  BMS
 SG_ BMU26_IR_7 : 39|16@0+ (0.1,0) [1|1] "次"  BMS
 SG_ BMU26_IR_8 : 55|16@0+ (0.1,0) [1|1] "次"  BMS

BO_ 2298675226 BMU26_IR_9: 8 BMU
 SG_ BMU26_IR_9 : 7|16@0+ (0.1,0) [1|1] "次"  BMS
 SG_ BMU26_IR_10 : 23|16@0+ (0.1,0) [1|1] "次"  BMS
 SG_ BMU26_IR_11 : 39|16@0+ (0.1,0) [1|1] "次"  BMS
 SG_ BMU26_IR_12 : 55|16@0+ (0.1,0) [1|1] "次"  BMS

BO_ 2298740762 BMU26_IR_13: 8 BMU
 SG_ BMU26_IR_13 : 7|16@0+ (0.1,0) [1|1] "次"  BMS
 SG_ BMU26_IR_14 : 23|16@0+ (0.1,0) [1|1] "次"  BMS
 SG_ BMU26_IR_15 : 39|16@0+ (0.1,0) [1|1] "次"  BMS
 SG_ BMU26_IR_16 : 55|16@0+ (0.1,0) [1|1] "次"  BMS

BO_ 2298806298 BMU26_IR_17: 8 BMU
 SG_ BMU26_IR_17 : 7|16@0+ (0.1,0) [1|1] "次"  BMS
 SG_ BMU26_IR_18 : 23|16@0+ (0.1,0) [1|1] "次"  BMS
 SG_ BMU26_IR_19 : 39|16@0+ (0.1,0) [1|1] "次"  BMS
 SG_ BMU26_IR_20 : 55|16@0+ (0.1,0) [1|1] "次"  BMS

BO_ 2298871834 BMU26_IR_21: 8 BMU
 SG_ BMU26_IR_21 : 7|16@0+ (0.1,0) [1|1] "次"  BMS
 SG_ BMU26_IR_22 : 23|16@0+ (0.1,0) [1|1] "次"  BMS
 SG_ BMU26_IR_23 : 39|16@0+ (0.1,0) [1|1] "次"  BMS
 SG_ BMU26_IR_24 : 55|16@0+ (0.1,0) [1|1] "次"  BMS

BO_ 2298544155 BMU27_IR_1: 8 BMU
 SG_ BMU27_IR_1 : 7|16@0+ (0.1,0) [1|1] "次"  BMS
 SG_ BMU27_IR_2 : 23|16@0+ (0.1,0) [1|1] "次"  BMS
 SG_ BMU27_IR_3 : 39|16@0+ (0.1,0) [1|1] "次"  BMS
 SG_ BMU27_IR_4 : 55|16@0+ (0.1,0) [1|1] "次"  BMS

BO_ 2298609691 BMU27_IR_5: 8 BMU
 SG_ BMU27_IR_5 : 7|16@0+ (0.1,0) [1|1] "次"  BMS
 SG_ BMU27_IR_6 : 23|16@0+ (0.1,0) [1|1] "次"  BMS
 SG_ BMU27_IR_7 : 39|16@0+ (0.1,0) [1|1] "次"  BMS
 SG_ BMU27_IR_8 : 55|16@0+ (0.1,0) [1|1] "次"  BMS

BO_ 2298675227 BMU27_IR_9: 8 BMU
 SG_ BMU27_IR_9 : 7|16@0+ (0.1,0) [1|1] "次"  BMS
 SG_ BMU27_IR_10 : 23|16@0+ (0.1,0) [1|1] "次"  BMS
 SG_ BMU27_IR_11 : 39|16@0+ (0.1,0) [1|1] "次"  BMS
 SG_ BMU27_IR_12 : 55|16@0+ (0.1,0) [1|1] "次"  BMS

BO_ 2298740763 BMU27_IR_13: 8 BMU
 SG_ BMU27_IR_13 : 7|16@0+ (0.1,0) [1|1] "次"  BMS
 SG_ BMU27_IR_14 : 23|16@0+ (0.1,0) [1|1] "次"  BMS
 SG_ BMU27_IR_15 : 39|16@0+ (0.1,0) [1|1] "次"  BMS
 SG_ BMU27_IR_16 : 55|16@0+ (0.1,0) [1|1] "次"  BMS

BO_ 2298806299 BMU27_IR_17: 8 BMU
 SG_ BMU27_IR_17 : 7|16@0+ (0.1,0) [1|1] "次"  BMS
 SG_ BMU27_IR_18 : 23|16@0+ (0.1,0) [1|1] "次"  BMS
 SG_ BMU27_IR_19 : 39|16@0+ (0.1,0) [1|1] "次"  BMS
 SG_ BMU27_IR_20 : 55|16@0+ (0.1,0) [1|1] "次"  BMS

BO_ 2298871835 BMU27_IR_21: 8 BMU
 SG_ BMU27_IR_21 : 7|16@0+ (0.1,0) [1|1] "次"  BMS
 SG_ BMU27_IR_22 : 23|16@0+ (0.1,0) [1|1] "次"  BMS
 SG_ BMU27_IR_23 : 39|16@0+ (0.1,0) [1|1] "次"  BMS
 SG_ BMU27_IR_24 : 55|16@0+ (0.1,0) [1|1] "次"  BMS

BO_ 2298544156 BMU28_IR_1: 8 BMU
 SG_ BMU28_IR_1 : 7|16@0+ (0.1,0) [1|1] "次"  BMS
 SG_ BMU28_IR_2 : 23|16@0+ (0.1,0) [1|1] "次"  BMS
 SG_ BMU28_IR_3 : 39|16@0+ (0.1,0) [1|1] "次"  BMS
 SG_ BMU28_IR_4 : 55|16@0+ (0.1,0) [1|1] "次"  BMS

BO_ 2298609692 BMU28_IR_5: 8 BMU
 SG_ BMU28_IR_5 : 7|16@0+ (0.1,0) [1|1] "次"  BMS
 SG_ BMU28_IR_6 : 23|16@0+ (0.1,0) [1|1] "次"  BMS
 SG_ BMU28_IR_7 : 39|16@0+ (0.1,0) [1|1] "次"  BMS
 SG_ BMU28_IR_8 : 55|16@0+ (0.1,0) [1|1] "次"  BMS

BO_ 2298675228 BMU28_IR_9: 8 BMU
 SG_ BMU28_IR_9 : 7|16@0+ (0.1,0) [1|1] "次"  BMS
 SG_ BMU28_IR_10 : 23|16@0+ (0.1,0) [1|1] "次"  BMS
 SG_ BMU28_IR_11 : 39|16@0+ (0.1,0) [1|1] "次"  BMS
 SG_ BMU28_IR_12 : 55|16@0+ (0.1,0) [1|1] "次"  BMS

BO_ 2298740764 BMU28_IR_13: 8 BMU
 SG_ BMU28_IR_13 : 7|16@0+ (0.1,0) [1|1] "次"  BMS
 SG_ BMU28_IR_14 : 23|16@0+ (0.1,0) [1|1] "次"  BMS
 SG_ BMU28_IR_15 : 39|16@0+ (0.1,0) [1|1] "次"  BMS
 SG_ BMU28_IR_16 : 55|16@0+ (0.1,0) [1|1] "次"  BMS

BO_ 2298806300 BMU28_IR_17: 8 BMU
 SG_ BMU28_IR_17 : 7|16@0+ (0.1,0) [1|1] "次"  BMS
 SG_ BMU28_IR_18 : 23|16@0+ (0.1,0) [1|1] "次"  BMS
 SG_ BMU28_IR_19 : 39|16@0+ (0.1,0) [1|1] "次"  BMS
 SG_ BMU28_IR_20 : 55|16@0+ (0.1,0) [1|1] "次"  BMS

BO_ 2298871836 BMU28_IR_21: 8 BMU
 SG_ BMU28_IR_21 : 7|16@0+ (0.1,0) [1|1] "次"  BMS
 SG_ BMU28_IR_22 : 23|16@0+ (0.1,0) [1|1] "次"  BMS
 SG_ BMU28_IR_23 : 39|16@0+ (0.1,0) [1|1] "次"  BMS
 SG_ BMU28_IR_24 : 55|16@0+ (0.1,0) [1|1] "次"  BMS

BO_ 2298544157 BMU29_IR_1: 8 BMU
 SG_ BMU29_IR_1 : 7|16@0+ (0.1,0) [1|1] "次"  BMS
 SG_ BMU29_IR_2 : 23|16@0+ (0.1,0) [1|1] "次"  BMS
 SG_ BMU29_IR_3 : 39|16@0+ (0.1,0) [1|1] "次"  BMS
 SG_ BMU29_IR_4 : 55|16@0+ (0.1,0) [1|1] "次"  BMS

BO_ 2298609693 BMU29_IR_5: 8 BMU
 SG_ BMU29_IR_5 : 7|16@0+ (0.1,0) [1|1] "次"  BMS
 SG_ BMU29_IR_6 : 23|16@0+ (0.1,0) [1|1] "次"  BMS
 SG_ BMU29_IR_7 : 39|16@0+ (0.1,0) [1|1] "次"  BMS
 SG_ BMU29_IR_8 : 55|16@0+ (0.1,0) [1|1] "次"  BMS

BO_ 2298675229 BMU29_IR_9: 8 BMU
 SG_ BMU29_IR_9 : 7|16@0+ (0.1,0) [1|1] "次"  BMS
 SG_ BMU29_IR_10 : 23|16@0+ (0.1,0) [1|1] "次"  BMS
 SG_ BMU29_IR_11 : 39|16@0+ (0.1,0) [1|1] "次"  BMS
 SG_ BMU29_IR_12 : 55|16@0+ (0.1,0) [1|1] "次"  BMS

BO_ 2298740765 BMU29_IR_13: 8 BMU
 SG_ BMU29_IR_13 : 7|16@0+ (0.1,0) [1|1] "次"  BMS
 SG_ BMU29_IR_14 : 23|16@0+ (0.1,0) [1|1] "次"  BMS
 SG_ BMU29_IR_15 : 39|16@0+ (0.1,0) [1|1] "次"  BMS
 SG_ BMU29_IR_16 : 55|16@0+ (0.1,0) [1|1] "次"  BMS

BO_ 2298806301 BMU29_IR_17: 8 BMU
 SG_ BMU29_IR_17 : 7|16@0+ (0.1,0) [1|1] "次"  BMS
 SG_ BMU29_IR_18 : 23|16@0+ (0.1,0) [1|1] "次"  BMS
 SG_ BMU29_IR_19 : 39|16@0+ (0.1,0) [1|1] "次"  BMS
 SG_ BMU29_IR_20 : 55|16@0+ (0.1,0) [1|1] "次"  BMS

BO_ 2298871837 BMU29_IR_21: 8 BMU
 SG_ BMU29_IR_21 : 7|16@0+ (0.1,0) [1|1] "次"  BMS
 SG_ BMU29_IR_22 : 23|16@0+ (0.1,0) [1|1] "次"  BMS
 SG_ BMU29_IR_23 : 39|16@0+ (0.1,0) [1|1] "次"  BMS
 SG_ BMU29_IR_24 : 55|16@0+ (0.1,0) [1|1] "次"  BMS

BO_ 2298544158 BMU30_IR_1: 8 BMU
 SG_ BMU30_IR_1 : 7|16@0+ (0.1,0) [1|1] "次"  BMS
 SG_ BMU30_IR_2 : 23|16@0+ (0.1,0) [1|1] "次"  BMS
 SG_ BMU30_IR_3 : 39|16@0+ (0.1,0) [1|1] "次"  BMS
 SG_ BMU30_IR_4 : 55|16@0+ (0.1,0) [1|1] "次"  BMS

BO_ 2298609694 BMU30_IR_5: 8 BMU
 SG_ BMU30_IR_5 : 7|16@0+ (0.1,0) [1|1] "次"  BMS
 SG_ BMU30_IR_6 : 23|16@0+ (0.1,0) [1|1] "次"  BMS
 SG_ BMU30_IR_7 : 39|16@0+ (0.1,0) [1|1] "次"  BMS
 SG_ BMU30_IR_8 : 55|16@0+ (0.1,0) [1|1] "次"  BMS

BO_ 2298675230 BMU30_IR_9: 8 BMU
 SG_ BMU30_IR_9 : 7|16@0+ (0.1,0) [1|1] "次"  BMS
 SG_ BMU30_IR_10 : 23|16@0+ (0.1,0) [1|1] "次"  BMS
 SG_ BMU30_IR_11 : 39|16@0+ (0.1,0) [1|1] "次"  BMS
 SG_ BMU30_IR_12 : 55|16@0+ (0.1,0) [1|1] "次"  BMS

BO_ 2298740766 BMU30_IR_13: 8 BMU
 SG_ BMU30_IR_13 : 7|16@0+ (0.1,0) [1|1] "次"  BMS
 SG_ BMU30_IR_14 : 23|16@0+ (0.1,0) [1|1] "次"  BMS
 SG_ BMU30_IR_15 : 39|16@0+ (0.1,0) [1|1] "次"  BMS
 SG_ BMU30_IR_16 : 55|16@0+ (0.1,0) [1|1] "次"  BMS

BO_ 2298806302 BMU30_IR_17: 8 BMU
 SG_ BMU30_IR_17 : 7|16@0+ (0.1,0) [1|1] "次"  BMS
 SG_ BMU30_IR_18 : 23|16@0+ (0.1,0) [1|1] "次"  BMS
 SG_ BMU30_IR_19 : 39|16@0+ (0.1,0) [1|1] "次"  BMS
 SG_ BMU30_IR_20 : 55|16@0+ (0.1,0) [1|1] "次"  BMS

BO_ 2298871838 BMU30_IR_21: 8 BMU
 SG_ BMU30_IR_21 : 7|16@0+ (0.1,0) [1|1] "次"  BMS
 SG_ BMU30_IR_22 : 23|16@0+ (0.1,0) [1|1] "次"  BMS
 SG_ BMU30_IR_23 : 39|16@0+ (0.1,0) [1|1] "次"  BMS
 SG_ BMU30_IR_24 : 55|16@0+ (0.1,0) [1|1] "次"  BMS

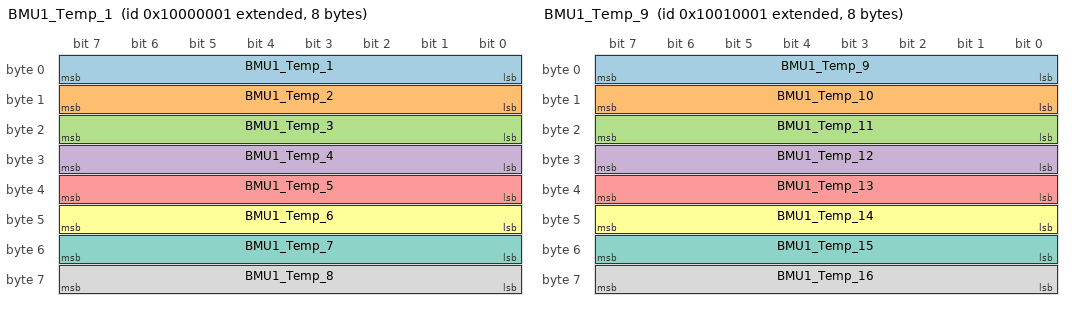
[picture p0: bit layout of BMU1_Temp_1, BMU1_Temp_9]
BO_ 2415919105 BMU1_Temp_1: 8 BMU
 SG_ BMU1_Temp_1 : 7|8@0+ (1,-40) [1|1] "⊥"  BMS
 SG_ BMU1_Temp_2 : 15|8@0+ (1,-40) [1|1] "⊥"  BMS
 SG_ BMU1_Temp_3 : 23|8@0+ (1,-40) [1|1] "⊥"  BMS
 SG_ BMU1_Temp_4 : 31|8@0+ (1,-40) [1|1] "⊥"  BMS
 SG_ BMU1_Temp_5 : 39|8@0+ (1,-40) [1|1] "⊥"  BMS
 SG_ BMU1_Temp_6 : 47|8@0+ (1,-40) [1|1] "⊥"  BMS
 SG_ BMU1_Temp_7 : 55|8@0+ (1,-40) [1|1] "⊥"  BMS
 SG_ BMU1_Temp_8 : 63|8@0+ (1,-40) [1|1] "⊥"  BMS

BO_ 2415984641 BMU1_Temp_9: 8 BMU
 SG_ BMU1_Temp_9 : 7|8@0+ (1,-40) [1|1] "⊥"  BMS
 SG_ BMU1_Temp_10 : 15|8@0+ (1,-40) [1|1] "⊥"  BMS
 SG_ BMU1_Temp_11 : 23|8@0+ (1,-40) [1|1] "⊥"  BMS
 SG_ BMU1_Temp_12 : 31|8@0+ (1,-40) [1|1] "⊥"  BMS
 SG_ BMU1_Temp_13 : 39|8@0+ (1,-40) [1|1] "⊥"  BMS
 SG_ BMU1_Temp_14 : 47|8@0+ (1,-40) [1|1] "⊥"  BMS
 SG_ BMU1_Temp_15 : 55|8@0+ (1,-40) [1|1] "⊥"  BMS
 SG_ BMU1_Temp_16 : 63|8@0+ (1,-40) [1|1] "⊥"  BMS

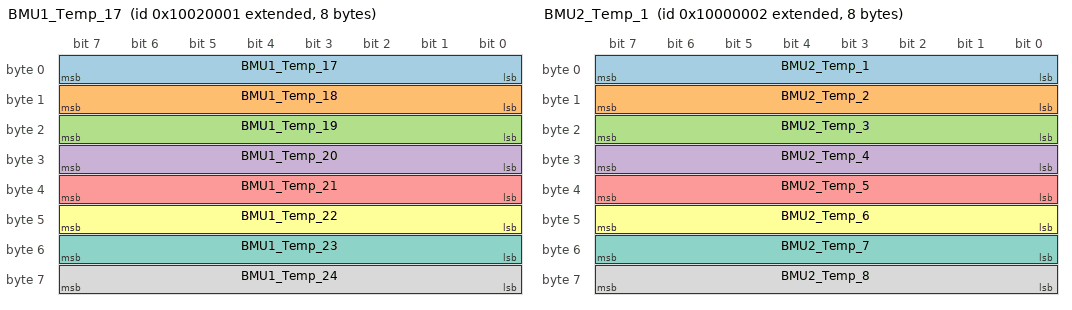
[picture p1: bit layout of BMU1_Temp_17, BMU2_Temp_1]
BO_ 2416050177 BMU1_Temp_17: 8 BMU
 SG_ BMU1_Temp_17 : 7|8@0+ (1,-40) [1|1] "⊥"  BMS
 SG_ BMU1_Temp_18 : 15|8@0+ (1,-40) [1|1] "⊥"  BMS
 SG_ BMU1_Temp_19 : 23|8@0+ (1,-40) [1|1] "⊥"  BMS
 SG_ BMU1_Temp_20 : 31|8@0+ (1,-40) [1|1] "⊥"  BMS
 SG_ BMU1_Temp_21 : 39|8@0+ (1,-40) [1|1] "⊥"  BMS
 SG_ BMU1_Temp_22 : 47|8@0+ (1,-40) [1|1] "⊥"  BMS
 SG_ BMU1_Temp_23 : 55|8@0+ (1,-40) [1|1] "⊥"  BMS
 SG_ BMU1_Temp_24 : 63|8@0+ (1,-40) [1|1] "⊥"  BMS

BO_ 2415919106 BMU2_Temp_1: 8 BMU
 SG_ BMU2_Temp_1 : 7|8@0+ (1,-40) [1|1] "⊥"  BMS
 SG_ BMU2_Temp_2 : 15|8@0+ (1,-40) [1|1] "⊥"  BMS
 SG_ BMU2_Temp_3 : 23|8@0+ (1,-40) [1|1] "⊥"  BMS
 SG_ BMU2_Temp_4 : 31|8@0+ (1,-40) [1|1] "⊥"  BMS
 SG_ BMU2_Temp_5 : 39|8@0+ (1,-40) [1|1] "⊥"  BMS
 SG_ BMU2_Temp_6 : 47|8@0+ (1,-40) [1|1] "⊥"  BMS
 SG_ BMU2_Temp_7 : 55|8@0+ (1,-40) [1|1] "⊥"  BMS
 SG_ BMU2_Temp_8 : 63|8@0+ (1,-40) [1|1] "⊥"  BMS

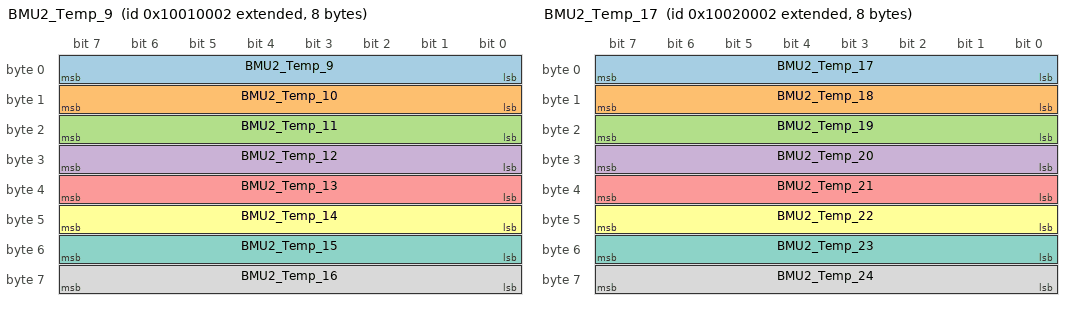
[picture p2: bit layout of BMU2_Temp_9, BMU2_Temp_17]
BO_ 2415984642 BMU2_Temp_9: 8 BMU
 SG_ BMU2_Temp_9 : 7|8@0+ (1,-40) [1|1] "⊥"  BMS
 SG_ BMU2_Temp_10 : 15|8@0+ (1,-40) [1|1] "⊥"  BMS
 SG_ BMU2_Temp_11 : 23|8@0+ (1,-40) [1|1] "⊥"  BMS
 SG_ BMU2_Temp_12 : 31|8@0+ (1,-40) [1|1] "⊥"  BMS
 SG_ BMU2_Temp_13 : 39|8@0+ (1,-40) [1|1] "⊥"  BMS
 SG_ BMU2_Temp_14 : 47|8@0+ (1,-40) [1|1] "⊥"  BMS
 SG_ BMU2_Temp_15 : 55|8@0+ (1,-40) [1|1] "⊥"  BMS
 SG_ BMU2_Temp_16 : 63|8@0+ (1,-40) [1|1] "⊥"  BMS

BO_ 2416050178 BMU2_Temp_17: 8 BMU
 SG_ BMU2_Temp_17 : 7|8@0+ (1,-40) [1|1] "⊥"  BMS
 SG_ BMU2_Temp_18 : 15|8@0+ (1,-40) [1|1] "⊥"  BMS
 SG_ BMU2_Temp_19 : 23|8@0+ (1,-40) [1|1] "⊥"  BMS
 SG_ BMU2_Temp_20 : 31|8@0+ (1,-40) [1|1] "⊥"  BMS
 SG_ BMU2_Temp_21 : 39|8@0+ (1,-40) [1|1] "⊥"  BMS
 SG_ BMU2_Temp_22 : 47|8@0+ (1,-40) [1|1] "⊥"  BMS
 SG_ BMU2_Temp_23 : 55|8@0+ (1,-40) [1|1] "⊥"  BMS
 SG_ BMU2_Temp_24 : 63|8@0+ (1,-40) [1|1] "⊥"  BMS

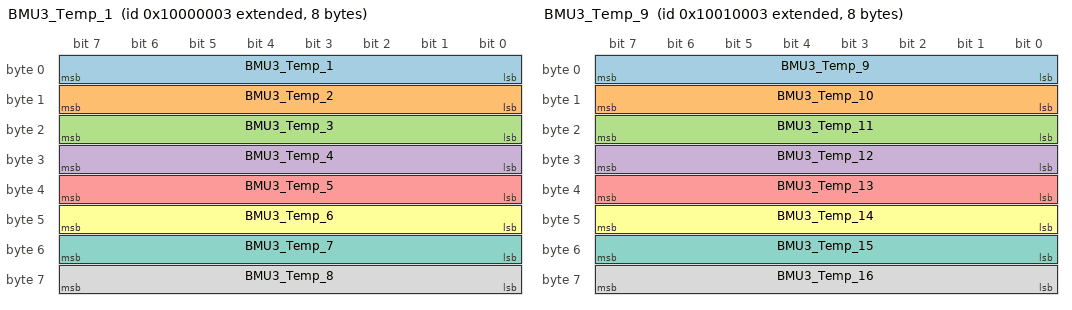
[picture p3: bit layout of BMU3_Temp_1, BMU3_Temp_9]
BO_ 2415919107 BMU3_Temp_1: 8 BMU
 SG_ BMU3_Temp_1 : 7|8@0+ (1,-40) [1|1] "⊥"  BMS
 SG_ BMU3_Temp_2 : 15|8@0+ (1,-40) [1|1] "⊥"  BMS
 SG_ BMU3_Temp_3 : 23|8@0+ (1,-40) [1|1] "⊥"  BMS
 SG_ BMU3_Temp_4 : 31|8@0+ (1,-40) [1|1] "⊥"  BMS
 SG_ BMU3_Temp_5 : 39|8@0+ (1,-40) [1|1] "⊥"  BMS
 SG_ BMU3_Temp_6 : 47|8@0+ (1,-40) [1|1] "⊥"  BMS
 SG_ BMU3_Temp_7 : 55|8@0+ (1,-40) [1|1] "⊥"  BMS
 SG_ BMU3_Temp_8 : 63|8@0+ (1,-40) [1|1] "⊥"  BMS

BO_ 2415984643 BMU3_Temp_9: 8 BMU
 SG_ BMU3_Temp_9 : 7|8@0+ (1,-40) [1|1] "⊥"  BMS
 SG_ BMU3_Temp_10 : 15|8@0+ (1,-40) [1|1] "⊥"  BMS
 SG_ BMU3_Temp_11 : 23|8@0+ (1,-40) [1|1] "⊥"  BMS
 SG_ BMU3_Temp_12 : 31|8@0+ (1,-40) [1|1] "⊥"  BMS
 SG_ BMU3_Temp_13 : 39|8@0+ (1,-40) [1|1] "⊥"  BMS
 SG_ BMU3_Temp_14 : 47|8@0+ (1,-40) [1|1] "⊥"  BMS
 SG_ BMU3_Temp_15 : 55|8@0+ (1,-40) [1|1] "⊥"  BMS
 SG_ BMU3_Temp_16 : 63|8@0+ (1,-40) [1|1] "⊥"  BMS

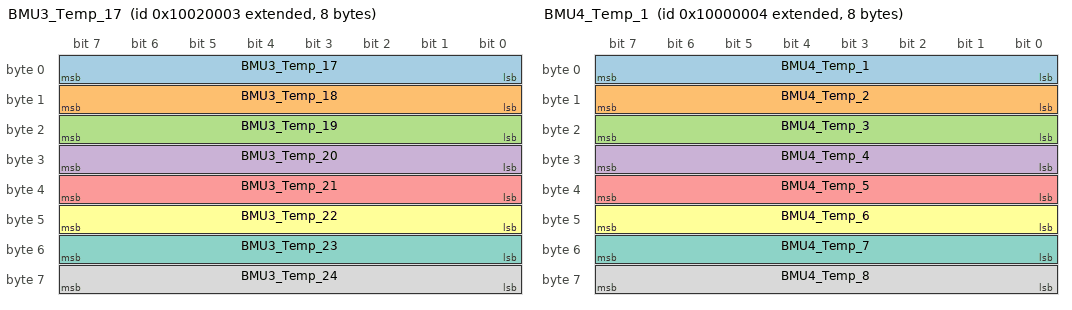
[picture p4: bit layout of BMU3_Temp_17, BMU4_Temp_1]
BO_ 2416050179 BMU3_Temp_17: 8 BMU
 SG_ BMU3_Temp_17 : 7|8@0+ (1,-40) [1|1] "⊥"  BMS
 SG_ BMU3_Temp_18 : 15|8@0+ (1,-40) [1|1] "⊥"  BMS
 SG_ BMU3_Temp_19 : 23|8@0+ (1,-40) [1|1] "⊥"  BMS
 SG_ BMU3_Temp_20 : 31|8@0+ (1,-40) [1|1] "⊥"  BMS
 SG_ BMU3_Temp_21 : 39|8@0+ (1,-40) [1|1] "⊥"  BMS
 SG_ BMU3_Temp_22 : 47|8@0+ (1,-40) [1|1] "⊥"  BMS
 SG_ BMU3_Temp_23 : 55|8@0+ (1,-40) [1|1] "⊥"  BMS
 SG_ BMU3_Temp_24 : 63|8@0+ (1,-40) [1|1] "⊥"  BMS

BO_ 2415919108 BMU4_Temp_1: 8 BMU
 SG_ BMU4_Temp_1 : 7|8@0+ (1,-40) [1|1] "⊥"  BMS
 SG_ BMU4_Temp_2 : 15|8@0+ (1,-40) [1|1] "⊥"  BMS
 SG_ BMU4_Temp_3 : 23|8@0+ (1,-40) [1|1] "⊥"  BMS
 SG_ BMU4_Temp_4 : 31|8@0+ (1,-40) [1|1] "⊥"  BMS
 SG_ BMU4_Temp_5 : 39|8@0+ (1,-40) [1|1] "⊥"  BMS
 SG_ BMU4_Temp_6 : 47|8@0+ (1,-40) [1|1] "⊥"  BMS
 SG_ BMU4_Temp_7 : 55|8@0+ (1,-40) [1|1] "⊥"  BMS
 SG_ BMU4_Temp_8 : 63|8@0+ (1,-40) [1|1] "⊥"  BMS

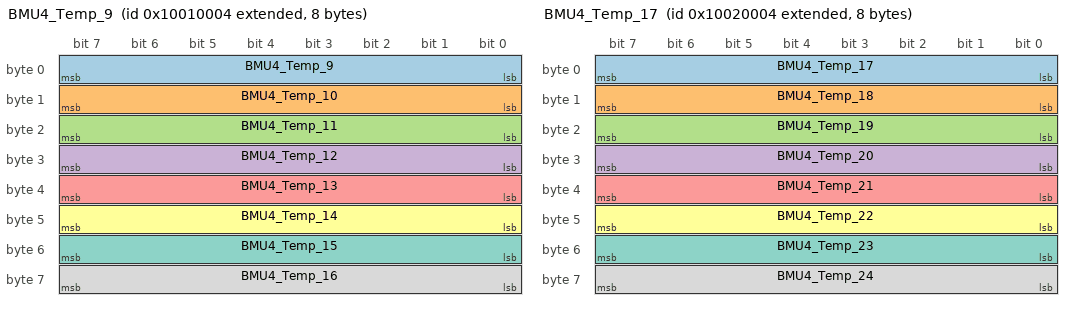
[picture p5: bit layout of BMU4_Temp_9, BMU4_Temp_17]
BO_ 2415984644 BMU4_Temp_9: 8 BMU
 SG_ BMU4_Temp_9 : 7|8@0+ (1,-40) [1|1] "⊥"  BMS
 SG_ BMU4_Temp_10 : 15|8@0+ (1,-40) [1|1] "⊥"  BMS
 SG_ BMU4_Temp_11 : 23|8@0+ (1,-40) [1|1] "⊥"  BMS
 SG_ BMU4_Temp_12 : 31|8@0+ (1,-40) [1|1] "⊥"  BMS
 SG_ BMU4_Temp_13 : 39|8@0+ (1,-40) [1|1] "⊥"  BMS
 SG_ BMU4_Temp_14 : 47|8@0+ (1,-40) [1|1] "⊥"  BMS
 SG_ BMU4_Temp_15 : 55|8@0+ (1,-40) [1|1] "⊥"  BMS
 SG_ BMU4_Temp_16 : 63|8@0+ (1,-40) [1|1] "⊥"  BMS

BO_ 2416050180 BMU4_Temp_17: 8 BMU
 SG_ BMU4_Temp_17 : 7|8@0+ (1,-40) [1|1] "⊥"  BMS
 SG_ BMU4_Temp_18 : 15|8@0+ (1,-40) [1|1] "⊥"  BMS
 SG_ BMU4_Temp_19 : 23|8@0+ (1,-40) [1|1] "⊥"  BMS
 SG_ BMU4_Temp_20 : 31|8@0+ (1,-40) [1|1] "⊥"  BMS
 SG_ BMU4_Temp_21 : 39|8@0+ (1,-40) [1|1] "⊥"  BMS
 SG_ BMU4_Temp_22 : 47|8@0+ (1,-40) [1|1] "⊥"  BMS
 SG_ BMU4_Temp_23 : 55|8@0+ (1,-40) [1|1] "⊥"  BMS
 SG_ BMU4_Temp_24 : 63|8@0+ (1,-40) [1|1] "⊥"  BMS

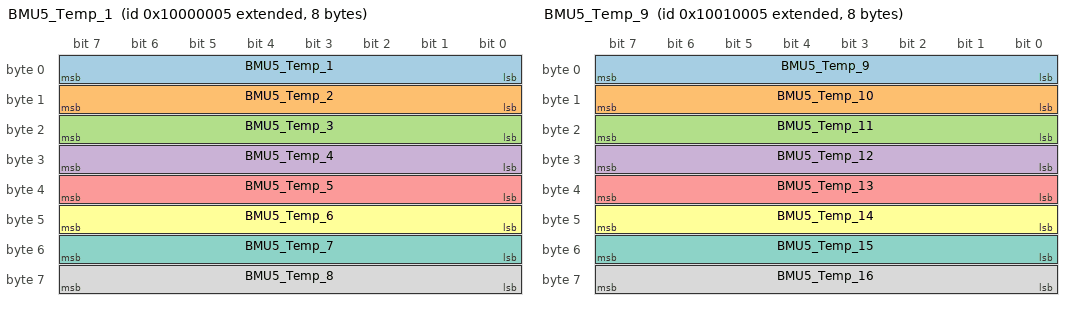
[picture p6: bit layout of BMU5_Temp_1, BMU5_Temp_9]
BO_ 2415919109 BMU5_Temp_1: 8 BMU
 SG_ BMU5_Temp_1 : 7|8@0+ (1,-40) [1|1] "⊥"  BMS
 SG_ BMU5_Temp_2 : 15|8@0+ (1,-40) [1|1] "⊥"  BMS
 SG_ BMU5_Temp_3 : 23|8@0+ (1,-40) [1|1] "⊥"  BMS
 SG_ BMU5_Temp_4 : 31|8@0+ (1,-40) [1|1] "⊥"  BMS
 SG_ BMU5_Temp_5 : 39|8@0+ (1,-40) [1|1] "⊥"  BMS
 SG_ BMU5_Temp_6 : 47|8@0+ (1,-40) [1|1] "⊥"  BMS
 SG_ BMU5_Temp_7 : 55|8@0+ (1,-40) [1|1] "⊥"  BMS
 SG_ BMU5_Temp_8 : 63|8@0+ (1,-40) [1|1] "⊥"  BMS

BO_ 2415984645 BMU5_Temp_9: 8 BMU
 SG_ BMU5_Temp_9 : 7|8@0+ (1,-40) [1|1] "⊥"  BMS
 SG_ BMU5_Temp_10 : 15|8@0+ (1,-40) [1|1] "⊥"  BMS
 SG_ BMU5_Temp_11 : 23|8@0+ (1,-40) [1|1] "⊥"  BMS
 SG_ BMU5_Temp_12 : 31|8@0+ (1,-40) [1|1] "⊥"  BMS
 SG_ BMU5_Temp_13 : 39|8@0+ (1,-40) [1|1] "⊥"  BMS
 SG_ BMU5_Temp_14 : 47|8@0+ (1,-40) [1|1] "⊥"  BMS
 SG_ BMU5_Temp_15 : 55|8@0+ (1,-40) [1|1] "⊥"  BMS
 SG_ BMU5_Temp_16 : 63|8@0+ (1,-40) [1|1] "⊥"  BMS

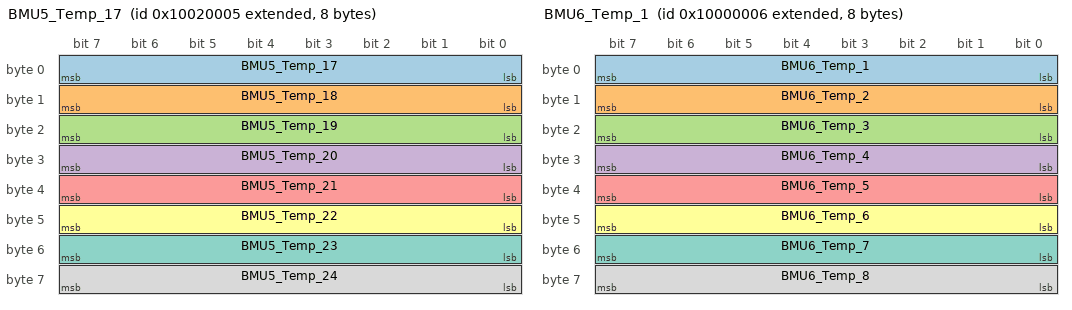
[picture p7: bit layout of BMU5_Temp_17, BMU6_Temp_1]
BO_ 2416050181 BMU5_Temp_17: 8 BMU
 SG_ BMU5_Temp_17 : 7|8@0+ (1,-40) [1|1] "⊥"  BMS
 SG_ BMU5_Temp_18 : 15|8@0+ (1,-40) [1|1] "⊥"  BMS
 SG_ BMU5_Temp_19 : 23|8@0+ (1,-40) [1|1] "⊥"  BMS
 SG_ BMU5_Temp_20 : 31|8@0+ (1,-40) [1|1] "⊥"  BMS
 SG_ BMU5_Temp_21 : 39|8@0+ (1,-40) [1|1] "⊥"  BMS
 SG_ BMU5_Temp_22 : 47|8@0+ (1,-40) [1|1] "⊥"  BMS
 SG_ BMU5_Temp_23 : 55|8@0+ (1,-40) [1|1] "⊥"  BMS
 SG_ BMU5_Temp_24 : 63|8@0+ (1,-40) [1|1] "⊥"  BMS

BO_ 2415919110 BMU6_Temp_1: 8 BMU
 SG_ BMU6_Temp_1 : 7|8@0+ (1,-40) [1|1] "⊥"  BMS
 SG_ BMU6_Temp_2 : 15|8@0+ (1,-40) [1|1] "⊥"  BMS
 SG_ BMU6_Temp_3 : 23|8@0+ (1,-40) [1|1] "⊥"  BMS
 SG_ BMU6_Temp_4 : 31|8@0+ (1,-40) [1|1] "⊥"  BMS
 SG_ BMU6_Temp_5 : 39|8@0+ (1,-40) [1|1] "⊥"  BMS
 SG_ BMU6_Temp_6 : 47|8@0+ (1,-40) [1|1] "⊥"  BMS
 SG_ BMU6_Temp_7 : 55|8@0+ (1,-40) [1|1] "⊥"  BMS
 SG_ BMU6_Temp_8 : 63|8@0+ (1,-40) [1|1] "⊥"  BMS

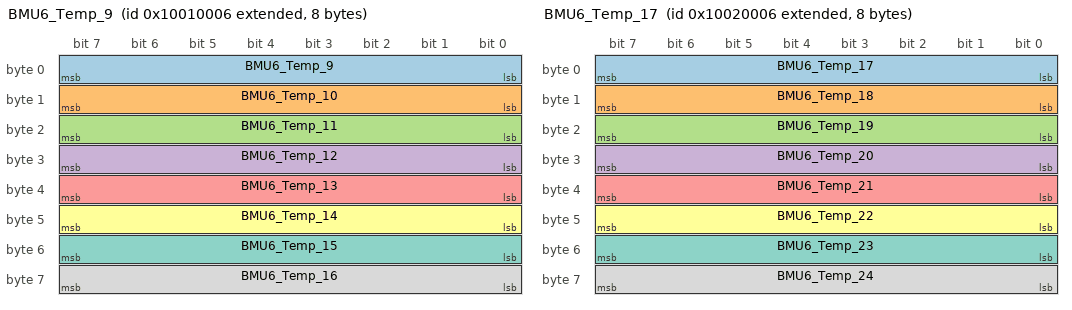
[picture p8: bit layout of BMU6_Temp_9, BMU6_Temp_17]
BO_ 2415984646 BMU6_Temp_9: 8 BMU
 SG_ BMU6_Temp_9 : 7|8@0+ (1,-40) [1|1] "⊥"  BMS
 SG_ BMU6_Temp_10 : 15|8@0+ (1,-40) [1|1] "⊥"  BMS
 SG_ BMU6_Temp_11 : 23|8@0+ (1,-40) [1|1] "⊥"  BMS
 SG_ BMU6_Temp_12 : 31|8@0+ (1,-40) [1|1] "⊥"  BMS
 SG_ BMU6_Temp_13 : 39|8@0+ (1,-40) [1|1] "⊥"  BMS
 SG_ BMU6_Temp_14 : 47|8@0+ (1,-40) [1|1] "⊥"  BMS
 SG_ BMU6_Temp_15 : 55|8@0+ (1,-40) [1|1] "⊥"  BMS
 SG_ BMU6_Temp_16 : 63|8@0+ (1,-40) [1|1] "⊥"  BMS

BO_ 2416050182 BMU6_Temp_17: 8 BMU
 SG_ BMU6_Temp_17 : 7|8@0+ (1,-40) [1|1] "⊥"  BMS
 SG_ BMU6_Temp_18 : 15|8@0+ (1,-40) [1|1] "⊥"  BMS
 SG_ BMU6_Temp_19 : 23|8@0+ (1,-40) [1|1] "⊥"  BMS
 SG_ BMU6_Temp_20 : 31|8@0+ (1,-40) [1|1] "⊥"  BMS
 SG_ BMU6_Temp_21 : 39|8@0+ (1,-40) [1|1] "⊥"  BMS
 SG_ BMU6_Temp_22 : 47|8@0+ (1,-40) [1|1] "⊥"  BMS
 SG_ BMU6_Temp_23 : 55|8@0+ (1,-40) [1|1] "⊥"  BMS
 SG_ BMU6_Temp_24 : 63|8@0+ (1,-40) [1|1] "⊥"  BMS

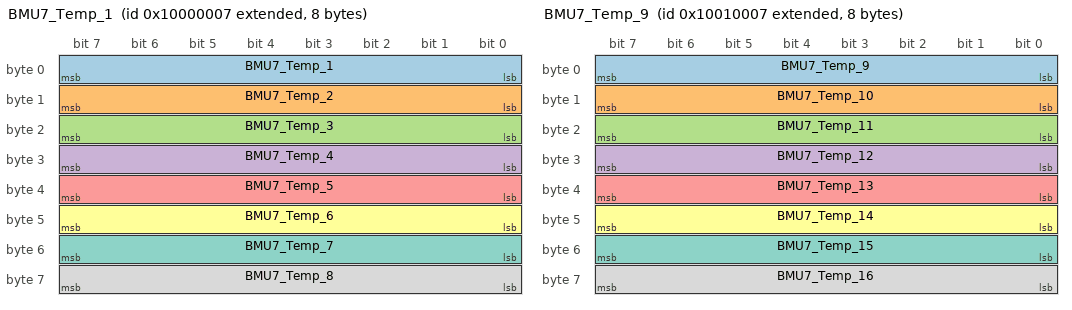
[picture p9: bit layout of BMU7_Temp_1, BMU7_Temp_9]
BO_ 2415919111 BMU7_Temp_1: 8 BMU
 SG_ BMU7_Temp_1 : 7|8@0+ (1,-40) [1|1] "⊥"  BMS
 SG_ BMU7_Temp_2 : 15|8@0+ (1,-40) [1|1] "⊥"  BMS
 SG_ BMU7_Temp_3 : 23|8@0+ (1,-40) [1|1] "⊥"  BMS
 SG_ BMU7_Temp_4 : 31|8@0+ (1,-40) [1|1] "⊥"  BMS
 SG_ BMU7_Temp_5 : 39|8@0+ (1,-40) [1|1] "⊥"  BMS
 SG_ BMU7_Temp_6 : 47|8@0+ (1,-40) [1|1] "⊥"  BMS
 SG_ BMU7_Temp_7 : 55|8@0+ (1,-40) [1|1] "⊥"  BMS
 SG_ BMU7_Temp_8 : 63|8@0+ (1,-40) [1|1] "⊥"  BMS

BO_ 2415984647 BMU7_Temp_9: 8 BMU
 SG_ BMU7_Temp_9 : 7|8@0+ (1,-40) [1|1] "⊥"  BMS
 SG_ BMU7_Temp_10 : 15|8@0+ (1,-40) [1|1] "⊥"  BMS
 SG_ BMU7_Temp_11 : 23|8@0+ (1,-40) [1|1] "⊥"  BMS
 SG_ BMU7_Temp_12 : 31|8@0+ (1,-40) [1|1] "⊥"  BMS
 SG_ BMU7_Temp_13 : 39|8@0+ (1,-40) [1|1] "⊥"  BMS
 SG_ BMU7_Temp_14 : 47|8@0+ (1,-40) [1|1] "⊥"  BMS
 SG_ BMU7_Temp_15 : 55|8@0+ (1,-40) [1|1] "⊥"  BMS
 SG_ BMU7_Temp_16 : 63|8@0+ (1,-40) [1|1] "⊥"  BMS

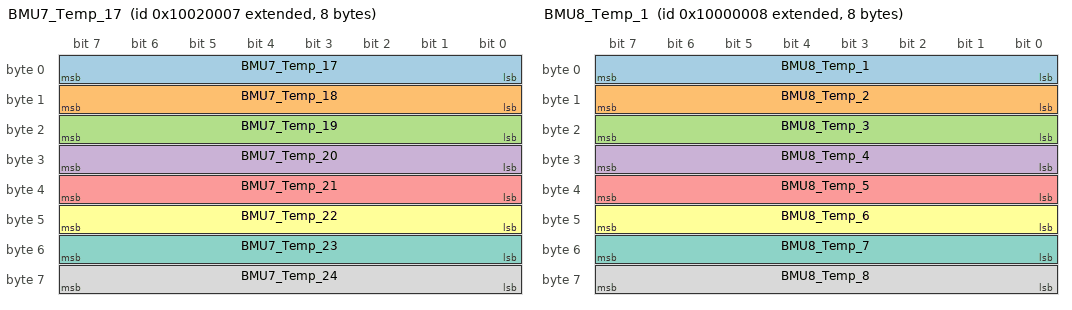
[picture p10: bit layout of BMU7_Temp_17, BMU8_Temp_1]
BO_ 2416050183 BMU7_Temp_17: 8 BMU
 SG_ BMU7_Temp_17 : 7|8@0+ (1,-40) [1|1] "⊥"  BMS
 SG_ BMU7_Temp_18 : 15|8@0+ (1,-40) [1|1] "⊥"  BMS
 SG_ BMU7_Temp_19 : 23|8@0+ (1,-40) [1|1] "⊥"  BMS
 SG_ BMU7_Temp_20 : 31|8@0+ (1,-40) [1|1] "⊥"  BMS
 SG_ BMU7_Temp_21 : 39|8@0+ (1,-40) [1|1] "⊥"  BMS
 SG_ BMU7_Temp_22 : 47|8@0+ (1,-40) [1|1] "⊥"  BMS
 SG_ BMU7_Temp_23 : 55|8@0+ (1,-40) [1|1] "⊥"  BMS
 SG_ BMU7_Temp_24 : 63|8@0+ (1,-40) [1|1] "⊥"  BMS

BO_ 2415919112 BMU8_Temp_1: 8 BMU
 SG_ BMU8_Temp_1 : 7|8@0+ (1,-40) [1|1] "⊥"  BMS
 SG_ BMU8_Temp_2 : 15|8@0+ (1,-40) [1|1] "⊥"  BMS
 SG_ BMU8_Temp_3 : 23|8@0+ (1,-40) [1|1] "⊥"  BMS
 SG_ BMU8_Temp_4 : 31|8@0+ (1,-40) [1|1] "⊥"  BMS
 SG_ BMU8_Temp_5 : 39|8@0+ (1,-40) [1|1] "⊥"  BMS
 SG_ BMU8_Temp_6 : 47|8@0+ (1,-40) [1|1] "⊥"  BMS
 SG_ BMU8_Temp_7 : 55|8@0+ (1,-40) [1|1] "⊥"  BMS
 SG_ BMU8_Temp_8 : 63|8@0+ (1,-40) [1|1] "⊥"  BMS

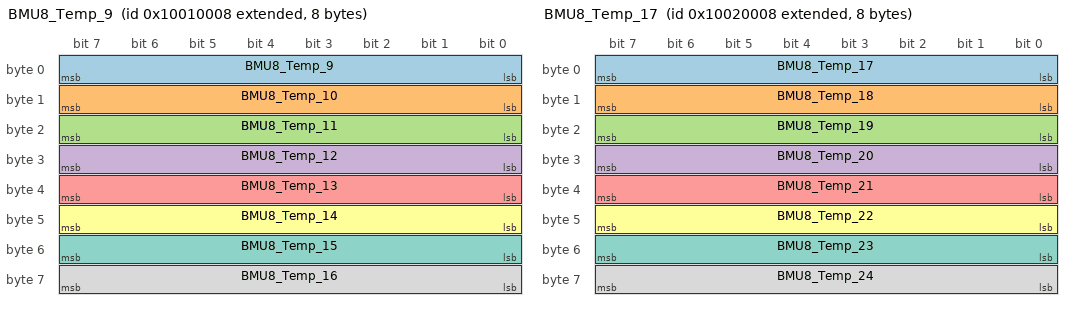
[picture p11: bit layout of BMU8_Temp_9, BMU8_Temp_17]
BO_ 2415984648 BMU8_Temp_9: 8 BMU
 SG_ BMU8_Temp_9 : 7|8@0+ (1,-40) [1|1] "⊥"  BMS
 SG_ BMU8_Temp_10 : 15|8@0+ (1,-40) [1|1] "⊥"  BMS
 SG_ BMU8_Temp_11 : 23|8@0+ (1,-40) [1|1] "⊥"  BMS
 SG_ BMU8_Temp_12 : 31|8@0+ (1,-40) [1|1] "⊥"  BMS
 SG_ BMU8_Temp_13 : 39|8@0+ (1,-40) [1|1] "⊥"  BMS
 SG_ BMU8_Temp_14 : 47|8@0+ (1,-40) [1|1] "⊥"  BMS
 SG_ BMU8_Temp_15 : 55|8@0+ (1,-40) [1|1] "⊥"  BMS
 SG_ BMU8_Temp_16 : 63|8@0+ (1,-40) [1|1] "⊥"  BMS

BO_ 2416050184 BMU8_Temp_17: 8 BMU
 SG_ BMU8_Temp_17 : 7|8@0+ (1,-40) [1|1] "⊥"  BMS
 SG_ BMU8_Temp_18 : 15|8@0+ (1,-40) [1|1] "⊥"  BMS
 SG_ BMU8_Temp_19 : 23|8@0+ (1,-40) [1|1] "⊥"  BMS
 SG_ BMU8_Temp_20 : 31|8@0+ (1,-40) [1|1] "⊥"  BMS
 SG_ BMU8_Temp_21 : 39|8@0+ (1,-40) [1|1] "⊥"  BMS
 SG_ BMU8_Temp_22 : 47|8@0+ (1,-40) [1|1] "⊥"  BMS
 SG_ BMU8_Temp_23 : 55|8@0+ (1,-40) [1|1] "⊥"  BMS
 SG_ BMU8_Temp_24 : 63|8@0+ (1,-40) [1|1] "⊥"  BMS

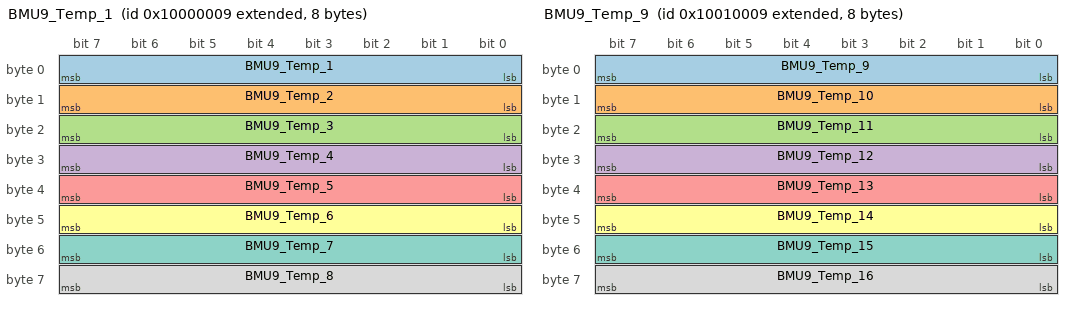
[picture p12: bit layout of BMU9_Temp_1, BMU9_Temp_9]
BO_ 2415919113 BMU9_Temp_1: 8 BMU
 SG_ BMU9_Temp_1 : 7|8@0+ (1,-40) [1|1] "⊥"  BMS
 SG_ BMU9_Temp_2 : 15|8@0+ (1,-40) [1|1] "⊥"  BMS
 SG_ BMU9_Temp_3 : 23|8@0+ (1,-40) [1|1] "⊥"  BMS
 SG_ BMU9_Temp_4 : 31|8@0+ (1,-40) [1|1] "⊥"  BMS
 SG_ BMU9_Temp_5 : 39|8@0+ (1,-40) [1|1] "⊥"  BMS
 SG_ BMU9_Temp_6 : 47|8@0+ (1,-40) [1|1] "⊥"  BMS
 SG_ BMU9_Temp_7 : 55|8@0+ (1,-40) [1|1] "⊥"  BMS
 SG_ BMU9_Temp_8 : 63|8@0+ (1,-40) [1|1] "⊥"  BMS

BO_ 2415984649 BMU9_Temp_9: 8 BMU
 SG_ BMU9_Temp_9 : 7|8@0+ (1,-40) [1|1] "⊥"  BMS
 SG_ BMU9_Temp_10 : 15|8@0+ (1,-40) [1|1] "⊥"  BMS
 SG_ BMU9_Temp_11 : 23|8@0+ (1,-40) [1|1] "⊥"  BMS
 SG_ BMU9_Temp_12 : 31|8@0+ (1,-40) [1|1] "⊥"  BMS
 SG_ BMU9_Temp_13 : 39|8@0+ (1,-40) [1|1] "⊥"  BMS
 SG_ BMU9_Temp_14 : 47|8@0+ (1,-40) [1|1] "⊥"  BMS
 SG_ BMU9_Temp_15 : 55|8@0+ (1,-40) [1|1] "⊥"  BMS
 SG_ BMU9_Temp_16 : 63|8@0+ (1,-40) [1|1] "⊥"  BMS

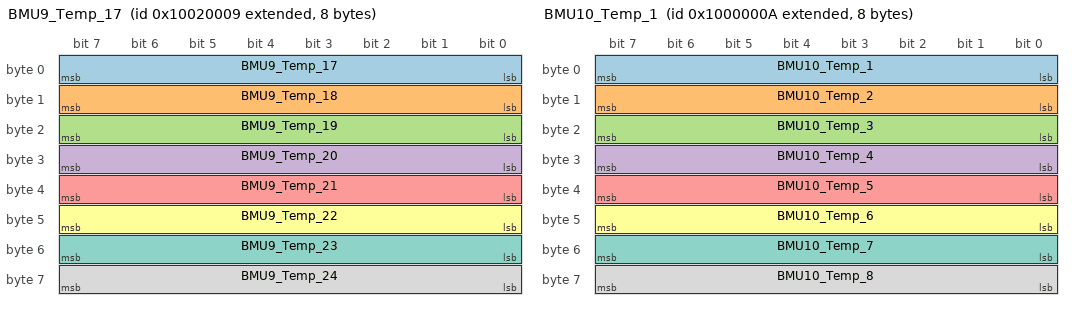
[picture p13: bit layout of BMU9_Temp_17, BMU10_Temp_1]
BO_ 2416050185 BMU9_Temp_17: 8 BMU
 SG_ BMU9_Temp_17 : 7|8@0+ (1,-40) [1|1] "⊥"  BMS
 SG_ BMU9_Temp_18 : 15|8@0+ (1,-40) [1|1] "⊥"  BMS
 SG_ BMU9_Temp_19 : 23|8@0+ (1,-40) [1|1] "⊥"  BMS
 SG_ BMU9_Temp_20 : 31|8@0+ (1,-40) [1|1] "⊥"  BMS
 SG_ BMU9_Temp_21 : 39|8@0+ (1,-40) [1|1] "⊥"  BMS
 SG_ BMU9_Temp_22 : 47|8@0+ (1,-40) [1|1] "⊥"  BMS
 SG_ BMU9_Temp_23 : 55|8@0+ (1,-40) [1|1] "⊥"  BMS
 SG_ BMU9_Temp_24 : 63|8@0+ (1,-40) [1|1] "⊥"  BMS

BO_ 2415919114 BMU10_Temp_1: 8 BMU
 SG_ BMU10_Temp_1 : 7|8@0+ (1,-40) [1|1] "⊥"  BMS
 SG_ BMU10_Temp_2 : 15|8@0+ (1,-40) [1|1] "⊥"  BMS
 SG_ BMU10_Temp_3 : 23|8@0+ (1,-40) [1|1] "⊥"  BMS
 SG_ BMU10_Temp_4 : 31|8@0+ (1,-40) [1|1] "⊥"  BMS
 SG_ BMU10_Temp_5 : 39|8@0+ (1,-40) [1|1] "⊥"  BMS
 SG_ BMU10_Temp_6 : 47|8@0+ (1,-40) [1|1] "⊥"  BMS
 SG_ BMU10_Temp_7 : 55|8@0+ (1,-40) [1|1] "⊥"  BMS
 SG_ BMU10_Temp_8 : 63|8@0+ (1,-40) [1|1] "⊥"  BMS

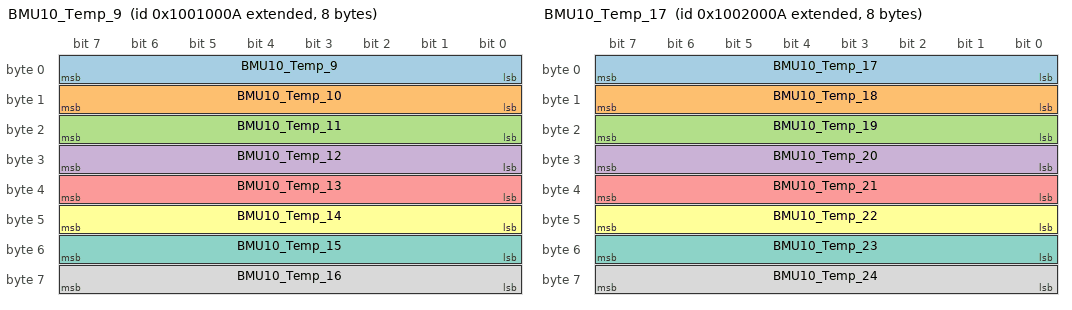
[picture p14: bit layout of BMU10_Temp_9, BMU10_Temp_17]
BO_ 2415984650 BMU10_Temp_9: 8 BMU
 SG_ BMU10_Temp_9 : 7|8@0+ (1,-40) [1|1] "⊥"  BMS
 SG_ BMU10_Temp_10 : 15|8@0+ (1,-40) [1|1] "⊥"  BMS
 SG_ BMU10_Temp_11 : 23|8@0+ (1,-40) [1|1] "⊥"  BMS
 SG_ BMU10_Temp_12 : 31|8@0+ (1,-40) [1|1] "⊥"  BMS
 SG_ BMU10_Temp_13 : 39|8@0+ (1,-40) [1|1] "⊥"  BMS
 SG_ BMU10_Temp_14 : 47|8@0+ (1,-40) [1|1] "⊥"  BMS
 SG_ BMU10_Temp_15 : 55|8@0+ (1,-40) [1|1] "⊥"  BMS
 SG_ BMU10_Temp_16 : 63|8@0+ (1,-40) [1|1] "⊥"  BMS

BO_ 2416050186 BMU10_Temp_17: 8 BMU
 SG_ BMU10_Temp_17 : 7|8@0+ (1,-40) [1|1] "⊥"  BMS
 SG_ BMU10_Temp_18 : 15|8@0+ (1,-40) [1|1] "⊥"  BMS
 SG_ BMU10_Temp_19 : 23|8@0+ (1,-40) [1|1] "⊥"  BMS
 SG_ BMU10_Temp_20 : 31|8@0+ (1,-40) [1|1] "⊥"  BMS
 SG_ BMU10_Temp_21 : 39|8@0+ (1,-40) [1|1] "⊥"  BMS
 SG_ BMU10_Temp_22 : 47|8@0+ (1,-40) [1|1] "⊥"  BMS
 SG_ BMU10_Temp_23 : 55|8@0+ (1,-40) [1|1] "⊥"  BMS
 SG_ BMU10_Temp_24 : 63|8@0+ (1,-40) [1|1] "⊥"  BMS

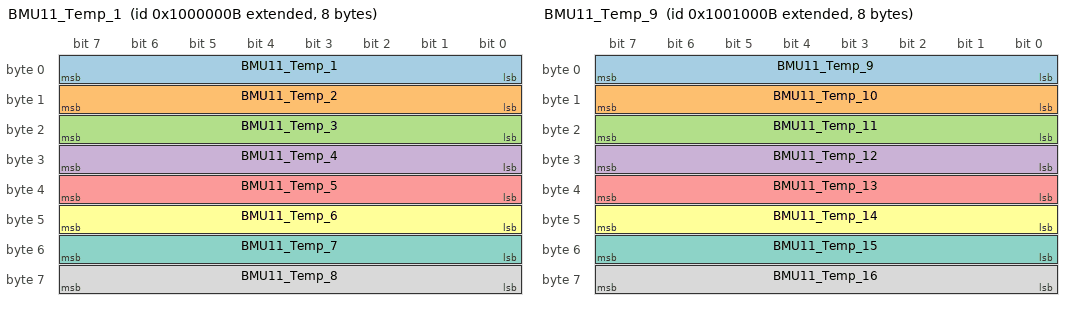
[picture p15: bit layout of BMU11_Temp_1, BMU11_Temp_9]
BO_ 2415919115 BMU11_Temp_1: 8 BMU
 SG_ BMU11_Temp_1 : 7|8@0+ (1,-40) [1|1] "⊥"  BMS
 SG_ BMU11_Temp_2 : 15|8@0+ (1,-40) [1|1] "⊥"  BMS
 SG_ BMU11_Temp_3 : 23|8@0+ (1,-40) [1|1] "⊥"  BMS
 SG_ BMU11_Temp_4 : 31|8@0+ (1,-40) [1|1] "⊥"  BMS
 SG_ BMU11_Temp_5 : 39|8@0+ (1,-40) [1|1] "⊥"  BMS
 SG_ BMU11_Temp_6 : 47|8@0+ (1,-40) [1|1] "⊥"  BMS
 SG_ BMU11_Temp_7 : 55|8@0+ (1,-40) [1|1] "⊥"  BMS
 SG_ BMU11_Temp_8 : 63|8@0+ (1,-40) [1|1] "⊥"  BMS

BO_ 2415984651 BMU11_Temp_9: 8 BMU
 SG_ BMU11_Temp_9 : 7|8@0+ (1,-40) [1|1] "⊥"  BMS
 SG_ BMU11_Temp_10 : 15|8@0+ (1,-40) [1|1] "⊥"  BMS
 SG_ BMU11_Temp_11 : 23|8@0+ (1,-40) [1|1] "⊥"  BMS
 SG_ BMU11_Temp_12 : 31|8@0+ (1,-40) [1|1] "⊥"  BMS
 SG_ BMU11_Temp_13 : 39|8@0+ (1,-40) [1|1] "⊥"  BMS
 SG_ BMU11_Temp_14 : 47|8@0+ (1,-40) [1|1] "⊥"  BMS
 SG_ BMU11_Temp_15 : 55|8@0+ (1,-40) [1|1] "⊥"  BMS
 SG_ BMU11_Temp_16 : 63|8@0+ (1,-40) [1|1] "⊥"  BMS

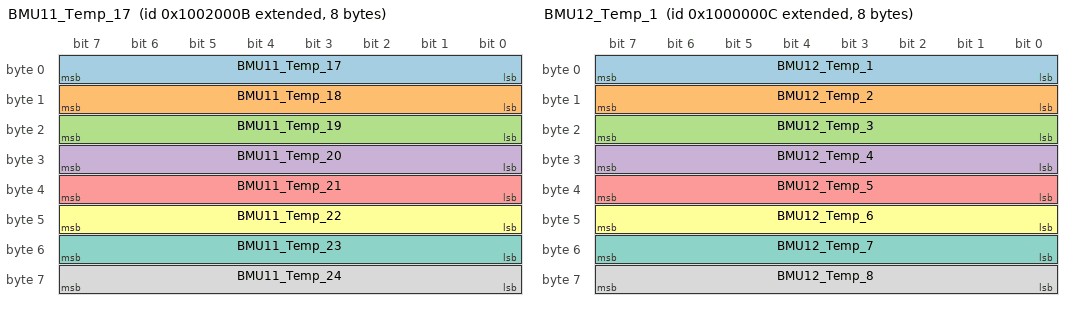
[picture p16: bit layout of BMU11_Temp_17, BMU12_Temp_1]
BO_ 2416050187 BMU11_Temp_17: 8 BMU
 SG_ BMU11_Temp_17 : 7|8@0+ (1,-40) [1|1] "⊥"  BMS
 SG_ BMU11_Temp_18 : 15|8@0+ (1,-40) [1|1] "⊥"  BMS
 SG_ BMU11_Temp_19 : 23|8@0+ (1,-40) [1|1] "⊥"  BMS
 SG_ BMU11_Temp_20 : 31|8@0+ (1,-40) [1|1] "⊥"  BMS
 SG_ BMU11_Temp_21 : 39|8@0+ (1,-40) [1|1] "⊥"  BMS
 SG_ BMU11_Temp_22 : 47|8@0+ (1,-40) [1|1] "⊥"  BMS
 SG_ BMU11_Temp_23 : 55|8@0+ (1,-40) [1|1] "⊥"  BMS
 SG_ BMU11_Temp_24 : 63|8@0+ (1,-40) [1|1] "⊥"  BMS

BO_ 2415919116 BMU12_Temp_1: 8 BMU
 SG_ BMU12_Temp_1 : 7|8@0+ (1,-40) [1|1] "⊥"  BMS
 SG_ BMU12_Temp_2 : 15|8@0+ (1,-40) [1|1] "⊥"  BMS
 SG_ BMU12_Temp_3 : 23|8@0+ (1,-40) [1|1] "⊥"  BMS
 SG_ BMU12_Temp_4 : 31|8@0+ (1,-40) [1|1] "⊥"  BMS
 SG_ BMU12_Temp_5 : 39|8@0+ (1,-40) [1|1] "⊥"  BMS
 SG_ BMU12_Temp_6 : 47|8@0+ (1,-40) [1|1] "⊥"  BMS
 SG_ BMU12_Temp_7 : 55|8@0+ (1,-40) [1|1] "⊥"  BMS
 SG_ BMU12_Temp_8 : 63|8@0+ (1,-40) [1|1] "⊥"  BMS

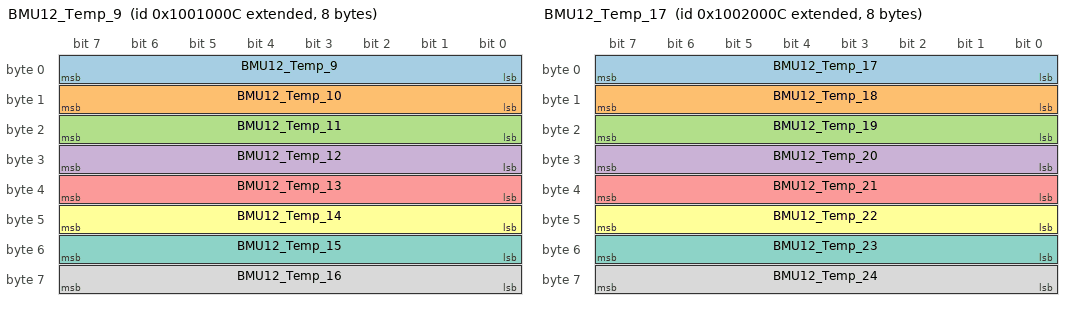
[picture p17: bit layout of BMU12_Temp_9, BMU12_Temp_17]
BO_ 2415984652 BMU12_Temp_9: 8 BMU
 SG_ BMU12_Temp_9 : 7|8@0+ (1,-40) [1|1] "⊥"  BMS
 SG_ BMU12_Temp_10 : 15|8@0+ (1,-40) [1|1] "⊥"  BMS
 SG_ BMU12_Temp_11 : 23|8@0+ (1,-40) [1|1] "⊥"  BMS
 SG_ BMU12_Temp_12 : 31|8@0+ (1,-40) [1|1] "⊥"  BMS
 SG_ BMU12_Temp_13 : 39|8@0+ (1,-40) [1|1] "⊥"  BMS
 SG_ BMU12_Temp_14 : 47|8@0+ (1,-40) [1|1] "⊥"  BMS
 SG_ BMU12_Temp_15 : 55|8@0+ (1,-40) [1|1] "⊥"  BMS
 SG_ BMU12_Temp_16 : 63|8@0+ (1,-40) [1|1] "⊥"  BMS

BO_ 2416050188 BMU12_Temp_17: 8 BMU
 SG_ BMU12_Temp_17 : 7|8@0+ (1,-40) [1|1] "⊥"  BMS
 SG_ BMU12_Temp_18 : 15|8@0+ (1,-40) [1|1] "⊥"  BMS
 SG_ BMU12_Temp_19 : 23|8@0+ (1,-40) [1|1] "⊥"  BMS
 SG_ BMU12_Temp_20 : 31|8@0+ (1,-40) [1|1] "⊥"  BMS
 SG_ BMU12_Temp_21 : 39|8@0+ (1,-40) [1|1] "⊥"  BMS
 SG_ BMU12_Temp_22 : 47|8@0+ (1,-40) [1|1] "⊥"  BMS
 SG_ BMU12_Temp_23 : 55|8@0+ (1,-40) [1|1] "⊥"  BMS
 SG_ BMU12_Temp_24 : 63|8@0+ (1,-40) [1|1] "⊥"  BMS

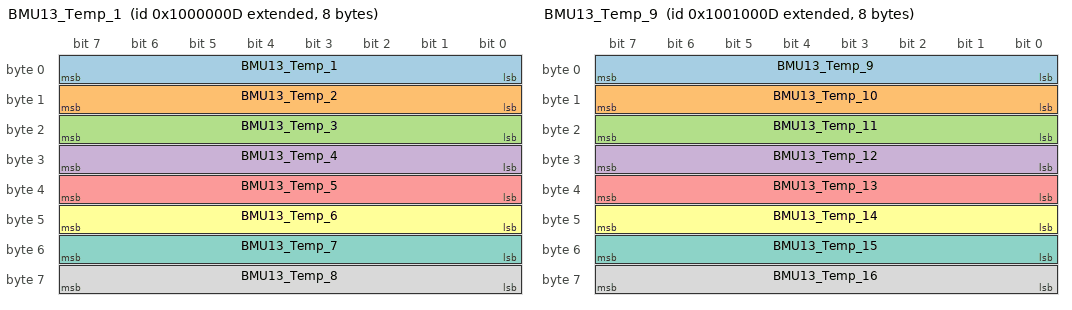
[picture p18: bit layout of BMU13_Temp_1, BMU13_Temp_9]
BO_ 2415919117 BMU13_Temp_1: 8 BMU
 SG_ BMU13_Temp_1 : 7|8@0+ (1,-40) [1|1] "⊥"  BMS
 SG_ BMU13_Temp_2 : 15|8@0+ (1,-40) [1|1] "⊥"  BMS
 SG_ BMU13_Temp_3 : 23|8@0+ (1,-40) [1|1] "⊥"  BMS
 SG_ BMU13_Temp_4 : 31|8@0+ (1,-40) [1|1] "⊥"  BMS
 SG_ BMU13_Temp_5 : 39|8@0+ (1,-40) [1|1] "⊥"  BMS
 SG_ BMU13_Temp_6 : 47|8@0+ (1,-40) [1|1] "⊥"  BMS
 SG_ BMU13_Temp_7 : 55|8@0+ (1,-40) [1|1] "⊥"  BMS
 SG_ BMU13_Temp_8 : 63|8@0+ (1,-40) [1|1] "⊥"  BMS

BO_ 2415984653 BMU13_Temp_9: 8 BMU
 SG_ BMU13_Temp_9 : 7|8@0+ (1,-40) [1|1] "⊥"  BMS
 SG_ BMU13_Temp_10 : 15|8@0+ (1,-40) [1|1] "⊥"  BMS
 SG_ BMU13_Temp_11 : 23|8@0+ (1,-40) [1|1] "⊥"  BMS
 SG_ BMU13_Temp_12 : 31|8@0+ (1,-40) [1|1] "⊥"  BMS
 SG_ BMU13_Temp_13 : 39|8@0+ (1,-40) [1|1] "⊥"  BMS
 SG_ BMU13_Temp_14 : 47|8@0+ (1,-40) [1|1] "⊥"  BMS
 SG_ BMU13_Temp_15 : 55|8@0+ (1,-40) [1|1] "⊥"  BMS
 SG_ BMU13_Temp_16 : 63|8@0+ (1,-40) [1|1] "⊥"  BMS

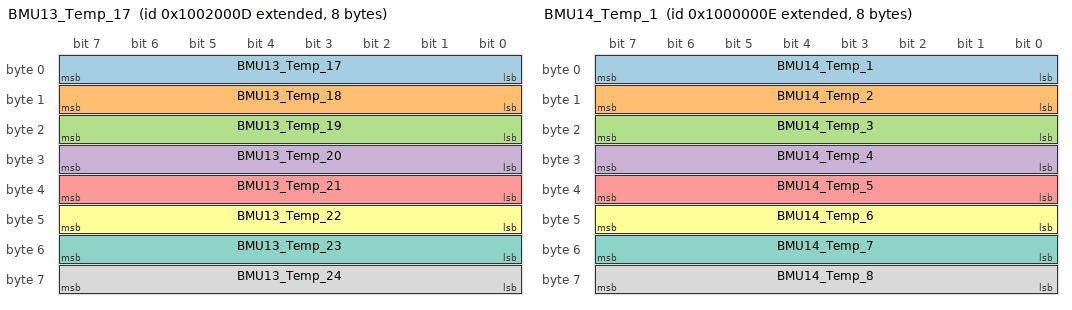
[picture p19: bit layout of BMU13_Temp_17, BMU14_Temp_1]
BO_ 2416050189 BMU13_Temp_17: 8 BMU
 SG_ BMU13_Temp_17 : 7|8@0+ (1,-40) [1|1] "⊥"  BMS
 SG_ BMU13_Temp_18 : 15|8@0+ (1,-40) [1|1] "⊥"  BMS
 SG_ BMU13_Temp_19 : 23|8@0+ (1,-40) [1|1] "⊥"  BMS
 SG_ BMU13_Temp_20 : 31|8@0+ (1,-40) [1|1] "⊥"  BMS
 SG_ BMU13_Temp_21 : 39|8@0+ (1,-40) [1|1] "⊥"  BMS
 SG_ BMU13_Temp_22 : 47|8@0+ (1,-40) [1|1] "⊥"  BMS
 SG_ BMU13_Temp_23 : 55|8@0+ (1,-40) [1|1] "⊥"  BMS
 SG_ BMU13_Temp_24 : 63|8@0+ (1,-40) [1|1] "⊥"  BMS

BO_ 2415919118 BMU14_Temp_1: 8 BMU
 SG_ BMU14_Temp_1 : 7|8@0+ (1,-40) [1|1] "⊥"  BMS
 SG_ BMU14_Temp_2 : 15|8@0+ (1,-40) [1|1] "⊥"  BMS
 SG_ BMU14_Temp_3 : 23|8@0+ (1,-40) [1|1] "⊥"  BMS
 SG_ BMU14_Temp_4 : 31|8@0+ (1,-40) [1|1] "⊥"  BMS
 SG_ BMU14_Temp_5 : 39|8@0+ (1,-40) [1|1] "⊥"  BMS
 SG_ BMU14_Temp_6 : 47|8@0+ (1,-40) [1|1] "⊥"  BMS
 SG_ BMU14_Temp_7 : 55|8@0+ (1,-40) [1|1] "⊥"  BMS
 SG_ BMU14_Temp_8 : 63|8@0+ (1,-40) [1|1] "⊥"  BMS

BO_ 2415984654 BMU14_Temp_9: 8 BMU
 SG_ BMU14_Temp_9 : 7|8@0+ (1,-40) [1|1] "⊥"  BMS
 SG_ BMU14_Temp_10 : 15|8@0+ (1,-40) [1|1] "⊥"  BMS
 SG_ BMU14_Temp_11 : 23|8@0+ (1,-40) [1|1] "⊥"  BMS
 SG_ BMU14_Temp_12 : 31|8@0+ (1,-40) [1|1] "⊥"  BMS
 SG_ BMU14_Temp_13 : 39|8@0+ (1,-40) [1|1] "⊥"  BMS
 SG_ BMU14_Temp_14 : 47|8@0+ (1,-40) [1|1] "⊥"  BMS
 SG_ BMU14_Temp_15 : 55|8@0+ (1,-40) [1|1] "⊥"  BMS
 SG_ BMU14_Temp_16 : 63|8@0+ (1,-40) [1|1] "⊥"  BMS

BO_ 2416050190 BMU14_Temp_17: 8 BMU
 SG_ BMU14_Temp_17 : 7|8@0+ (1,-40) [1|1] "⊥"  BMS
 SG_ BMU14_Temp_18 : 15|8@0+ (1,-40) [1|1] "⊥"  BMS
 SG_ BMU14_Temp_19 : 23|8@0+ (1,-40) [1|1] "⊥"  BMS
 SG_ BMU14_Temp_20 : 31|8@0+ (1,-40) [1|1] "⊥"  BMS
 SG_ BMU14_Temp_21 : 39|8@0+ (1,-40) [1|1] "⊥"  BMS
 SG_ BMU14_Temp_22 : 47|8@0+ (1,-40) [1|1] "⊥"  BMS
 SG_ BMU14_Temp_23 : 55|8@0+ (1,-40) [1|1] "⊥"  BMS
 SG_ BMU14_Temp_24 : 63|8@0+ (1,-40) [1|1] "⊥"  BMS

BO_ 2415919119 BMU15_Temp_1: 8 BMU
 SG_ BMU15_Temp_1 : 7|8@0+ (1,-40) [1|1] "⊥"  BMS
 SG_ BMU15_Temp_2 : 15|8@0+ (1,-40) [1|1] "⊥"  BMS
 SG_ BMU15_Temp_3 : 23|8@0+ (1,-40) [1|1] "⊥"  BMS
 SG_ BMU15_Temp_4 : 31|8@0+ (1,-40) [1|1] "⊥"  BMS
 SG_ BMU15_Temp_5 : 39|8@0+ (1,-40) [1|1] "⊥"  BMS
 SG_ BMU15_Temp_6 : 47|8@0+ (1,-40) [1|1] "⊥"  BMS
 SG_ BMU15_Temp_7 : 55|8@0+ (1,-40) [1|1] "⊥"  BMS
 SG_ BMU15_Temp_8 : 63|8@0+ (1,-40) [1|1] "⊥"  BMS

BO_ 2415984655 BMU15_Temp_9: 8 BMU
 SG_ BMU15_Temp_9 : 7|8@0+ (1,-40) [1|1] "⊥"  BMS
 SG_ BMU15_Temp_10 : 15|8@0+ (1,-40) [1|1] "⊥"  BMS
 SG_ BMU15_Temp_11 : 23|8@0+ (1,-40) [1|1] "⊥"  BMS
 SG_ BMU15_Temp_12 : 31|8@0+ (1,-40) [1|1] "⊥"  BMS
 SG_ BMU15_Temp_13 : 39|8@0+ (1,-40) [1|1] "⊥"  BMS
 SG_ BMU15_Temp_14 : 47|8@0+ (1,-40) [1|1] "⊥"  BMS
 SG_ BMU15_Temp_15 : 55|8@0+ (1,-40) [1|1] "⊥"  BMS
 SG_ BMU15_Temp_16 : 63|8@0+ (1,-40) [1|1] "⊥"  BMS

BO_ 2416050191 BMU15_Temp_17: 8 BMU
 SG_ BMU15_Temp_17 : 7|8@0+ (1,-40) [1|1] "⊥"  BMS
 SG_ BMU15_Temp_18 : 15|8@0+ (1,-40) [1|1] "⊥"  BMS
 SG_ BMU15_Temp_19 : 23|8@0+ (1,-40) [1|1] "⊥"  BMS
 SG_ BMU15_Temp_20 : 31|8@0+ (1,-40) [1|1] "⊥"  BMS
 SG_ BMU15_Temp_21 : 39|8@0+ (1,-40) [1|1] "⊥"  BMS
 SG_ BMU15_Temp_22 : 47|8@0+ (1,-40) [1|1] "⊥"  BMS
 SG_ BMU15_Temp_23 : 55|8@0+ (1,-40) [1|1] "⊥"  BMS
 SG_ BMU15_Temp_24 : 63|8@0+ (1,-40) [1|1] "⊥"  BMS

BO_ 2415919120 BMU16_Temp_1: 8 BMU
 SG_ BMU16_Temp_1 : 7|8@0+ (1,-40) [1|1] "⊥"  BMS
 SG_ BMU16_Temp_2 : 15|8@0+ (1,-40) [1|1] "⊥"  BMS
 SG_ BMU16_Temp_3 : 23|8@0+ (1,-40) [1|1] "⊥"  BMS
 SG_ BMU16_Temp_4 : 31|8@0+ (1,-40) [1|1] "⊥"  BMS
 SG_ BMU16_Temp_5 : 39|8@0+ (1,-40) [1|1] "⊥"  BMS
 SG_ BMU16_Temp_6 : 47|8@0+ (1,-40) [1|1] "⊥"  BMS
 SG_ BMU16_Temp_7 : 55|8@0+ (1,-40) [1|1] "⊥"  BMS
 SG_ BMU16_Temp_8 : 63|8@0+ (1,-40) [1|1] "⊥"  BMS

BO_ 2415984656 BMU16_Temp_9: 8 BMU
 SG_ BMU16_Temp_9 : 7|8@0+ (1,-40) [1|1] "⊥"  BMS
 SG_ BMU16_Temp_10 : 15|8@0+ (1,-40) [1|1] "⊥"  BMS
 SG_ BMU16_Temp_11 : 23|8@0+ (1,-40) [1|1] "⊥"  BMS
 SG_ BMU16_Temp_12 : 31|8@0+ (1,-40) [1|1] "⊥"  BMS
 SG_ BMU16_Temp_13 : 39|8@0+ (1,-40) [1|1] "⊥"  BMS
 SG_ BMU16_Temp_14 : 47|8@0+ (1,-40) [1|1] "⊥"  BMS
 SG_ BMU16_Temp_15 : 55|8@0+ (1,-40) [1|1] "⊥"  BMS
 SG_ BMU16_Temp_16 : 63|8@0+ (1,-40) [1|1] "⊥"  BMS

BO_ 2416050192 BMU16_Temp_17: 8 BMU
 SG_ BMU16_Temp_17 : 7|8@0+ (1,-40) [1|1] "⊥"  BMS
 SG_ BMU16_Temp_18 : 15|8@0+ (1,-40) [1|1] "⊥"  BMS
 SG_ BMU16_Temp_19 : 23|8@0+ (1,-40) [1|1] "⊥"  BMS
 SG_ BMU16_Temp_20 : 31|8@0+ (1,-40) [1|1] "⊥"  BMS
 SG_ BMU16_Temp_21 : 39|8@0+ (1,-40) [1|1] "⊥"  BMS
 SG_ BMU16_Temp_22 : 47|8@0+ (1,-40) [1|1] "⊥"  BMS
 SG_ BMU16_Temp_23 : 55|8@0+ (1,-40) [1|1] "⊥"  BMS
 SG_ BMU16_Temp_24 : 63|8@0+ (1,-40) [1|1] "⊥"  BMS

BO_ 2415919121 BMU17_Temp_1: 8 BMU
 SG_ BMU17_Temp_1 : 7|8@0+ (1,-40) [1|1] "⊥"  BMS
 SG_ BMU17_Temp_2 : 15|8@0+ (1,-40) [1|1] "⊥"  BMS
 SG_ BMU17_Temp_3 : 23|8@0+ (1,-40) [1|1] "⊥"  BMS
 SG_ BMU17_Temp_4 : 31|8@0+ (1,-40) [1|1] "⊥"  BMS
 SG_ BMU17_Temp_5 : 39|8@0+ (1,-40) [1|1] "⊥"  BMS
 SG_ BMU17_Temp_6 : 47|8@0+ (1,-40) [1|1] "⊥"  BMS
 SG_ BMU17_Temp_7 : 55|8@0+ (1,-40) [1|1] "⊥"  BMS
 SG_ BMU17_Temp_8 : 63|8@0+ (1,-40) [1|1] "⊥"  BMS

BO_ 2415984657 BMU17_Temp_9: 8 BMU
 SG_ BMU17_Temp_9 : 7|8@0+ (1,-40) [1|1] "⊥"  BMS
 SG_ BMU17_Temp_10 : 15|8@0+ (1,-40) [1|1] "⊥"  BMS
 SG_ BMU17_Temp_11 : 23|8@0+ (1,-40) [1|1] "⊥"  BMS
 SG_ BMU17_Temp_12 : 31|8@0+ (1,-40) [1|1] "⊥"  BMS
 SG_ BMU17_Temp_13 : 39|8@0+ (1,-40) [1|1] "⊥"  BMS
 SG_ BMU17_Temp_14 : 47|8@0+ (1,-40) [1|1] "⊥"  BMS
 SG_ BMU17_Temp_15 : 55|8@0+ (1,-40) [1|1] "⊥"  BMS
 SG_ BMU17_Temp_16 : 63|8@0+ (1,-40) [1|1] "⊥"  BMS

BO_ 2416050193 BMU17_Temp_17: 8 BMU
 SG_ BMU17_Temp_17 : 7|8@0+ (1,-40) [1|1] "⊥"  BMS
 SG_ BMU17_Temp_18 : 15|8@0+ (1,-40) [1|1] "⊥"  BMS
 SG_ BMU17_Temp_19 : 23|8@0+ (1,-40) [1|1] "⊥"  BMS
 SG_ BMU17_Temp_20 : 31|8@0+ (1,-40) [1|1] "⊥"  BMS
 SG_ BMU17_Temp_21 : 39|8@0+ (1,-40) [1|1] "⊥"  BMS
 SG_ BMU17_Temp_22 : 47|8@0+ (1,-40) [1|1] "⊥"  BMS
 SG_ BMU17_Temp_23 : 55|8@0+ (1,-40) [1|1] "⊥"  BMS
 SG_ BMU17_Temp_24 : 63|8@0+ (1,-40) [1|1] "⊥"  BMS

BO_ 2415919122 BMU18_Temp_1: 8 BMU
 SG_ BMU18_Temp_1 : 7|8@0+ (1,-40) [1|1] "⊥"  BMS
 SG_ BMU18_Temp_2 : 15|8@0+ (1,-40) [1|1] "⊥"  BMS
 SG_ BMU18_Temp_3 : 23|8@0+ (1,-40) [1|1] "⊥"  BMS
 SG_ BMU18_Temp_4 : 31|8@0+ (1,-40) [1|1] "⊥"  BMS
 SG_ BMU18_Temp_5 : 39|8@0+ (1,-40) [1|1] "⊥"  BMS
 SG_ BMU18_Temp_6 : 47|8@0+ (1,-40) [1|1] "⊥"  BMS
 SG_ BMU18_Temp_7 : 55|8@0+ (1,-40) [1|1] "⊥"  BMS
 SG_ BMU18_Temp_8 : 63|8@0+ (1,-40) [1|1] "⊥"  BMS

BO_ 2415984658 BMU18_Temp_9: 8 BMU
 SG_ BMU18_Temp_9 : 7|8@0+ (1,-40) [1|1] "⊥"  BMS
 SG_ BMU18_Temp_10 : 15|8@0+ (1,-40) [1|1] "⊥"  BMS
 SG_ BMU18_Temp_11 : 23|8@0+ (1,-40) [1|1] "⊥"  BMS
 SG_ BMU18_Temp_12 : 31|8@0+ (1,-40) [1|1] "⊥"  BMS
 SG_ BMU18_Temp_13 : 39|8@0+ (1,-40) [1|1] "⊥"  BMS
 SG_ BMU18_Temp_14 : 47|8@0+ (1,-40) [1|1] "⊥"  BMS
 SG_ BMU18_Temp_15 : 55|8@0+ (1,-40) [1|1] "⊥"  BMS
 SG_ BMU18_Temp_16 : 63|8@0+ (1,-40) [1|1] "⊥"  BMS

BO_ 2416050194 BMU18_Temp_17: 8 BMU
 SG_ BMU18_Temp_17 : 7|8@0+ (1,-40) [1|1] "⊥"  BMS
 SG_ BMU18_Temp_18 : 15|8@0+ (1,-40) [1|1] "⊥"  BMS
 SG_ BMU18_Temp_19 : 23|8@0+ (1,-40) [1|1] "⊥"  BMS
 SG_ BMU18_Temp_20 : 31|8@0+ (1,-40) [1|1] "⊥"  BMS
 SG_ BMU18_Temp_21 : 39|8@0+ (1,-40) [1|1] "⊥"  BMS
 SG_ BMU18_Temp_22 : 47|8@0+ (1,-40) [1|1] "⊥"  BMS
 SG_ BMU18_Temp_23 : 55|8@0+ (1,-40) [1|1] "⊥"  BMS
 SG_ BMU18_Temp_24 : 63|8@0+ (1,-40) [1|1] "⊥"  BMS

BO_ 2415919123 BMU19_Temp_1: 8 BMU
 SG_ BMU19_Temp_1 : 7|8@0+ (1,-40) [1|1] "⊥"  BMS
 SG_ BMU19_Temp_2 : 15|8@0+ (1,-40) [1|1] "⊥"  BMS
 SG_ BMU19_Temp_3 : 23|8@0+ (1,-40) [1|1] "⊥"  BMS
 SG_ BMU19_Temp_4 : 31|8@0+ (1,-40) [1|1] "⊥"  BMS
 SG_ BMU19_Temp_5 : 39|8@0+ (1,-40) [1|1] "⊥"  BMS
 SG_ BMU19_Temp_6 : 47|8@0+ (1,-40) [1|1] "⊥"  BMS
 SG_ BMU19_Temp_7 : 55|8@0+ (1,-40) [1|1] "⊥"  BMS
 SG_ BMU19_Temp_8 : 63|8@0+ (1,-40) [1|1] "⊥"  BMS

BO_ 2415984659 BMU19_Temp_9: 8 BMU
 SG_ BMU19_Temp_9 : 7|8@0+ (1,-40) [1|1] "⊥"  BMS
 SG_ BMU19_Temp_10 : 15|8@0+ (1,-40) [1|1] "⊥"  BMS
 SG_ BMU19_Temp_11 : 23|8@0+ (1,-40) [1|1] "⊥"  BMS
 SG_ BMU19_Temp_12 : 31|8@0+ (1,-40) [1|1] "⊥"  BMS
 SG_ BMU19_Temp_13 : 39|8@0+ (1,-40) [1|1] "⊥"  BMS
 SG_ BMU19_Temp_14 : 47|8@0+ (1,-40) [1|1] "⊥"  BMS
 SG_ BMU19_Temp_15 : 55|8@0+ (1,-40) [1|1] "⊥"  BMS
 SG_ BMU19_Temp_16 : 63|8@0+ (1,-40) [1|1] "⊥"  BMS

BO_ 2416050195 BMU19_Temp_17: 8 BMU
 SG_ BMU19_Temp_17 : 7|8@0+ (1,-40) [1|1] "⊥"  BMS
 SG_ BMU19_Temp_18 : 15|8@0+ (1,-40) [1|1] "⊥"  BMS
 SG_ BMU19_Temp_19 : 23|8@0+ (1,-40) [1|1] "⊥"  BMS
 SG_ BMU19_Temp_20 : 31|8@0+ (1,-40) [1|1] "⊥"  BMS
 SG_ BMU19_Temp_21 : 39|8@0+ (1,-40) [1|1] "⊥"  BMS
 SG_ BMU19_Temp_22 : 47|8@0+ (1,-40) [1|1] "⊥"  BMS
 SG_ BMU19_Temp_23 : 55|8@0+ (1,-40) [1|1] "⊥"  BMS
 SG_ BMU19_Temp_24 : 63|8@0+ (1,-40) [1|1] "⊥"  BMS

BO_ 2415919124 BMU20_Temp_1: 8 BMU
 SG_ BMU20_Temp_1 : 7|8@0+ (1,-40) [1|1] "⊥"  BMS
 SG_ BMU20_Temp_2 : 15|8@0+ (1,-40) [1|1] "⊥"  BMS
 SG_ BMU20_Temp_3 : 23|8@0+ (1,-40) [1|1] "⊥"  BMS
 SG_ BMU20_Temp_4 : 31|8@0+ (1,-40) [1|1] "⊥"  BMS
 SG_ BMU20_Temp_5 : 39|8@0+ (1,-40) [1|1] "⊥"  BMS
 SG_ BMU20_Temp_6 : 47|8@0+ (1,-40) [1|1] "⊥"  BMS
 SG_ BMU20_Temp_7 : 55|8@0+ (1,-40) [1|1] "⊥"  BMS
 SG_ BMU20_Temp_8 : 63|8@0+ (1,-40) [1|1] "⊥"  BMS

BO_ 2415984660 BMU20_Temp_9: 8 BMU
 SG_ BMU20_Temp_9 : 7|8@0+ (1,-40) [1|1] "⊥"  BMS
 SG_ BMU20_Temp_10 : 15|8@0+ (1,-40) [1|1] "⊥"  BMS
 SG_ BMU20_Temp_11 : 23|8@0+ (1,-40) [1|1] "⊥"  BMS
 SG_ BMU20_Temp_12 : 31|8@0+ (1,-40) [1|1] "⊥"  BMS
 SG_ BMU20_Temp_13 : 39|8@0+ (1,-40) [1|1] "⊥"  BMS
 SG_ BMU20_Temp_14 : 47|8@0+ (1,-40) [1|1] "⊥"  BMS
 SG_ BMU20_Temp_15 : 55|8@0+ (1,-40) [1|1] "⊥"  BMS
 SG_ BMU20_Temp_16 : 63|8@0+ (1,-40) [1|1] "⊥"  BMS

BO_ 2416050196 BMU20_Temp_17: 8 BMU
 SG_ BMU20_Temp_17 : 7|8@0+ (1,-40) [1|1] "⊥"  BMS
 SG_ BMU20_Temp_18 : 15|8@0+ (1,-40) [1|1] "⊥"  BMS
 SG_ BMU20_Temp_19 : 23|8@0+ (1,-40) [1|1] "⊥"  BMS
 SG_ BMU20_Temp_20 : 31|8@0+ (1,-40) [1|1] "⊥"  BMS
 SG_ BMU20_Temp_21 : 39|8@0+ (1,-40) [1|1] "⊥"  BMS
 SG_ BMU20_Temp_22 : 47|8@0+ (1,-40) [1|1] "⊥"  BMS
 SG_ BMU20_Temp_23 : 55|8@0+ (1,-40) [1|1] "⊥"  BMS
 SG_ BMU20_Temp_24 : 63|8@0+ (1,-40) [1|1] "⊥"  BMS

BO_ 2415919125 BMU21_Temp_1: 8 BMU
 SG_ BMU21_Temp_1 : 7|8@0+ (1,-40) [1|1] "⊥"  BMS
 SG_ BMU21_Temp_2 : 15|8@0+ (1,-40) [1|1] "⊥"  BMS
 SG_ BMU21_Temp_3 : 23|8@0+ (1,-40) [1|1] "⊥"  BMS
 SG_ BMU21_Temp_4 : 31|8@0+ (1,-40) [1|1] "⊥"  BMS
 SG_ BMU21_Temp_5 : 39|8@0+ (1,-40) [1|1] "⊥"  BMS
 SG_ BMU21_Temp_6 : 47|8@0+ (1,-40) [1|1] "⊥"  BMS
 SG_ BMU21_Temp_7 : 55|8@0+ (1,-40) [1|1] "⊥"  BMS
 SG_ BMU21_Temp_8 : 63|8@0+ (1,-40) [1|1] "⊥"  BMS

BO_ 2415984661 BMU21_Temp_9: 8 BMU
 SG_ BMU21_Temp_9 : 7|8@0+ (1,-40) [1|1] "⊥"  BMS
 SG_ BMU21_Temp_10 : 15|8@0+ (1,-40) [1|1] "⊥"  BMS
 SG_ BMU21_Temp_11 : 23|8@0+ (1,-40) [1|1] "⊥"  BMS
 SG_ BMU21_Temp_12 : 31|8@0+ (1,-40) [1|1] "⊥"  BMS
 SG_ BMU21_Temp_13 : 39|8@0+ (1,-40) [1|1] "⊥"  BMS
 SG_ BMU21_Temp_14 : 47|8@0+ (1,-40) [1|1] "⊥"  BMS
 SG_ BMU21_Temp_15 : 55|8@0+ (1,-40) [1|1] "⊥"  BMS
 SG_ BMU21_Temp_16 : 63|8@0+ (1,-40) [1|1] "⊥"  BMS

BO_ 2416050197 BMU21_Temp_17: 8 BMU
 SG_ BMU21_Temp_17 : 7|8@0+ (1,-40) [1|1] "⊥"  BMS
 SG_ BMU21_Temp_18 : 15|8@0+ (1,-40) [1|1] "⊥"  BMS
 SG_ BMU21_Temp_19 : 23|8@0+ (1,-40) [1|1] "⊥"  BMS
 SG_ BMU21_Temp_20 : 31|8@0+ (1,-40) [1|1] "⊥"  BMS
 SG_ BMU21_Temp_21 : 39|8@0+ (1,-40) [1|1] "⊥"  BMS
 SG_ BMU21_Temp_22 : 47|8@0+ (1,-40) [1|1] "⊥"  BMS
 SG_ BMU21_Temp_23 : 55|8@0+ (1,-40) [1|1] "⊥"  BMS
 SG_ BMU21_Temp_24 : 63|8@0+ (1,-40) [1|1] "⊥"  BMS

BO_ 2415919126 BMU22_Temp_1: 8 BMU
 SG_ BMU22_Temp_1 : 7|8@0+ (1,-40) [1|1] "⊥"  BMS
 SG_ BMU22_Temp_2 : 15|8@0+ (1,-40) [1|1] "⊥"  BMS
 SG_ BMU22_Temp_3 : 23|8@0+ (1,-40) [1|1] "⊥"  BMS
 SG_ BMU22_Temp_4 : 31|8@0+ (1,-40) [1|1] "⊥"  BMS
 SG_ BMU22_Temp_5 : 39|8@0+ (1,-40) [1|1] "⊥"  BMS
 SG_ BMU22_Temp_6 : 47|8@0+ (1,-40) [1|1] "⊥"  BMS
 SG_ BMU22_Temp_7 : 55|8@0+ (1,-40) [1|1] "⊥"  BMS
 SG_ BMU22_Temp_8 : 63|8@0+ (1,-40) [1|1] "⊥"  BMS

BO_ 2415984662 BMU22_Temp_9: 8 BMU
 SG_ BMU22_Temp_9 : 7|8@0+ (1,-40) [1|1] "⊥"  BMS
 SG_ BMU22_Temp_10 : 15|8@0+ (1,-40) [1|1] "⊥"  BMS
 SG_ BMU22_Temp_11 : 23|8@0+ (1,-40) [1|1] "⊥"  BMS
 SG_ BMU22_Temp_12 : 31|8@0+ (1,-40) [1|1] "⊥"  BMS
 SG_ BMU22_Temp_13 : 39|8@0+ (1,-40) [1|1] "⊥"  BMS
 SG_ BMU22_Temp_14 : 47|8@0+ (1,-40) [1|1] "⊥"  BMS
 SG_ BMU22_Temp_15 : 55|8@0+ (1,-40) [1|1] "⊥"  BMS
 SG_ BMU22_Temp_16 : 63|8@0+ (1,-40) [1|1] "⊥"  BMS

BO_ 2416050198 BMU22_Temp_17: 8 BMU
 SG_ BMU22_Temp_17 : 7|8@0+ (1,-40) [1|1] "⊥"  BMS
 SG_ BMU22_Temp_18 : 15|8@0+ (1,-40) [1|1] "⊥"  BMS
 SG_ BMU22_Temp_19 : 23|8@0+ (1,-40) [1|1] "⊥"  BMS
 SG_ BMU22_Temp_20 : 31|8@0+ (1,-40) [1|1] "⊥"  BMS
 SG_ BMU22_Temp_21 : 39|8@0+ (1,-40) [1|1] "⊥"  BMS
 SG_ BMU22_Temp_22 : 47|8@0+ (1,-40) [1|1] "⊥"  BMS
 SG_ BMU22_Temp_23 : 55|8@0+ (1,-40) [1|1] "⊥"  BMS
 SG_ BMU22_Temp_24 : 63|8@0+ (1,-40) [1|1] "⊥"  BMS

BO_ 2415919127 BMU23_Temp_1: 8 BMU
 SG_ BMU23_Temp_1 : 7|8@0+ (1,-40) [1|1] "⊥"  BMS
 SG_ BMU23_Temp_2 : 15|8@0+ (1,-40) [1|1] "⊥"  BMS
 SG_ BMU23_Temp_3 : 23|8@0+ (1,-40) [1|1] "⊥"  BMS
 SG_ BMU23_Temp_4 : 31|8@0+ (1,-40) [1|1] "⊥"  BMS
 SG_ BMU23_Temp_5 : 39|8@0+ (1,-40) [1|1] "⊥"  BMS
 SG_ BMU23_Temp_6 : 47|8@0+ (1,-40) [1|1] "⊥"  BMS
 SG_ BMU23_Temp_7 : 55|8@0+ (1,-40) [1|1] "⊥"  BMS
 SG_ BMU23_Temp_8 : 63|8@0+ (1,-40) [1|1] "⊥"  BMS

BO_ 2415984663 BMU23_Temp_9: 8 BMU
 SG_ BMU23_Temp_9 : 7|8@0+ (1,-40) [1|1] "⊥"  BMS
 SG_ BMU23_Temp_10 : 15|8@0+ (1,-40) [1|1] "⊥"  BMS
 SG_ BMU23_Temp_11 : 23|8@0+ (1,-40) [1|1] "⊥"  BMS
 SG_ BMU23_Temp_12 : 31|8@0+ (1,-40) [1|1] "⊥"  BMS
 SG_ BMU23_Temp_13 : 39|8@0+ (1,-40) [1|1] "⊥"  BMS
 SG_ BMU23_Temp_14 : 47|8@0+ (1,-40) [1|1] "⊥"  BMS
 SG_ BMU23_Temp_15 : 55|8@0+ (1,-40) [1|1] "⊥"  BMS
 SG_ BMU23_Temp_16 : 63|8@0+ (1,-40) [1|1] "⊥"  BMS

BO_ 2416050199 BMU23_Temp_17: 8 BMU
 SG_ BMU23_Temp_17 : 7|8@0+ (1,-40) [1|1] "⊥"  BMS
 SG_ BMU23_Temp_18 : 15|8@0+ (1,-40) [1|1] "⊥"  BMS
 SG_ BMU23_Temp_19 : 23|8@0+ (1,-40) [1|1] "⊥"  BMS
 SG_ BMU23_Temp_20 : 31|8@0+ (1,-40) [1|1] "⊥"  BMS
 SG_ BMU23_Temp_21 : 39|8@0+ (1,-40) [1|1] "⊥"  BMS
 SG_ BMU23_Temp_22 : 47|8@0+ (1,-40) [1|1] "⊥"  BMS
 SG_ BMU23_Temp_23 : 55|8@0+ (1,-40) [1|1] "⊥"  BMS
 SG_ BMU23_Temp_24 : 63|8@0+ (1,-40) [1|1] "⊥"  BMS

BO_ 2415919128 BMU24_Temp_1: 8 BMU
 SG_ BMU24_Temp_1 : 7|8@0+ (1,-40) [1|1] "⊥"  BMS
 SG_ BMU24_Temp_2 : 15|8@0+ (1,-40) [1|1] "⊥"  BMS
 SG_ BMU24_Temp_3 : 23|8@0+ (1,-40) [1|1] "⊥"  BMS
 SG_ BMU24_Temp_4 : 31|8@0+ (1,-40) [1|1] "⊥"  BMS
 SG_ BMU24_Temp_5 : 39|8@0+ (1,-40) [1|1] "⊥"  BMS
 SG_ BMU24_Temp_6 : 47|8@0+ (1,-40) [1|1] "⊥"  BMS
 SG_ BMU24_Temp_7 : 55|8@0+ (1,-40) [1|1] "⊥"  BMS
 SG_ BMU24_Temp_8 : 63|8@0+ (1,-40) [1|1] "⊥"  BMS

BO_ 2415984664 BMU24_Temp_9: 8 BMU
 SG_ BMU24_Temp_9 : 7|8@0+ (1,-40) [1|1] "⊥"  BMS
 SG_ BMU24_Temp_10 : 15|8@0+ (1,-40) [1|1] "⊥"  BMS
 SG_ BMU24_Temp_11 : 23|8@0+ (1,-40) [1|1] "⊥"  BMS
 SG_ BMU24_Temp_12 : 31|8@0+ (1,-40) [1|1] "⊥"  BMS
 SG_ BMU24_Temp_13 : 39|8@0+ (1,-40) [1|1] "⊥"  BMS
 SG_ BMU24_Temp_14 : 47|8@0+ (1,-40) [1|1] "⊥"  BMS
 SG_ BMU24_Temp_15 : 55|8@0+ (1,-40) [1|1] "⊥"  BMS
 SG_ BMU24_Temp_16 : 63|8@0+ (1,-40) [1|1] "⊥"  BMS

BO_ 2416050200 BMU24_Temp_17: 8 BMU
 SG_ BMU24_Temp_17 : 7|8@0+ (1,-40) [1|1] "⊥"  BMS
 SG_ BMU24_Temp_18 : 15|8@0+ (1,-40) [1|1] "⊥"  BMS
 SG_ BMU24_Temp_19 : 23|8@0+ (1,-40) [1|1] "⊥"  BMS
 SG_ BMU24_Temp_20 : 31|8@0+ (1,-40) [1|1] "⊥"  BMS
 SG_ BMU24_Temp_21 : 39|8@0+ (1,-40) [1|1] "⊥"  BMS
 SG_ BMU24_Temp_22 : 47|8@0+ (1,-40) [1|1] "⊥"  BMS
 SG_ BMU24_Temp_23 : 55|8@0+ (1,-40) [1|1] "⊥"  BMS
 SG_ BMU24_Temp_24 : 63|8@0+ (1,-40) [1|1] "⊥"  BMS

BO_ 2415919129 BMU25_Temp_1: 8 BMU
 SG_ BMU25_Temp_1 : 7|8@0+ (1,-40) [1|1] "⊥"  BMS
 SG_ BMU25_Temp_2 : 15|8@0+ (1,-40) [1|1] "⊥"  BMS
 SG_ BMU25_Temp_3 : 23|8@0+ (1,-40) [1|1] "⊥"  BMS
 SG_ BMU25_Temp_4 : 31|8@0+ (1,-40) [1|1] "⊥"  BMS
 SG_ BMU25_Temp_5 : 39|8@0+ (1,-40) [1|1] "⊥"  BMS
 SG_ BMU25_Temp_6 : 47|8@0+ (1,-40) [1|1] "⊥"  BMS
 SG_ BMU25_Temp_7 : 55|8@0+ (1,-40) [1|1] "⊥"  BMS
 SG_ BMU25_Temp_8 : 63|8@0+ (1,-40) [1|1] "⊥"  BMS

BO_ 2415984665 BMU25_Temp_9: 8 BMU
 SG_ BMU25_Temp_9 : 7|8@0+ (1,-40) [1|1] "⊥"  BMS
 SG_ BMU25_Temp_10 : 15|8@0+ (1,-40) [1|1] "⊥"  BMS
 SG_ BMU25_Temp_11 : 23|8@0+ (1,-40) [1|1] "⊥"  BMS
 SG_ BMU25_Temp_12 : 31|8@0+ (1,-40) [1|1] "⊥"  BMS
 SG_ BMU25_Temp_13 : 39|8@0+ (1,-40) [1|1] "⊥"  BMS
 SG_ BMU25_Temp_14 : 47|8@0+ (1,-40) [1|1] "⊥"  BMS
 SG_ BMU25_Temp_15 : 55|8@0+ (1,-40) [1|1] "⊥"  BMS
 SG_ BMU25_Temp_16 : 63|8@0+ (1,-40) [1|1] "⊥"  BMS

BO_ 2416050201 BMU25_Temp_17: 8 BMU
 SG_ BMU25_Temp_17 : 7|8@0+ (1,-40) [1|1] "⊥"  BMS
 SG_ BMU25_Temp_18 : 15|8@0+ (1,-40) [1|1] "⊥"  BMS
 SG_ BMU25_Temp_19 : 23|8@0+ (1,-40) [1|1] "⊥"  BMS
 SG_ BMU25_Temp_20 : 31|8@0+ (1,-40) [1|1] "⊥"  BMS
 SG_ BMU25_Temp_21 : 39|8@0+ (1,-40) [1|1] "⊥"  BMS
 SG_ BMU25_Temp_22 : 47|8@0+ (1,-40) [1|1] "⊥"  BMS
 SG_ BMU25_Temp_23 : 55|8@0+ (1,-40) [1|1] "⊥"  BMS
 SG_ BMU25_Temp_24 : 63|8@0+ (1,-40) [1|1] "⊥"  BMS

BO_ 2415919130 BMU26_Temp_1: 8 BMU
 SG_ BMU26_Temp_1 : 7|8@0+ (1,-40) [1|1] "⊥"  BMS
 SG_ BMU26_Temp_2 : 15|8@0+ (1,-40) [1|1] "⊥"  BMS
 SG_ BMU26_Temp_3 : 23|8@0+ (1,-40) [1|1] "⊥"  BMS
 SG_ BMU26_Temp_4 : 31|8@0+ (1,-40) [1|1] "⊥"  BMS
 SG_ BMU26_Temp_5 : 39|8@0+ (1,-40) [1|1] "⊥"  BMS
 SG_ BMU26_Temp_6 : 47|8@0+ (1,-40) [1|1] "⊥"  BMS
 SG_ BMU26_Temp_7 : 55|8@0+ (1,-40) [1|1] "⊥"  BMS
 SG_ BMU26_Temp_8 : 63|8@0+ (1,-40) [1|1] "⊥"  BMS

BO_ 2415984666 BMU26_Temp_9: 8 BMU
 SG_ BMU26_Temp_9 : 7|8@0+ (1,-40) [1|1] "⊥"  BMS
 SG_ BMU26_Temp_10 : 15|8@0+ (1,-40) [1|1] "⊥"  BMS
 SG_ BMU26_Temp_11 : 23|8@0+ (1,-40) [1|1] "⊥"  BMS
 SG_ BMU26_Temp_12 : 31|8@0+ (1,-40) [1|1] "⊥"  BMS
 SG_ BMU26_Temp_13 : 39|8@0+ (1,-40) [1|1] "⊥"  BMS
 SG_ BMU26_Temp_14 : 47|8@0+ (1,-40) [1|1] "⊥"  BMS
 SG_ BMU26_Temp_15 : 55|8@0+ (1,-40) [1|1] "⊥"  BMS
 SG_ BMU26_Temp_16 : 63|8@0+ (1,-40) [1|1] "⊥"  BMS

BO_ 2416050202 BMU26_Temp_17: 8 BMU
 SG_ BMU26_Temp_17 : 7|8@0+ (1,-40) [1|1] "⊥"  BMS
 SG_ BMU26_Temp_18 : 15|8@0+ (1,-40) [1|1] "⊥"  BMS
 SG_ BMU26_Temp_19 : 23|8@0+ (1,-40) [1|1] "⊥"  BMS
 SG_ BMU26_Temp_20 : 31|8@0+ (1,-40) [1|1] "⊥"  BMS
 SG_ BMU26_Temp_21 : 39|8@0+ (1,-40) [1|1] "⊥"  BMS
 SG_ BMU26_Temp_22 : 47|8@0+ (1,-40) [1|1] "⊥"  BMS
 SG_ BMU26_Temp_23 : 55|8@0+ (1,-40) [1|1] "⊥"  BMS
 SG_ BMU26_Temp_24 : 63|8@0+ (1,-40) [1|1] "⊥"  BMS

BO_ 2415919131 BMU27_Temp_1: 8 BMU
 SG_ BMU27_Temp_1 : 7|8@0+ (1,-40) [1|1] "⊥"  BMS
 SG_ BMU27_Temp_2 : 15|8@0+ (1,-40) [1|1] "⊥"  BMS
 SG_ BMU27_Temp_3 : 23|8@0+ (1,-40) [1|1] "⊥"  BMS
 SG_ BMU27_Temp_4 : 31|8@0+ (1,-40) [1|1] "⊥"  BMS
 SG_ BMU27_Temp_5 : 39|8@0+ (1,-40) [1|1] "⊥"  BMS
 SG_ BMU27_Temp_6 : 47|8@0+ (1,-40) [1|1] "⊥"  BMS
 SG_ BMU27_Temp_7 : 55|8@0+ (1,-40) [1|1] "⊥"  BMS
 SG_ BMU27_Temp_8 : 63|8@0+ (1,-40) [1|1] "⊥"  BMS

BO_ 2415984667 BMU27_Temp_9: 8 BMU
 SG_ BMU27_Temp_9 : 7|8@0+ (1,-40) [1|1] "⊥"  BMS
 SG_ BMU27_Temp_10 : 15|8@0+ (1,-40) [1|1] "⊥"  BMS
 SG_ BMU27_Temp_11 : 23|8@0+ (1,-40) [1|1] "⊥"  BMS
 SG_ BMU27_Temp_12 : 31|8@0+ (1,-40) [1|1] "⊥"  BMS
 SG_ BMU27_Temp_13 : 39|8@0+ (1,-40) [1|1] "⊥"  BMS
 SG_ BMU27_Temp_14 : 47|8@0+ (1,-40) [1|1] "⊥"  BMS
 SG_ BMU27_Temp_15 : 55|8@0+ (1,-40) [1|1] "⊥"  BMS
 SG_ BMU27_Temp_16 : 63|8@0+ (1,-40) [1|1] "⊥"  BMS

BO_ 2416050203 BMU27_Temp_17: 8 BMU
 SG_ BMU27_Temp_17 : 7|8@0+ (1,-40) [1|1] "⊥"  BMS
 SG_ BMU27_Temp_18 : 15|8@0+ (1,-40) [1|1] "⊥"  BMS
 SG_ BMU27_Temp_19 : 23|8@0+ (1,-40) [1|1] "⊥"  BMS
 SG_ BMU27_Temp_20 : 31|8@0+ (1,-40) [1|1] "⊥"  BMS
 SG_ BMU27_Temp_21 : 39|8@0+ (1,-40) [1|1] "⊥"  BMS
 SG_ BMU27_Temp_22 : 47|8@0+ (1,-40) [1|1] "⊥"  BMS
 SG_ BMU27_Temp_23 : 55|8@0+ (1,-40) [1|1] "⊥"  BMS
 SG_ BMU27_Temp_24 : 63|8@0+ (1,-40) [1|1] "⊥"  BMS

BO_ 2415919132 BMU28_Temp_1: 8 BMU
 SG_ BMU28_Temp_1 : 7|8@0+ (1,-40) [1|1] "⊥"  BMS
 SG_ BMU28_Temp_2 : 15|8@0+ (1,-40) [1|1] "⊥"  BMS
 SG_ BMU28_Temp_3 : 23|8@0+ (1,-40) [1|1] "⊥"  BMS
 SG_ BMU28_Temp_4 : 31|8@0+ (1,-40) [1|1] "⊥"  BMS
 SG_ BMU28_Temp_5 : 39|8@0+ (1,-40) [1|1] "⊥"  BMS
 SG_ BMU28_Temp_6 : 47|8@0+ (1,-40) [1|1] "⊥"  BMS
 SG_ BMU28_Temp_7 : 55|8@0+ (1,-40) [1|1] "⊥"  BMS
 SG_ BMU28_Temp_8 : 63|8@0+ (1,-40) [1|1] "⊥"  BMS

BO_ 2415984668 BMU28_Temp_9: 8 BMU
 SG_ BMU28_Temp_9 : 7|8@0+ (1,-40) [1|1] "⊥"  BMS
 SG_ BMU28_Temp_10 : 15|8@0+ (1,-40) [1|1] "⊥"  BMS
 SG_ BMU28_Temp_11 : 23|8@0+ (1,-40) [1|1] "⊥"  BMS
 SG_ BMU28_Temp_12 : 31|8@0+ (1,-40) [1|1] "⊥"  BMS
 SG_ BMU28_Temp_13 : 39|8@0+ (1,-40) [1|1] "⊥"  BMS
 SG_ BMU28_Temp_14 : 47|8@0+ (1,-40) [1|1] "⊥"  BMS
 SG_ BMU28_Temp_15 : 55|8@0+ (1,-40) [1|1] "⊥"  BMS
 SG_ BMU28_Temp_16 : 63|8@0+ (1,-40) [1|1] "⊥"  BMS

BO_ 2416050204 BMU28_Temp_17: 8 BMU
 SG_ BMU28_Temp_17 : 7|8@0+ (1,-40) [1|1] "⊥"  BMS
 SG_ BMU28_Temp_18 : 15|8@0+ (1,-40) [1|1] "⊥"  BMS
 SG_ BMU28_Temp_19 : 23|8@0+ (1,-40) [1|1] "⊥"  BMS
 SG_ BMU28_Temp_20 : 31|8@0+ (1,-40) [1|1] "⊥"  BMS
 SG_ BMU28_Temp_21 : 39|8@0+ (1,-40) [1|1] "⊥"  BMS
 SG_ BMU28_Temp_22 : 47|8@0+ (1,-40) [1|1] "⊥"  BMS
 SG_ BMU28_Temp_23 : 55|8@0+ (1,-40) [1|1] "⊥"  BMS
 SG_ BMU28_Temp_24 : 63|8@0+ (1,-40) [1|1] "⊥"  BMS

BO_ 2415919133 BMU29_Temp_1: 8 BMU
 SG_ BMU29_Temp_1 : 7|8@0+ (1,-40) [1|1] "⊥"  BMS
 SG_ BMU29_Temp_2 : 15|8@0+ (1,-40) [1|1] "⊥"  BMS
 SG_ BMU29_Temp_3 : 23|8@0+ (1,-40) [1|1] "⊥"  BMS
 SG_ BMU29_Temp_4 : 31|8@0+ (1,-40) [1|1] "⊥"  BMS
 SG_ BMU29_Temp_5 : 39|8@0+ (1,-40) [1|1] "⊥"  BMS
 SG_ BMU29_Temp_6 : 47|8@0+ (1,-40) [1|1] "⊥"  BMS
 SG_ BMU29_Temp_7 : 55|8@0+ (1,-40) [1|1] "⊥"  BMS
 SG_ BMU29_Temp_8 : 63|8@0+ (1,-40) [1|1] "⊥"  BMS

BO_ 2415984669 BMU29_Temp_9: 8 BMU
 SG_ BMU29_Temp_9 : 7|8@0+ (1,-40) [1|1] "⊥"  BMS
 SG_ BMU29_Temp_10 : 15|8@0+ (1,-40) [1|1] "⊥"  BMS
 SG_ BMU29_Temp_11 : 23|8@0+ (1,-40) [1|1] "⊥"  BMS
 SG_ BMU29_Temp_12 : 31|8@0+ (1,-40) [1|1] "⊥"  BMS
 SG_ BMU29_Temp_13 : 39|8@0+ (1,-40) [1|1] "⊥"  BMS
 SG_ BMU29_Temp_14 : 47|8@0+ (1,-40) [1|1] "⊥"  BMS
 SG_ BMU29_Temp_15 : 55|8@0+ (1,-40) [1|1] "⊥"  BMS
 SG_ BMU29_Temp_16 : 63|8@0+ (1,-40) [1|1] "⊥"  BMS

BO_ 2416050205 BMU29_Temp_17: 8 BMU
 SG_ BMU29_Temp_17 : 7|8@0+ (1,-40) [1|1] "⊥"  BMS
 SG_ BMU29_Temp_18 : 15|8@0+ (1,-40) [1|1] "⊥"  BMS
 SG_ BMU29_Temp_19 : 23|8@0+ (1,-40) [1|1] "⊥"  BMS
 SG_ BMU29_Temp_20 : 31|8@0+ (1,-40) [1|1] "⊥"  BMS
 SG_ BMU29_Temp_21 : 39|8@0+ (1,-40) [1|1] "⊥"  BMS
 SG_ BMU29_Temp_22 : 47|8@0+ (1,-40) [1|1] "⊥"  BMS
 SG_ BMU29_Temp_23 : 55|8@0+ (1,-40) [1|1] "⊥"  BMS
 SG_ BMU29_Temp_24 : 63|8@0+ (1,-40) [1|1] "⊥"  BMS

BO_ 2415919134 BMU30_Temp_1: 8 BMU
 SG_ BMU30_Temp_1 : 7|8@0+ (1,-40) [1|1] "⊥"  BMS
 SG_ BMU30_Temp_2 : 15|8@0+ (1,-40) [1|1] "⊥"  BMS
 SG_ BMU30_Temp_3 : 23|8@0+ (1,-40) [1|1] "⊥"  BMS
 SG_ BMU30_Temp_4 : 31|8@0+ (1,-40) [1|1] "⊥"  BMS
 SG_ BMU30_Temp_5 : 39|8@0+ (1,-40) [1|1] "⊥"  BMS
 SG_ BMU30_Temp_6 : 47|8@0+ (1,-40) [1|1] "⊥"  BMS
 SG_ BMU30_Temp_7 : 55|8@0+ (1,-40) [1|1] "⊥"  BMS
 SG_ BMU30_Temp_8 : 63|8@0+ (1,-40) [1|1] "⊥"  BMS

BO_ 2415984670 BMU30_Temp_9: 8 BMU
 SG_ BMU30_Temp_9 : 7|8@0+ (1,-40) [1|1] "⊥"  BMS
 SG_ BMU30_Temp_10 : 15|8@0+ (1,-40) [1|1] "⊥"  BMS
 SG_ BMU30_Temp_11 : 23|8@0+ (1,-40) [1|1] "⊥"  BMS
 SG_ BMU30_Temp_12 : 31|8@0+ (1,-40) [1|1] "⊥"  BMS
 SG_ BMU30_Temp_13 : 39|8@0+ (1,-40) [1|1] "⊥"  BMS
 SG_ BMU30_Temp_14 : 47|8@0+ (1,-40) [1|1] "⊥"  BMS
 SG_ BMU30_Temp_15 : 55|8@0+ (1,-40) [1|1] "⊥"  BMS
 SG_ BMU30_Temp_16 : 63|8@0+ (1,-40) [1|1] "⊥"  BMS

BO_ 2416050206 BMU30_Temp_17: 8 BMU
 SG_ BMU30_Temp_17 : 7|8@0+ (1,-40) [1|1] "⊥"  BMS
 SG_ BMU30_Temp_18 : 15|8@0+ (1,-40) [1|1] "⊥"  BMS
 SG_ BMU30_Temp_19 : 23|8@0+ (1,-40) [1|1] "⊥"  BMS
 SG_ BMU30_Temp_20 : 31|8@0+ (1,-40) [1|1] "⊥"  BMS
 SG_ BMU30_Temp_21 : 39|8@0+ (1,-40) [1|1] "⊥"  BMS
 SG_ BMU30_Temp_22 : 47|8@0+ (1,-40) [1|1] "⊥"  BMS
 SG_ BMU30_Temp_23 : 55|8@0+ (1,-40) [1|1] "⊥"  BMS
 SG_ BMU30_Temp_24 : 63|8@0+ (1,-40) [1|1] "⊥"  BMS
